[part 1 of 2: packages /CAN4/ISignalGroup to /CAN4/Cluster]
AUTOSAR XML (schema 4-3-0)
package /CAN4/ISignalGroup
  24 x i signal group:
    CAN4_SG_DKC1: i-signal=[CAN4_DKC_P_BLE_RSSI, CAN4_DKC_P_UID_BatVolt, CAN4_DKC_Re_VehData, CAN4_DKC_Remote_PW, CAN4_P_CommandToBCM, CAN4_P_CommandToPTG, CAN4_P_DKey_Area_LockUnlock, CAN4_P_DKey_Area_PS, CAN4_P_DKey_Area_PTG, CAN4_P_DKey_Welcome, CAN4_P_Dkey_Show_IVI, CAN4_P_KeyMiss, CAN4_P_KeyMode, CAN4_P_UID_LowPower], system-signal-group=CAN4_SG_DKC1
    CAN4_SG_DKC2: i-signal=[CAN4_EncryptionDATA_0_63, CAN4_EncryptionDATA_64_127, CAN4_Random_Number_X], system-signal-group=CAN4_SG_DKC2
    CAN4_SG_FD4_CE100_2: i-signal=[CAN4_FD4_CE100_2_CS, CAN4_FD4_CE100_2_RC, CAN4_FDC_VCU_ReqHWReset_Cmd], system-signal-group=CAN4_SG_FD4_CE100_2
    CAN4_SG_FD_DKC1: i-signal=[CAN4_Approach_Unlock_SW, CAN4_BrkPedalPos, CAN4_BrkPedalPos_Sta, CAN4_BrkSw_Sta, CAN4_BrkSw_V, CAN4_DSEAT_anti_set, CAN4_DSEAT_entryfun_set, CAN4_DSEAT_vent_req, CAN4_FDC_BCM_ATCtrl_Cmd, CAN4_FDC_BCM_LockAlarm_Cmd, CAN4_FDC_BCM_OutMode_Cmd, CAN4_FDC_THCM_ACTInitial_Cmd, CAN4_HeadLampSW, CAN4_Hood_Latch_SW, CAN4_IVI_ISA_OffsetSpd, CAN4_IVI_Located_STA, CAN4_IVI_PTG_Mode_SW, CAN4_IVI_PTG_Open_Height, CAN4_IVI_PTG_Sta_SW, CAN4_IVI_PTG_USSta_SW, CAN4_IVI_Time_Check, CAN4_IVI_Time_Day, CAN4_IVI_Time_Hour, CAN4_IVI_Time_Minute, CAN4_IVI_Time_Month, CAN4_IVI_Time_Second, CAN4_IVI_Time_Year, CAN4_L_Drv_CtrlCmd, CAN4_L_Pas_CtrlCmd, CAN4_L_RLD_CtrlCmd, CAN4_L_RRD_CtrlCmd, CAN4_MCPressure, CAN4_MCPressure_V, CAN4_OFF_AC_MODE, CAN4_PSEAT_vent_req, CAN4_PTG_Inner_SW2, CAN4_SenstivityPosition, CAN4_TurnSwTimeSet, CAN4_Walkaway_Lock_SW], system-signal-group=CAN4_SG_FD_DKC1
    CAN4_SG_FD_OTA1: i-signal=[CAN4_OTA_DL_Available, CAN4_OTA_DL_Speed, CAN4_OTA_InVehicle_FW, CAN4_OTA_Lock_Req, CAN4_OTA_MDA_Status, CAN4_OTA_Mode, CAN4_OTA_Network_Type, CAN4_OTA_Progress_Rate, CAN4_OTA_TBOXResetReq, CAN4_OTA_Up_Backcount, CAN4_OTA_Update_Available, CAN4_OTA_Updating_ECU], system-signal-group=CAN4_SG_FD_OTA1
    CAN4_SG_FD_THCM1: i-signal=[CAN4_BatteryMode, CAN4_CCU_ACLampSts, CAN4_CCU_ACMaxLampSts, CAN4_CCU_AutoLampSts, CAN4_CCU_AutoMidLampSts, CAN4_CCU_Dispaly_Request, CAN4_CCU_EcoSts, CAN4_CCU_FrtOnOffLampSts, CAN4_CCU_HEATMaxLampSts, CAN4_CCU_RrOnOffLampSts, CAN4_CCU_SyncLampSts, CAN4_CabinMode, CAN4_EDriveMode, CAN4_FD_AGS_Cmd, CAN4_FD_RecyAuto_Cmd, CAN4_Fr_Coolantflow, CAN4_Fr_Coolanttemp, CAN4_HPThermalRecoveryReq, CAN4_Rr_Coolantflow, CAN4_Rr_Coolanttemp, CAN4_sigAirIntenZon1St, CAN4_sigAirIntenZon3St, CAN4_sigAmbAirT, CAN4_sigCbnAirT, CAN4_sigCbnPTCPwrAct, CAN4_sigCbnSolarLeft, CAN4_sigCbnSolarRight, CAN4_sigClmtCmprPwrAct, CAN4_sigClntTHvBattOut, CAN4_sigDfrstSt, CAN4_sigHvacSt, CAN4_sigRecircSt, CAN4_sigSetTempZon1St, CAN4_sigSetTempZon2St, CAN4_sigSetTempZon3St, CAN4_sigWindDirZon1St, CAN4_sigWindDirZon3St], system-signal-group=CAN4_SG_FD_THCM1
    CAN4_SG_FD_THCM2: i-signal=[CAN4_ACSubMode, CAN4_APTC_ActFrRiPwr, CAN4_BatLoopActWtFlw, CAN4_CCU_CbnPreACWkSts, CAN4_CCU_CbnPreEstimdTi, CAN4_CCU_CbnPreSts, CAN4_CCU_HiVoltageReq, CAN4_CoolgFanActDuty, CAN4_DeiceModReq, CAN4_FD_Blower_Cmd, CAN4_FD_Comp_Cmd, CAN4_FD_EWP1_Cmd, CAN4_FD_EWP2_Cmd, CAN4_FD_EWP3_Cmd, CAN4_FD_EXV1_Cmd, CAN4_FD_EXV2_Cmd, CAN4_FD_FWV_Cmd, CAN4_FD_FrLeAPTCHeatPwr_Cmd, CAN4_FD_FrRiAPTCHeatPwr_Cmd, CAN4_FD_FrWPTCHeatPwr_Cmd, CAN4_FD_RrAPTCHeatPwr_Cmd, CAN4_FD_SOTXV_Cmd, CAN4_FD_SOV1_Cmd, CAN4_FD_SOV2_Cmd, CAN4_FD_SOV3_Cmd, CAN4_FD_TWV_Cmd], system-signal-group=CAN4_SG_FD_THCM2
    CAN4_SG_FD_VCU1: i-signal=[CAN4_AllDoorSW, CAN4_AmbLightBreath1, CAN4_AmbLightBreath2, CAN4_AmbLightBreath3, CAN4_AmbLightBrightness1, CAN4_AmbLightBrightness2, CAN4_AmbLightBrightness3, CAN4_AmbLightColor1, CAN4_AmbLightColor2, CAN4_AmbLightColor3, CAN4_AntiTheftSeatFold, CAN4_AntitheftSta, CAN4_BCM_Buzzer_Req, CAN4_BCM_DoorLock_Sta, CAN4_BrakeLamp, CAN4_CC_Crl_Sta, CAN4_CS_VCU1_CAN4, CAN4_CTDCtrl, CAN4_CTDLockSW, CAN4_CTDUnlockSW, CAN4_CrashDetd, CAN4_CtrlDrPwrStbA2, CAN4_CtrlFrBMSCCUCIR, CAN4_CtrlFrEDUINVERTER, CAN4_CtrlFrIRC1, CAN4_CtrlFrPwrStbA1P, CAN4_DKCAuthSta, CAN4_DKCTimeSN, CAN4_Dimmer, CAN4_DimmerEN, CAN4_DoorLockIND, CAN4_DrDoorSW, CAN4_Dr_SeatSta, CAN4_EquivAccPedalSWSta, CAN4_FD_DKC_VehData_Err, CAN4_FD_DKC_VehData_Sta, CAN4_FD_TBOX_DTCData_Err, CAN4_FD_TBOX_DTCData_Sta, CAN4_FD_TBOX_VehData_Err, CAN4_FD_TBOX_VehData_Sta, CAN4_Fr_ChargingDoorCtrl, CAN4_Fr_FogLamp, CAN4_Fr_Wiper_H, CAN4_Fr_Wiper_L, CAN4_HWResetSta, CAN4_H_Beam, CAN4_HazardSW, CAN4_HoodSW, CAN4_HornCtrl, CAN4_LBSD, CAN4_LDRL, CAN4_LTurnLP, CAN4_L_APM_WdwEnable, CAN4_L_Beam, CAN4_LampPwr, CAN4_LockSetting, CAN4_MSA_Crl_Sta, CAN4_MirrorCtrl, CAN4_MirrorDefog, CAN4_PosLamp, CAN4_PsDoorSW, CAN4_PwrSta, CAN4_RBSD, CAN4_RC_VCU1_CAN4, CAN4_RDRL, CAN4_RLDoorSW, CAN4_RRDoorSW, CAN4_RTurnLP, CAN4_ReBrakeLPReq, CAN4_ReverseLamp, CAN4_RoomLampH, CAN4_RoomLampL, CAN4_Rr_ChargingDoorCtrl, CAN4_Rr_Defog, CAN4_Rr_FogLamp, CAN4_Rr_Wiper, CAN4_ShiftGearPosn, CAN4_TailgateHDSW, CAN4_TailgateRemote, CAN4_Tailgate_SW, CAN4_TimeSNDKCFbk, CAN4_TrunkRel, CAN4_VehSpeed, CAN4_WasherCtrl, CAN4_WiperFixMode], system-signal-group=CAN4_SG_FD_VCU1
    CAN4_SG_GW_ZDR_PTG1: i-signal=[CAN4_PTG_Active_Sta, CAN4_PTG_AutoStaus, CAN4_PTG_Cinch_Current, CAN4_PTG_Exist, CAN4_PTG_Full_Lock, CAN4_PTG_HW_Ver, CAN4_PTG_Half_Lock, CAN4_PTG_Inner_SW_1, CAN4_PTG_Is_Set_Height, CAN4_PTG_Open_Ratio, CAN4_PTG_RDIL_Sta, CAN4_PTG_SW_Ver, CAN4_PTG_Strut_Current, CAN4_PTG_Sys_Sta, CAN4_PTG_Warning_Sta], system-signal-group=CAN4_SG_GW_ZDR_PTG1
    CAN4_SG_GW_ZoneDR1: i-signal=[CAN4_AllLockSta, CAN4_AutoLightSW, CAN4_BrakeLampFail, CAN4_CSW_DimSw, CAN4_CSW_FWasSw_Sta, CAN4_CSW_FWipSw_Sta, CAN4_CSW_HW_version, CAN4_CSW_PassSW_Sta, CAN4_CSW_RWasSW_Sta, CAN4_CSW_RWipIntSw_Sta, CAN4_CSW_SW_version, CAN4_CSW_TurnSw_Sta, CAN4_CSW_resp_error, CAN4_DrLockSta, CAN4_HornSW, CAN4_MIRROR_FOLD_SW, CAN4_PsLockSta, CAN4_RLLockSta, CAN4_RLS_Exist, CAN4_RLS_LIN_Resp_Err, CAN4_RLS_Lamp_Sta, CAN4_RLS_LightSnrErr, CAN4_RLS_RainSnrErr, CAN4_RLS_RainSnrWiperCmd, CAN4_RLTurnLampC, CAN4_RRLockSta, CAN4_RRTurnLampC, CAN4_RWiperAS, CAN4_RWiperProtection, CAN4_Wip_Speed, CAN4_WiperSWPos, CAN4_WiperZeroPosSW], system-signal-group=CAN4_SG_GW_ZoneDR1
    CAN4_SG_GW_ZoneDR2: i-signal=[CAN4_SWC_ACC_Sta, CAN4_SWC_A_HW_version, CAN4_SWC_A_Resp_Err, CAN4_SWC_A_SW_version, CAN4_SWC_CANCEL_Sta, CAN4_SWC_Distance_Sta, CAN4_SWC_Down_Sta, CAN4_SWC_Drivemode_Sta, CAN4_SWC_LKA_Sta, CAN4_SWC_Left_Sta, CAN4_SWC_RegenDown, CAN4_SWC_RegenUp, CAN4_SWC_Res_Up_Sta, CAN4_SWC_Right_Sta, CAN4_SWC_Set_down_Sta, CAN4_SWC_Trip_Sta, CAN4_SWC_Undefined_Sta, CAN4_SWC_Up_Sta, CAN4_SWC_VR_Sta, CAN4_SWC_mode_Sta, CAN4_SWC_resp_error], system-signal-group=CAN4_SG_GW_ZoneDR2
    CAN4_SG_GW_ZoneDR3: i-signal=[CAN4_FAPWL_01_LIN_Response_Error, CAN4_L_APM_IntellectClose, CAN4_L_Drv_Motor_Relay_Error, CAN4_L_Drv_Motor_Ripple_Error, CAN4_L_Drv_OverHeat_Protect, CAN4_L_Drv_Val_Wdw_Opened, CAN4_L_Drv_Wdw_Init, CAN4_L_Drv_Wdw_LocalSwitch, CAN4_L_Drv_Wdw_OD_Sts, CAN4_L_Drv_Wdw_Obs_InhibitSts, CAN4_L_Drv_Wdw_Pas_Switch, CAN4_L_Drv_Wdw_PositionSts, CAN4_L_Drv_Wdw_RLD_Switch, CAN4_L_Drv_Wdw_RRD_Switch, CAN4_L_Drv_Wdw_Running_Sts, CAN4_L_Pas_Motor_Relay_Error, CAN4_L_Pas_Motor_Ripple_Error, CAN4_L_Pas_OverHeat_Protect, CAN4_L_Pas_Val_Wdw_Opened, CAN4_L_Pas_Wdw_Init, CAN4_L_Pas_Wdw_LocalSwitch, CAN4_L_Pas_Wdw_OD_Sts, CAN4_L_Pas_Wdw_Obs_InhibitSts, CAN4_L_Pas_Wdw_PositionSts, CAN4_L_Pas_Wdw_Running_Sts, CAN4_L_Power_Status], system-signal-group=CAN4_SG_GW_ZoneDR3
    CAN4_SG_GW_ZoneDR4: i-signal=[CAN4_L_RLD_Motor_Relay_Error, CAN4_L_RLD_Motor_Ripple_Error, CAN4_L_RLD_OverHeat_Protect, CAN4_L_RLD_Val_Wdw_Opened, CAN4_L_RLD_Wdw_Init, CAN4_L_RLD_Wdw_LocalSwitch, CAN4_L_RLD_Wdw_OD_Sts, CAN4_L_RLD_Wdw_Obs_InhibitSts, CAN4_L_RLD_Wdw_PositionSts, CAN4_L_RLD_Wdw_Running_Sts, CAN4_L_RRD_Motor_Relay_Error, CAN4_L_RRD_Motor_Ripple_Error, CAN4_L_RRD_OverHeat_Protect, CAN4_L_RRD_Val_Wdw_Opened, CAN4_L_RRD_Wdw_Init, CAN4_L_RRD_Wdw_LocalSwitch, CAN4_L_RRD_Wdw_OD_Sts, CAN4_L_RRD_Wdw_Obs_InhibitSts, CAN4_L_RRD_Wdw_PositionSts, CAN4_L_RRD_Wdw_Running_Sts, CAN4_PTG_Inner_SW_2, CAN4_RAPWL_01_LIN_Response_Error], system-signal-group=CAN4_SG_GW_ZoneDR4
    CAN4_SG_GW_ZoneDR6: i-signal=[CAN4_FrntPTCBusLineHiV, CAN4_FrntPTCComFlt, CAN4_FrntPTCFltSt, CAN4_FrntPTCHVOverUFlt, CAN4_FrntPTCHVUnderUFlt, CAN4_FrntPTCHWVers, CAN4_FrntPTCLVOverUFlt, CAN4_FrntPTCLVUnderUFlt, CAN4_FrntPTCLeActHeatPwr, CAN4_FrntPTCLeBusLineC, CAN4_FrntPTCLeCoreOverTFlt, CAN4_FrntPTCLeCoreT, CAN4_FrntPTCLeCoreTSnsrFlt, CAN4_FrntPTCLeIGBTOverTFlt, CAN4_FrntPTCLeIGBTShoCircFlt, CAN4_FrntPTCLeIGBTT, CAN4_FrntPTCLeIGBTTSnsrFlt, CAN4_FrntPTCLeOpentCircFlt, CAN4_FrntPTCLeOverAFlt, CAN4_FrntPTCPCBOverTFlt, CAN4_FrntPTCPCBT, CAN4_FrntPTCPCBTSnsrFlt, CAN4_FrntPTCRearLeActHeatPwr, CAN4_FrntPTCRearLeBusLineC, CAN4_FrntPTCRearLeCoreOverTFlt, CAN4_FrntPTCRearLeCoreT, CAN4_FrntPTCRearLeCoreTSnsrFlt, CAN4_FrntPTCRearLeIGBTShoCFlt, CAN4_FrntPTCRearLeOpentCircFlt, CAN4_FrntPTCRearLeOverAFlt, CAN4_FrntPTCRearRiActHeatPwr, CAN4_FrntPTCRearRiBusLineC, CAN4_FrntPTCRearRiCoreOverTFlt, CAN4_FrntPTCRearRiCoreT, CAN4_FrntPTCRearRiCoreTSnsrFlt, CAN4_FrntPTCRearRiIGBTShoCFlt, CAN4_FrntPTCRearRiOpentCircFlt, CAN4_FrntPTCRearRiOverAFlt, CAN4_FrntPTCRiActHeatPwr, CAN4_FrntPTCRiBusLineC, CAN4_FrntPTCRiCoreOverTFlt, CAN4_FrntPTCRiCoreT, CAN4_FrntPTCRiCoreTSnsrFlt, CAN4_FrntPTCRiIGBTOverTFlt, CAN4_FrntPTCRiIGBTShoCircFlt, CAN4_FrntPTCRiIGBTT, CAN4_FrntPTCRiIGBTTSnsrFlt, CAN4_FrntPTCRiOpentCircFlt, CAN4_FrntPTCRiOverAFlt, CAN4_FrntPTCSWVers, CAN4_FrntPTCSts, CAN4_FrntPTCSupplierCod], system-signal-group=CAN4_SG_GW_ZoneDR6
    CAN4_SG_GW_ZoneFR1: i-signal=[CAN4_AGS_Actual_Position, CAN4_AGS_Actuator_Blocked, CAN4_AGS_Actuator_Fault, CAN4_AGS_Calibration_Active, CAN4_AGS_Calibration_Enabled, CAN4_AGS_Calibration_Indicated, CAN4_AGS_Electrical_Error, CAN4_AGS_LINResponse_Error, CAN4_AGS_Low_Voltage_Error, CAN4_AGS_Position_Request, CAN4_AGS_Sensor_Error, CAN4_AGS_Temperature_Error, CAN4_BDC_1_MoveEnable, CAN4_BDC_1_ReqMovePos, CAN4_CCV4_MoveEnable, CAN4_CCV4_ReqMovePos, CAN4_ChargeInletLockSta, CAN4_EWP1_Default_Operation_EWP_Rq, CAN4_EWP1_RPM_Target_EWP_Rq, CAN4_EWP2_Default_Operation_EWP_Rq, CAN4_EWP2_RPM_Target_EWP_Rq, CAN4_EWP3_Default_Operation_EWP_Rq, CAN4_EWP3_RPM_Target_EWP_Rq, CAN4_EXV2_Cmd_Init_Rq, CAN4_EXV2_Cmd_Move_Enbl, CAN4_EXV2_Cmd_Set_Rq, CAN4_EXV_Cmd_Init_Rq, CAN4_EXV_Cmd_Move_Enbl, CAN4_EXV_Cmd_Set_Rq, CAN4_FLTurnLampC, CAN4_FRTurnLampC, CAN4_FWiperAS, CAN4_FWiperProtection], system-signal-group=CAN4_SG_GW_ZoneFR1
    CAN4_SG_GW_ZoneFR2: i-signal=[CAN4_BMSPackVol_h6HSC6, CAN4_CCM_SpdCmd, CAN4_COMP_ComLost, CAN4_COMP_ConCur, CAN4_COMP_ConVolt, CAN4_COMP_CtrlCircFlt, CAN4_COMP_CurOverProtect, CAN4_COMP_CurVaild, CAN4_COMP_IPM_HWFLt, CAN4_COMP_IPM_TempOverFlt, CAN4_COMP_Init, CAN4_COMP_SpdVaild, CAN4_COMP_Sta, CAN4_COMP_StatorSpd, CAN4_COMP_VoltLessErr, CAN4_COMP_VoltOverErr, CAN4_COMP_VoltVaild, CAN4_CompProEN, CAN4_EAC_DrvVoltFalt, CAN4_EAC_MotCrt, CAN4_EAC_MotorLackFalt, CAN4_EAC_OvLoadFalt, CAN4_EAC_Temp, CAN4_EAC_TempSnsrFalt, CAN4_PTCActuCrntHSC6, CAN4_PTCActuPWMDutyHSC6, CAN4_PTCActuVolHSC6, CAN4_PTCChksmHSC6, CAN4_PTCFltLvlHSC6, CAN4_PTCHVLckStsHSC6, CAN4_PTCIGBTOverHeatHSC6, CAN4_PTCIGBTStsHSC6, CAN4_PTCIGBTTemHSC6, CAN4_PTCNTCStsHSC6, CAN4_PTCOtptTemHSC6, CAN4_PTCOverCrntHSC6, CAN4_PTCOverHeatHSC6, CAN4_PTCOverVolHSC6, CAN4_PTCPCBTemHSC6, CAN4_PTCRlngCtrHSC6, CAN4_PTCSecChksmHSC6, CAN4_PTCSecRlngCtrHSC6, CAN4_PTCStsHSC6, CAN4_PTCUnderVolHSC6], system-signal-group=CAN4_SG_GW_ZoneFR2
    CAN4_SG_XNMm_DKC: i-signal=[CAN4_NM_DKC_Active_WU, CAN4_NM_DKC_CSB, CAN4_NM_DKC_ERROR_State, CAN4_NM_DKC_Node_ID, CAN4_NM_DKC_PNI, CAN4_NM_DKC_Rpt_Msg_Req], system-signal-group=CAN4_SG_XNMm_DKC
    CAN4_SG_XNMm_FUSION: i-signal=[CAN4_NM_FUSION_Active_WU, CAN4_NM_FUSION_CSB, CAN4_NM_FUSION_ERROR_State, CAN4_NM_FUSION_Node_ID, CAN4_NM_FUSION_PNI, CAN4_NM_FUSION_Rpt_Msg_Req], system-signal-group=CAN4_SG_XNMm_FUSION
    CAN4_SG_XNMm_ZONE_DR: i-signal=[CAN4_NM_ZONE_DR_Active_WU, CAN4_NM_ZONE_DR_CSB, CAN4_NM_ZONE_DR_ERROR_State, CAN4_NM_ZONE_DR_Node_ID, CAN4_NM_ZONE_DR_PNI, CAN4_NM_ZONE_DR_Rpt_Msg_Req], system-signal-group=CAN4_SG_XNMm_ZONE_DR
    CAN4_SG_XNMm_ZONE_FR: i-signal=[CAN4_NM_ZONE_FR_Active_WU, CAN4_NM_ZONE_FR_CSB, CAN4_NM_ZONE_FR_ERROR_State, CAN4_NM_ZONE_FR_Node_ID, CAN4_NM_ZONE_FR_PNI, CAN4_NM_ZONE_FR_Rpt_Msg_Req], system-signal-group=CAN4_SG_XNMm_ZONE_FR
    CAN4_SG_Zone_Dr_SCP: i-signal=[CAN4_DrSCPSysErrLmp, CAN4_RegenMode, CAN4_Set_Spd, CAN4_Zone_Spd_Ctrl_Mode, CAN4_Zone_Spd_Ctrl_Sta], system-signal-group=CAN4_SG_Zone_Dr_SCP
    CAN4_SG_Zone_Dr_THCM: i-signal=[CAN4_APTC_Err, CAN4_Blower_Err, CAN4_Blower_FB, CAN4_SolarL, CAN4_SolarL_Err, CAN4_SolarR, CAN4_SolarR_Err, CAN4_T_Face_L, CAN4_T_Face_L_Err, CAN4_T_Face_R, CAN4_T_Face_R_Err, CAN4_T_Face_Rr, CAN4_T_Face_Rr_Err, CAN4_T_Foot_L, CAN4_T_Foot_L_Err, CAN4_T_Foot_R, CAN4_T_Foot_R_Err, CAN4_T_Foot_Rr, CAN4_T_Foot_Rr_Err, CAN4_Tevap, CAN4_Tevap_Err, CAN4_Tincar, CAN4_Tincar_Err, CAN4_ZDR_THCM_IntakeFail_Sta, CAN4_ZDR_THCM_LINACT1_Sta, CAN4_ZDR_THCM_LINACT2_Sta, CAN4_ZDR_THCM_LINACT3_Sta, CAN4_ZDR_THCM_LINACT4_Sta, CAN4_ZDR_THCM_LINACT5_Sta, CAN4_ZDR_THCM_ModeFail_Sta], system-signal-group=CAN4_SG_Zone_Dr_THCM
    CAN4_SG_Zone_Dr_VCU: i-signal=[CAN4_DrAPWLINErr, CAN4_DrAPWStaErr, CAN4_DrAuBoxPwrN1Curr, CAN4_DrAuBoxPwrN2Curr, CAN4_DrColumnSWFault, CAN4_DrCtrlBDVolt, CAN4_DrCtrlTemp, CAN4_DrEOBDFault, CAN4_DrIVIFault, CAN4_DrInfoErrSta, CAN4_DrInfoFault, CAN4_DrONA1ErrSta, CAN4_DrPMMLVOutPErrLmp, CAN4_DrPMMLimpHomeActReq, CAN4_DrPMMSysErrLmp, CAN4_DrPowerTemp1, CAN4_DrPowerTemp2, CAN4_DrPwrInformationSta, CAN4_DrPwrONA1Curr, CAN4_DrPwrONA2Curr, CAN4_DrPwrSta, CAN4_DrPwrStdbyACurr, CAN4_DrPwrWinErrSta, CAN4_DrPwrWindowECUFault, CAN4_DrStdAErrSta, CAN4_DrTHCMFault, CAN4_ZDR_SYS_APMRetryCnt_Sta, CAN4_ZDR_SYS_BSWSleepReq_Sta, CAN4_ZDR_SYS_CSWRetryCnt_Sta, CAN4_ZDR_VCU_HWReset_Sta, CAN4_ZDR_VCU_PwrSupply_Sta, CAN4_ZoneDrMalfunLevel], system-signal-group=CAN4_SG_Zone_Dr_VCU
    CAN4_SG_Zone_Fr_THCM: i-signal=[CAN4_AGS_Err, CAN4_Bat_In_Temp, CAN4_Bat_In_Temp_Err, CAN4_Bat_Out_Temp, CAN4_Bat_Out_Temp_Err, CAN4_COMP_Err, CAN4_EACProtectEnable, CAN4_EWP1_Err, CAN4_EWP2_Err, CAN4_EWP3_Err, CAN4_EXV1_Err, CAN4_EXV2_Err, CAN4_FWV_Err, CAN4_Fan_Err, CAN4_Motor_In_Temp, CAN4_Motor_In_Temp_Err, CAN4_Motor_Out_Temp, CAN4_Motor_Out_Temp_Err, CAN4_PT_High_P, CAN4_PT_High_P_Err, CAN4_PT_High_T, CAN4_PT_High_Tact, CAN4_PT_High_Tact_Err, CAN4_PT_Low_P1, CAN4_PT_Low_P1_Err, CAN4_PT_Low_P2, CAN4_PT_Low_P2_Err, CAN4_PT_Low_T1, CAN4_PT_Low_T1_Err, CAN4_PT_Low_T2, CAN4_PT_Low_T2_Err, CAN4_SOTXV_Err, CAN4_SOV1_Err, CAN4_SOV2_Err, CAN4_SOV3_Err, CAN4_TWV_Err, CAN4_Tamb, CAN4_Tamb_Err, CAN4_WPTC_Err], system-signal-group=CAN4_SG_Zone_Fr_THCM
package /CAN4/Cluster
  can cluster CAN4: baudrate=500, can-fd-baudrate=2000
    can physical channel CAN4: comm-connectors=ConnCAN4
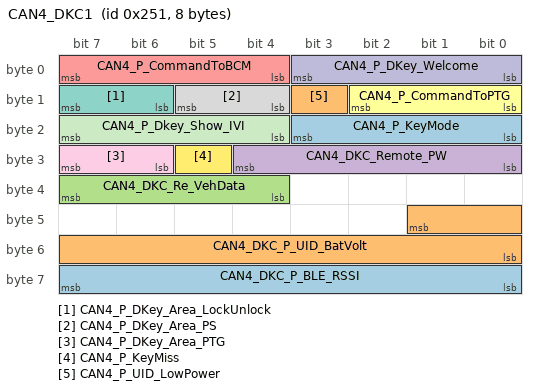
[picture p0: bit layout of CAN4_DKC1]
      frame CAN4_DKC1: id 0x251, frame-length=8, can-addressing-mode=STANDARD, can-fd-frame-support=true, can-frame-rx-behavior=CAN-FD, can-frame-tx-behavior=CAN-FD
        pdu CAN4_DKC1: length=8, minimum-delay=0.0, transmission-mode-true-timing={cyclic-timing=time-period=0.1, event-controlled-timing={number-of-repetitions=0, repetition-period=0.01}}, unused-bit-pattern=0
          mapping CAN4_SG_DKC1: i-signal-group=CAN4_SG_DKC1, start-position=0, transfer-property=TRIGGERED-ON-CHANGE
          signal CAN4_DKC_P_BLE_RSSI: start 63, 8 bit, big-endian, i-signal-type=PRIMITIVE, init-value=constant-reference=Init_CAN4_DKC_P_BLE_RSSI, base-type=uint8, implementation-data-type=uint8, transfer-property=PENDING
          signal CAN4_DKC_P_UID_BatVolt: start 41, 10 bit, big-endian, i-signal-type=PRIMITIVE, init-value=constant-reference=Init_CAN4_DKC_P_UID_BatVolt, base-type=uint16, implementation-data-type=uint16, transfer-property=PENDING
          signal CAN4_DKC_Re_VehData: start 39, 4 bit, big-endian, i-signal-type=PRIMITIVE, init-value=constant-reference=Init_CAN4_DKC_Re_VehData, base-type=uint8, implementation-data-type=uint8, transfer-property=TRIGGERED-ON-CHANGE
          signal CAN4_DKC_Remote_PW: start 28, 5 bit, big-endian, i-signal-type=PRIMITIVE, init-value=constant-reference=Init_CAN4_DKC_Remote_PW, base-type=uint8, implementation-data-type=uint8, transfer-property=PENDING
          signal CAN4_P_CommandToBCM: start 7, 4 bit, big-endian, i-signal-type=PRIMITIVE, init-value=constant-reference=Init_CAN4_P_CommandToBCM, base-type=uint8, implementation-data-type=uint8, transfer-property=PENDING
          signal CAN4_P_CommandToPTG: start 10, 3 bit, big-endian, i-signal-type=PRIMITIVE, init-value=constant-reference=Init_CAN4_P_CommandToPTG, base-type=uint8, implementation-data-type=uint8, transfer-property=PENDING
          signal CAN4_P_DKey_Area_LockUnlock: start 15, 2 bit, big-endian, i-signal-type=PRIMITIVE, init-value=constant-reference=Init_CAN4_P_DKey_Area_LockUnlock, base-type=uint8, implementation-data-type=uint8, transfer-property=PENDING
          signal CAN4_P_DKey_Area_PS: start 13, 2 bit, big-endian, i-signal-type=PRIMITIVE, init-value=constant-reference=Init_CAN4_P_DKey_Area_PS, base-type=uint8, implementation-data-type=uint8, transfer-property=PENDING
          signal CAN4_P_DKey_Area_PTG: start 31, 2 bit, big-endian, i-signal-type=PRIMITIVE, init-value=constant-reference=Init_CAN4_P_DKey_Area_PTG, base-type=uint8, implementation-data-type=uint8, transfer-property=PENDING
          signal CAN4_P_DKey_Welcome: start 3, 4 bit, big-endian, i-signal-type=PRIMITIVE, init-value=constant-reference=Init_CAN4_P_DKey_Welcome, base-type=uint8, implementation-data-type=uint8, transfer-property=PENDING
          signal CAN4_P_Dkey_Show_IVI: start 23, 4 bit, big-endian, i-signal-type=PRIMITIVE, init-value=constant-reference=Init_CAN4_P_Dkey_Show_IVI, base-type=uint8, implementation-data-type=uint8, transfer-property=PENDING
          signal CAN4_P_KeyMiss: start 29, 1 bit, big-endian, i-signal-type=PRIMITIVE, init-value=constant-reference=Init_CAN4_P_KeyMiss, base-type=uint8, implementation-data-type=uint8, transfer-property=PENDING
          signal CAN4_P_KeyMode: start 19, 4 bit, big-endian, i-signal-type=PRIMITIVE, init-value=constant-reference=Init_CAN4_P_KeyMode, base-type=uint8, implementation-data-type=uint8, transfer-property=TRIGGERED-ON-CHANGE
          signal CAN4_P_UID_LowPower: start 11, 1 bit, big-endian, i-signal-type=PRIMITIVE, init-value=constant-reference=Init_CAN4_P_UID_LowPower, base-type=uint8, implementation-data-type=uint8, transfer-property=TRIGGERED-ON-CHANGE
      frame CAN4_DKC2: id 0x252, frame-length=24, can-addressing-mode=STANDARD, can-fd-frame-support=true, can-frame-rx-behavior=CAN-FD, can-frame-tx-behavior=CAN-FD
        pdu CAN4_DKC2: length=24, minimum-delay=0.0, transmission-mode-true-timing={cyclic-timing=time-period=0.1, event-controlled-timing={number-of-repetitions=0, repetition-period=0.01}}, unused-bit-pattern=0
          mapping CAN4_SG_DKC2: i-signal-group=CAN4_SG_DKC2, start-position=0, transfer-property=TRIGGERED-ON-CHANGE
          signal CAN4_EncryptionDATA_0_63: start 135, 64 bit, big-endian, i-signal-type=PRIMITIVE, init-value=constant-reference=Init_CAN4_EncryptionDATA_0_63, base-type=uint64, implementation-data-type=uint64, transfer-property=TRIGGERED-ON-CHANGE
          signal CAN4_EncryptionDATA_64_127: start 71, 64 bit, big-endian, i-signal-type=PRIMITIVE, init-value=constant-reference=Init_CAN4_EncryptionDATA_64_127, base-type=uint64, implementation-data-type=uint64, transfer-property=TRIGGERED-ON-CHANGE
          signal CAN4_Random_Number_X: start 7, 64 bit, big-endian, i-signal-type=PRIMITIVE, init-value=constant-reference=Init_CAN4_Random_Number_X, base-type=uint64, implementation-data-type=uint64, transfer-property=TRIGGERED-ON-CHANGE
      frame CAN4_DiagFuncReqFT: id 0x7D0, frame-length=8, can-addressing-mode=STANDARD, can-fd-frame-support=true, can-frame-rx-behavior=CAN-FD, can-frame-tx-behavior=CAN-FD
        n pdu CAN4_DiagFuncReqFT: length=8
      frame CAN4_DiagPhysReqToAirPTC: id 0x6A5, frame-length=8, can-addressing-mode=STANDARD, can-fd-frame-support=true, can-frame-rx-behavior=CAN-FD, can-frame-tx-behavior=CAN-FD
        n pdu CAN4_DiagPhysReqToAirPTC: length=8
      frame CAN4_DiagPhysReqToCompressor: id 0x6C5, frame-length=8, can-addressing-mode=STANDARD, can-fd-frame-support=true, can-frame-rx-behavior=CAN-FD, can-frame-tx-behavior=CAN-FD
        n pdu CAN4_DiagPhysReqToCompressor: length=8
      frame CAN4_DiagPhysReqToDKC: id 0x685, frame-length=8, can-addressing-mode=STANDARD, can-fd-frame-support=true, can-frame-rx-behavior=CAN-FD, can-frame-tx-behavior=CAN-FD
        n pdu CAN4_DiagPhysReqToDKC: length=8
      frame CAN4_DiagPhysReqToDSEAT: id 0x694, frame-length=8, can-addressing-mode=STANDARD, can-fd-frame-support=true, can-frame-rx-behavior=CAN-FD, can-frame-tx-behavior=CAN-FD
        n pdu CAN4_DiagPhysReqToDSEAT: length=8
      frame CAN4_DiagPhysReqToPSEAT: id 0x6A4, frame-length=8, can-addressing-mode=STANDARD, can-fd-frame-support=true, can-frame-rx-behavior=CAN-FD, can-frame-tx-behavior=CAN-FD
        n pdu CAN4_DiagPhysReqToPSEAT: length=8
      frame CAN4_DiagPhysReqToPTG: id 0x6B4, frame-length=8, can-addressing-mode=STANDARD, can-fd-frame-support=true, can-frame-rx-behavior=CAN-FD, can-frame-tx-behavior=CAN-FD
        n pdu CAN4_DiagPhysReqToPTG: length=8
      frame CAN4_DiagPhysReqToZONE_DR: id 0x6C0, frame-length=64, can-addressing-mode=STANDARD, can-fd-frame-support=true, can-frame-rx-behavior=CAN-FD, can-frame-tx-behavior=CAN-FD
        n pdu CAN4_DiagPhysReqToZONE_DR: length=64
      frame CAN4_DiagPhysReqToZONE_FR: id 0x684, frame-length=64, can-addressing-mode=STANDARD, can-fd-frame-support=true, can-frame-rx-behavior=CAN-FD, can-frame-tx-behavior=CAN-FD
        n pdu CAN4_DiagPhysReqToZONE_FR: length=64
      frame CAN4_DiagRespFromAirPTC: id 0x625, frame-length=8, can-addressing-mode=STANDARD, can-fd-frame-support=true, can-frame-rx-behavior=CAN-FD, can-frame-tx-behavior=CAN-FD
        n pdu CAN4_DiagRespFromAirPTC: length=8
      frame CAN4_DiagRespFromCompressor: id 0x645, frame-length=8, can-addressing-mode=STANDARD, can-fd-frame-support=true, can-frame-rx-behavior=CAN-FD, can-frame-tx-behavior=CAN-FD
        n pdu CAN4_DiagRespFromCompressor: length=8
      frame CAN4_DiagRespFromDKC: id 0x605, frame-length=8, can-addressing-mode=STANDARD, can-fd-frame-support=true, can-frame-rx-behavior=CAN-FD, can-frame-tx-behavior=CAN-FD
        n pdu CAN4_DiagRespFromDKC: length=8
      frame CAN4_DiagRespFromDSEAT: id 0x614, frame-length=8, can-addressing-mode=STANDARD, can-fd-frame-support=true, can-frame-rx-behavior=CAN-FD, can-frame-tx-behavior=CAN-FD
        n pdu CAN4_DiagRespFromDSEAT: length=8
      frame CAN4_DiagRespFromPSEAT: id 0x624, frame-length=8, can-addressing-mode=STANDARD, can-fd-frame-support=true, can-frame-rx-behavior=CAN-FD, can-frame-tx-behavior=CAN-FD
        n pdu CAN4_DiagRespFromPSEAT: length=8
      frame CAN4_DiagRespFromPTG: id 0x634, frame-length=8, can-addressing-mode=STANDARD, can-fd-frame-support=true, can-frame-rx-behavior=CAN-FD, can-frame-tx-behavior=CAN-FD
        n pdu CAN4_DiagRespFromPTG: length=8
      frame CAN4_DiagRespFromZONE_DR: id 0x640, frame-length=64, can-addressing-mode=STANDARD, can-fd-frame-support=true, can-frame-rx-behavior=CAN-FD, can-frame-tx-behavior=CAN-FD
        n pdu CAN4_DiagRespFromZONE_DR: length=64
      frame CAN4_DiagRespFromZONE_FR: id 0x604, frame-length=64, can-addressing-mode=STANDARD, can-fd-frame-support=true, can-frame-rx-behavior=CAN-FD, can-frame-tx-behavior=CAN-FD
        n pdu CAN4_DiagRespFromZONE_FR: length=64
      frame CAN4_FD4_CE100_2: id 0x3A0, frame-length=32, can-addressing-mode=STANDARD, can-fd-frame-support=true, can-frame-rx-behavior=CAN-FD, can-frame-tx-behavior=CAN-FD
        pdu CAN4_FD4_CE100_2: length=32, minimum-delay=0.0, transmission-mode-true-timing={cyclic-timing=time-period=0.1, event-controlled-timing={number-of-repetitions=0, repetition-period=0}}, unused-bit-pattern=0
          mapping CAN4_SG_FD4_CE100_2: i-signal-group=CAN4_SG_FD4_CE100_2, start-position=0, transfer-property=TRIGGERED-ON-CHANGE
          signal CAN4_FD4_CE100_2_CS: start 7, 8 bit, big-endian, i-signal-type=PRIMITIVE, init-value=constant-reference=Init_CAN4_FD4_CE100_2_CS, base-type=uint8, implementation-data-type=uint8, transfer-property=TRIGGERED-ON-CHANGE
          signal CAN4_FD4_CE100_2_RC: start 11, 4 bit, big-endian, i-signal-type=PRIMITIVE, init-value=constant-reference=Init_CAN4_FD4_CE100_2_RC, base-type=uint8, implementation-data-type=uint8, transfer-property=TRIGGERED-ON-CHANGE
          signal CAN4_FDC_VCU_ReqHWReset_Cmd: start 20, 5 bit, big-endian, i-signal-type=PRIMITIVE, init-value=constant-reference=Init_CAN4_FDC_VCU_ReqHWReset_Cmd, base-type=uint8, implementation-data-type=uint8, transfer-property=TRIGGERED-ON-CHANGE
      frame CAN4_FD_DKC1: id 0x253, frame-length=32, can-addressing-mode=STANDARD, can-fd-frame-support=true, can-frame-rx-behavior=CAN-FD, can-frame-tx-behavior=CAN-FD
        pdu CAN4_FD_DKC1: length=32, minimum-delay=0.0, transmission-mode-true-timing={cyclic-timing=time-period=0.1, event-controlled-timing={number-of-repetitions=0, repetition-period=0.01}}, unused-bit-pattern=0
          mapping CAN4_SG_FD_DKC1: i-signal-group=CAN4_SG_FD_DKC1, start-position=0, transfer-property=TRIGGERED-ON-CHANGE
          signal CAN4_Approach_Unlock_SW: start 15, 1 bit, big-endian, i-signal-type=PRIMITIVE, init-value=constant-reference=Init_CAN4_Approach_Unlock_SW, base-type=uint8, implementation-data-type=uint8, transfer-property=TRIGGERED-ON-CHANGE
          signal CAN4_BrkPedalPos: start 135, 8 bit, big-endian, i-signal-type=PRIMITIVE, init-value=constant-reference=Init_CAN4_BrkPedalPos, base-type=uint8, implementation-data-type=uint8, transfer-property=PENDING
          signal CAN4_BrkPedalPos_Sta: start 108, 1 bit, big-endian, i-signal-type=PRIMITIVE, init-value=constant-reference=Init_CAN4_BrkPedalPos_Sta, base-type=uint8, implementation-data-type=uint8, transfer-property=TRIGGERED-ON-CHANGE
          signal CAN4_BrkSw_Sta: start 31, 1 bit, big-endian, i-signal-type=PRIMITIVE, init-value=constant-reference=Init_CAN4_BrkSw_Sta, base-type=uint8, implementation-data-type=uint8, transfer-property=TRIGGERED-ON-CHANGE
          signal CAN4_BrkSw_V: start 71, 1 bit, big-endian, i-signal-type=PRIMITIVE, init-value=constant-reference=Init_CAN4_BrkSw_V, base-type=uint8, implementation-data-type=uint8, transfer-property=TRIGGERED-ON-CHANGE
          signal CAN4_DSEAT_anti_set: start 39, 1 bit, big-endian, i-signal-type=PRIMITIVE, init-value=constant-reference=Init_CAN4_DSEAT_anti_set, base-type=uint8, implementation-data-type=uint8, transfer-property=PENDING
          signal CAN4_DSEAT_entryfun_set: start 47, 1 bit, big-endian, i-signal-type=PRIMITIVE, init-value=constant-reference=Init_CAN4_DSEAT_entryfun_set, base-type=uint8, implementation-data-type=uint8, transfer-property=PENDING
          signal CAN4_DSEAT_vent_req: start 95, 3 bit, big-endian, i-signal-type=PRIMITIVE, init-value=constant-reference=Init_CAN4_DSEAT_vent_req, base-type=uint8, implementation-data-type=uint8, transfer-property=PENDING
          signal CAN4_FDC_BCM_ATCtrl_Cmd: start 143, 2 bit, big-endian, i-signal-type=PRIMITIVE, init-value=constant-reference=Init_CAN4_FDC_BCM_ATCtrl_Cmd, base-type=uint8, implementation-data-type=uint8, transfer-property=TRIGGERED-ON-CHANGE
          signal CAN4_FDC_BCM_LockAlarm_Cmd: start 119, 2 bit, big-endian, i-signal-type=PRIMITIVE, init-value=constant-reference=Init_CAN4_FDC_BCM_LockAlarm_Cmd, base-type=uint8, implementation-data-type=uint8, transfer-property=TRIGGERED-ON-CHANGE
          signal CAN4_FDC_BCM_OutMode_Cmd: start 139, 4 bit, big-endian, i-signal-type=PRIMITIVE, init-value=constant-reference=Init_CAN4_FDC_BCM_OutMode_Cmd, base-type=uint8, implementation-data-type=uint8, transfer-property=TRIGGERED-ON-CHANGE
          signal CAN4_FDC_THCM_ACTInitial_Cmd: start 117, 1 bit, big-endian, i-signal-type=PRIMITIVE, init-value=constant-reference=Init_CAN4_FDC_THCM_ACTInitial_Cmd, base-type=uint8, implementation-data-type=uint8, transfer-property=TRIGGERED-ON-CHANGE
          signal CAN4_HeadLampSW: start 102, 2 bit, big-endian, i-signal-type=PRIMITIVE, init-value=constant-reference=Init_CAN4_HeadLampSW, base-type=uint8, implementation-data-type=uint8, transfer-property=TRIGGERED-ON-CHANGE
          signal CAN4_Hood_Latch_SW: start 79, 2 bit, big-endian, i-signal-type=PRIMITIVE, init-value=constant-reference=Init_CAN4_Hood_Latch_SW, base-type=uint8, implementation-data-type=uint8, transfer-property=PENDING
          signal CAN4_IVI_ISA_OffsetSpd: start 55, 4 bit, big-endian, i-signal-type=PRIMITIVE, init-value=constant-reference=Init_CAN4_IVI_ISA_OffsetSpd, base-type=uint8, implementation-data-type=uint8, transfer-property=PENDING
          signal CAN4_IVI_Located_STA: start 7, 2 bit, big-endian, i-signal-type=PRIMITIVE, init-value=constant-reference=Init_CAN4_IVI_Located_STA, base-type=uint8, implementation-data-type=uint8, transfer-property=PENDING
          signal CAN4_IVI_PTG_Mode_SW: start 46, 2 bit, big-endian, i-signal-type=PRIMITIVE, init-value=constant-reference=Init_CAN4_IVI_PTG_Mode_SW, base-type=uint8, implementation-data-type=uint8, transfer-property=TRIGGERED-ON-CHANGE
          signal CAN4_IVI_PTG_Open_Height: start 2, 3 bit, big-endian, i-signal-type=PRIMITIVE, init-value=constant-reference=Init_CAN4_IVI_PTG_Open_Height, base-type=uint8, implementation-data-type=uint8, transfer-property=TRIGGERED-ON-CHANGE
          signal CAN4_IVI_PTG_Sta_SW: start 41, 2 bit, big-endian, i-signal-type=PRIMITIVE, init-value=constant-reference=Init_CAN4_IVI_PTG_Sta_SW, base-type=uint8, implementation-data-type=uint8, transfer-property=TRIGGERED-ON-CHANGE
          signal CAN4_IVI_PTG_USSta_SW: start 3, 1 bit, big-endian, i-signal-type=PRIMITIVE, init-value=constant-reference=Init_CAN4_IVI_PTG_USSta_SW, base-type=uint8, implementation-data-type=uint8, transfer-property=PENDING
          signal CAN4_IVI_Time_Check: start 63, 8 bit, big-endian, i-signal-type=PRIMITIVE, init-value=constant-reference=Init_CAN4_IVI_Time_Check, base-type=uint8, implementation-data-type=uint8, transfer-property=PENDING
          signal CAN4_IVI_Time_Day: start 92, 5 bit, big-endian, i-signal-type=PRIMITIVE, init-value=constant-reference=Init_CAN4_IVI_Time_Day, base-type=uint8, implementation-data-type=uint8, transfer-property=PENDING
          signal CAN4_IVI_Time_Hour: start 100, 5 bit, big-endian, i-signal-type=PRIMITIVE, init-value=constant-reference=Init_CAN4_IVI_Time_Hour, base-type=uint8, implementation-data-type=uint8, transfer-property=PENDING
          signal CAN4_IVI_Time_Minute: start 77, 6 bit, big-endian, i-signal-type=PRIMITIVE, init-value=constant-reference=Init_CAN4_IVI_Time_Minute, base-type=uint8, implementation-data-type=uint8, transfer-property=PENDING
          signal CAN4_IVI_Time_Month: start 107, 4 bit, big-endian, i-signal-type=PRIMITIVE, init-value=constant-reference=Init_CAN4_IVI_Time_Month, base-type=uint8, implementation-data-type=uint8, transfer-property=PENDING
          signal CAN4_IVI_Time_Second: start 85, 6 bit, big-endian, i-signal-type=PRIMITIVE, init-value=constant-reference=Init_CAN4_IVI_Time_Second, base-type=uint8, implementation-data-type=uint8, transfer-property=PENDING
          signal CAN4_IVI_Time_Year: start 70, 7 bit, big-endian, i-signal-type=PRIMITIVE, init-value=constant-reference=Init_CAN4_IVI_Time_Year, base-type=uint8, implementation-data-type=uint8, transfer-property=PENDING
          signal CAN4_L_Drv_CtrlCmd: start 38, 7 bit, big-endian, i-signal-type=PRIMITIVE, init-value=constant-reference=Init_CAN4_L_Drv_CtrlCmd, base-type=uint8, implementation-data-type=uint8, transfer-property=TRIGGERED-ON-CHANGE
          signal CAN4_L_Pas_CtrlCmd: start 30, 7 bit, big-endian, i-signal-type=PRIMITIVE, init-value=constant-reference=Init_CAN4_L_Pas_CtrlCmd, base-type=uint8, implementation-data-type=uint8, transfer-property=TRIGGERED-ON-CHANGE
          signal CAN4_L_RLD_CtrlCmd: start 22, 7 bit, big-endian, i-signal-type=PRIMITIVE, init-value=constant-reference=Init_CAN4_L_RLD_CtrlCmd, base-type=uint8, implementation-data-type=uint8, transfer-property=TRIGGERED-ON-CHANGE
          signal CAN4_L_RRD_CtrlCmd: start 14, 7 bit, big-endian, i-signal-type=PRIMITIVE, init-value=constant-reference=Init_CAN4_L_RRD_CtrlCmd, base-type=uint8, implementation-data-type=uint8, transfer-property=TRIGGERED-ON-CHANGE
          signal CAN4_MCPressure: start 115, 12 bit, big-endian, i-signal-type=PRIMITIVE, init-value=constant-reference=Init_CAN4_MCPressure, base-type=uint16, implementation-data-type=uint16, transfer-property=PENDING
          signal CAN4_MCPressure_V: start 103, 1 bit, big-endian, i-signal-type=PRIMITIVE, init-value=constant-reference=Init_CAN4_MCPressure_V, base-type=uint8, implementation-data-type=uint8, transfer-property=TRIGGERED-ON-CHANGE
          signal CAN4_OFF_AC_MODE: start 111, 3 bit, big-endian, i-signal-type=PRIMITIVE, init-value=constant-reference=Init_CAN4_OFF_AC_MODE, base-type=uint8, implementation-data-type=uint8, transfer-property=TRIGGERED-ON-CHANGE
          signal CAN4_PSEAT_vent_req: start 44, 3 bit, big-endian, i-signal-type=PRIMITIVE, init-value=constant-reference=Init_CAN4_PSEAT_vent_req, base-type=uint8, implementation-data-type=uint8, transfer-property=PENDING
          signal CAN4_PTG_Inner_SW2: start 5, 2 bit, big-endian, i-signal-type=PRIMITIVE, init-value=constant-reference=Init_CAN4_PTG_Inner_SW2, base-type=uint8, implementation-data-type=uint8, transfer-property=PENDING
          signal CAN4_SenstivityPosition: start 51, 4 bit, big-endian, i-signal-type=PRIMITIVE, init-value=constant-reference=Init_CAN4_SenstivityPosition, base-type=uint8, implementation-data-type=uint8, transfer-property=PENDING
          signal CAN4_TurnSwTimeSet: start 87, 2 bit, big-endian, i-signal-type=PRIMITIVE, init-value=constant-reference=Init_CAN4_TurnSwTimeSet, base-type=uint8, implementation-data-type=uint8, transfer-property=TRIGGERED-ON-CHANGE
          signal CAN4_Walkaway_Lock_SW: start 23, 1 bit, big-endian, i-signal-type=PRIMITIVE, init-value=constant-reference=Init_CAN4_Walkaway_Lock_SW, base-type=uint8, implementation-data-type=uint8, transfer-property=TRIGGERED-ON-CHANGE
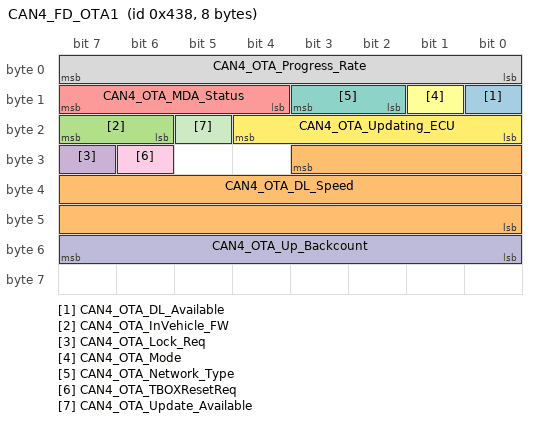
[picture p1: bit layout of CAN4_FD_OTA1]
      frame CAN4_FD_OTA1: id 0x438, frame-length=8, can-addressing-mode=STANDARD, can-fd-frame-support=true, can-frame-rx-behavior=CAN-FD, can-frame-tx-behavior=CAN-FD
        pdu CAN4_FD_OTA1: length=8, minimum-delay=0.0, transmission-mode-true-timing={cyclic-timing=time-period=0.2, event-controlled-timing={number-of-repetitions=0, repetition-period=0.02}}, unused-bit-pattern=0
          mapping CAN4_SG_FD_OTA1: i-signal-group=CAN4_SG_FD_OTA1, start-position=0, transfer-property=TRIGGERED-ON-CHANGE
          signal CAN4_OTA_DL_Available: start 8, 1 bit, big-endian, i-signal-type=PRIMITIVE, init-value=constant-reference=Init_CAN4_OTA_DL_Available, base-type=uint8, implementation-data-type=uint8, transfer-property=TRIGGERED-ON-CHANGE
          signal CAN4_OTA_DL_Speed: start 27, 20 bit, big-endian, i-signal-type=PRIMITIVE, init-value=constant-reference=Init_CAN4_OTA_DL_Speed, base-type=uint32, implementation-data-type=uint32, transfer-property=TRIGGERED-ON-CHANGE
          signal CAN4_OTA_InVehicle_FW: start 23, 2 bit, big-endian, i-signal-type=PRIMITIVE, init-value=constant-reference=Init_CAN4_OTA_InVehicle_FW, base-type=uint8, implementation-data-type=uint8, transfer-property=TRIGGERED-ON-CHANGE
          signal CAN4_OTA_Lock_Req: start 31, 1 bit, big-endian, i-signal-type=PRIMITIVE, init-value=constant-reference=Init_CAN4_OTA_Lock_Req, base-type=uint8, implementation-data-type=uint8, transfer-property=TRIGGERED-ON-CHANGE
          signal CAN4_OTA_MDA_Status: start 15, 4 bit, big-endian, i-signal-type=PRIMITIVE, init-value=constant-reference=Init_CAN4_OTA_MDA_Status, base-type=uint8, implementation-data-type=uint8, transfer-property=TRIGGERED-ON-CHANGE
          signal CAN4_OTA_Mode: start 9, 1 bit, big-endian, i-signal-type=PRIMITIVE, init-value=constant-reference=Init_CAN4_OTA_Mode, base-type=uint8, implementation-data-type=uint8, transfer-property=TRIGGERED-ON-CHANGE
          signal CAN4_OTA_Network_Type: start 11, 2 bit, big-endian, i-signal-type=PRIMITIVE, init-value=constant-reference=Init_CAN4_OTA_Network_Type, base-type=uint8, implementation-data-type=uint8, transfer-property=TRIGGERED-ON-CHANGE
          signal CAN4_OTA_Progress_Rate: start 7, 8 bit, big-endian, i-signal-type=PRIMITIVE, init-value=constant-reference=Init_CAN4_OTA_Progress_Rate, base-type=uint8, implementation-data-type=uint8, transfer-property=TRIGGERED-ON-CHANGE
          signal CAN4_OTA_TBOXResetReq: start 30, 1 bit, big-endian, i-signal-type=PRIMITIVE, init-value=constant-reference=Init_CAN4_OTA_TBOXResetReq, base-type=uint8, implementation-data-type=uint8, transfer-property=PENDING
          signal CAN4_OTA_Up_Backcount: start 55, 8 bit, big-endian, i-signal-type=PRIMITIVE, init-value=constant-reference=Init_CAN4_OTA_Up_Backcount, base-type=uint8, implementation-data-type=uint8, transfer-property=TRIGGERED-ON-CHANGE
          signal CAN4_OTA_Update_Available: start 21, 1 bit, big-endian, i-signal-type=PRIMITIVE, init-value=constant-reference=Init_CAN4_OTA_Update_Available, base-type=uint8, implementation-data-type=uint8, transfer-property=TRIGGERED-ON-CHANGE
          signal CAN4_OTA_Updating_ECU: start 20, 5 bit, big-endian, i-signal-type=PRIMITIVE, init-value=constant-reference=Init_CAN4_OTA_Updating_ECU, base-type=uint8, implementation-data-type=uint8, transfer-property=TRIGGERED-ON-CHANGE
      frame CAN4_FD_THCM1: id 0x182, frame-length=20, can-addressing-mode=STANDARD, can-fd-frame-support=true, can-frame-rx-behavior=CAN-FD, can-frame-tx-behavior=CAN-FD
        pdu CAN4_FD_THCM1: length=20, minimum-delay=0.0, transmission-mode-true-timing=cyclic-timing=time-period=0.1, unused-bit-pattern=0
          mapping CAN4_SG_FD_THCM1: i-signal-group=CAN4_SG_FD_THCM1, start-position=0, transfer-property=PENDING
          signal CAN4_BatteryMode: start 118, 3 bit, big-endian, i-signal-type=PRIMITIVE, init-value=constant-reference=Init_CAN4_BatteryMode, base-type=uint8, implementation-data-type=uint8, transfer-property=PENDING
          signal CAN4_CCU_ACLampSts: start 6, 1 bit, big-endian, i-signal-type=PRIMITIVE, init-value=constant-reference=Init_CAN4_CCU_ACLampSts, base-type=uint8, implementation-data-type=uint8, transfer-property=PENDING
          signal CAN4_CCU_ACMaxLampSts: start 1, 1 bit, big-endian, i-signal-type=PRIMITIVE, init-value=constant-reference=Init_CAN4_CCU_ACMaxLampSts, base-type=uint8, implementation-data-type=uint8, transfer-property=PENDING
          signal CAN4_CCU_AutoLampSts: start 2, 1 bit, big-endian, i-signal-type=PRIMITIVE, init-value=constant-reference=Init_CAN4_CCU_AutoLampSts, base-type=uint8, implementation-data-type=uint8, transfer-property=PENDING
          signal CAN4_CCU_AutoMidLampSts: start 3, 1 bit, big-endian, i-signal-type=PRIMITIVE, init-value=constant-reference=Init_CAN4_CCU_AutoMidLampSts, base-type=uint8, implementation-data-type=uint8, transfer-property=PENDING
          signal CAN4_CCU_Dispaly_Request: start 5, 1 bit, big-endian, i-signal-type=PRIMITIVE, init-value=constant-reference=Init_CAN4_CCU_Dispaly_Request, base-type=uint8, implementation-data-type=uint8, transfer-property=PENDING
          signal CAN4_CCU_EcoSts: start 4, 1 bit, big-endian, i-signal-type=PRIMITIVE, init-value=constant-reference=Init_CAN4_CCU_EcoSts, base-type=uint8, implementation-data-type=uint8, transfer-property=PENDING
          signal CAN4_CCU_FrtOnOffLampSts: start 19, 1 bit, big-endian, i-signal-type=PRIMITIVE, init-value=constant-reference=Init_CAN4_CCU_FrtOnOffLampSts, base-type=uint8, implementation-data-type=uint8, transfer-property=PENDING
          signal CAN4_CCU_HEATMaxLampSts: start 7, 1 bit, big-endian, i-signal-type=PRIMITIVE, init-value=constant-reference=Init_CAN4_CCU_HEATMaxLampSts, base-type=uint8, implementation-data-type=uint8, transfer-property=PENDING
          signal CAN4_CCU_RrOnOffLampSts: start 23, 1 bit, big-endian, i-signal-type=PRIMITIVE, init-value=constant-reference=Init_CAN4_CCU_RrOnOffLampSts, base-type=uint8, implementation-data-type=uint8, transfer-property=PENDING
          signal CAN4_CCU_SyncLampSts: start 39, 1 bit, big-endian, i-signal-type=PRIMITIVE, init-value=constant-reference=Init_CAN4_CCU_SyncLampSts, base-type=uint8, implementation-data-type=uint8, transfer-property=PENDING
          signal CAN4_CabinMode: start 115, 4 bit, big-endian, i-signal-type=PRIMITIVE, init-value=constant-reference=Init_CAN4_CabinMode, base-type=uint8, implementation-data-type=uint8, transfer-property=PENDING
          signal CAN4_EDriveMode: start 63, 2 bit, big-endian, i-signal-type=PRIMITIVE, init-value=constant-reference=Init_CAN4_EDriveMode, base-type=uint8, implementation-data-type=uint8, transfer-property=PENDING
          signal CAN4_FD_AGS_Cmd: start 143, 8 bit, big-endian, i-signal-type=PRIMITIVE, init-value=constant-reference=Init_CAN4_FD_AGS_Cmd, base-type=uint8, implementation-data-type=uint8, transfer-property=PENDING
          signal CAN4_FD_RecyAuto_Cmd: start 111, 3 bit, big-endian, i-signal-type=PRIMITIVE, init-value=constant-reference=Init_CAN4_FD_RecyAuto_Cmd, base-type=uint8, implementation-data-type=uint8, transfer-property=PENDING
          signal CAN4_Fr_Coolantflow: start 61, 6 bit, big-endian, i-signal-type=PRIMITIVE, init-value=constant-reference=Init_CAN4_Fr_Coolantflow, base-type=uint8, implementation-data-type=uint8, transfer-property=PENDING
          signal CAN4_Fr_Coolanttemp: start 0, 9 bit, big-endian, i-signal-type=PRIMITIVE, init-value=constant-reference=Init_CAN4_Fr_Coolanttemp, base-type=uint16, implementation-data-type=uint16, transfer-property=PENDING
          signal CAN4_HPThermalRecoveryReq: start 55, 2 bit, big-endian, i-signal-type=PRIMITIVE, init-value=constant-reference=Init_CAN4_HPThermalRecoveryReq, base-type=uint8, implementation-data-type=uint8, transfer-property=PENDING
          signal CAN4_Rr_Coolantflow: start 150, 6 bit, big-endian, i-signal-type=PRIMITIVE, init-value=constant-reference=Init_CAN4_Rr_Coolantflow, base-type=uint8, implementation-data-type=uint8, transfer-property=PENDING
          signal CAN4_Rr_Coolanttemp: start 144, 9 bit, big-endian, i-signal-type=PRIMITIVE, init-value=constant-reference=Init_CAN4_Rr_Coolanttemp, base-type=uint16, implementation-data-type=uint16, transfer-property=PENDING
          signal CAN4_sigAirIntenZon1St: start 31, 4 bit, big-endian, i-signal-type=PRIMITIVE, init-value=constant-reference=Init_CAN4_sigAirIntenZon1St, base-type=uint8, implementation-data-type=uint8, transfer-property=PENDING
          signal CAN4_sigAirIntenZon3St: start 27, 4 bit, big-endian, i-signal-type=PRIMITIVE, init-value=constant-reference=Init_CAN4_sigAirIntenZon3St, base-type=uint8, implementation-data-type=uint8, transfer-property=PENDING
          signal CAN4_sigAmbAirT: start 95, 8 bit, big-endian, i-signal-type=PRIMITIVE, init-value=constant-reference=Init_CAN4_sigAmbAirT, base-type=uint8, implementation-data-type=uint8, transfer-property=PENDING
          signal CAN4_sigCbnAirT: start 87, 8 bit, big-endian, i-signal-type=PRIMITIVE, init-value=constant-reference=Init_CAN4_sigCbnAirT, base-type=uint8, implementation-data-type=uint8, transfer-property=PENDING
          signal CAN4_sigCbnPTCPwrAct: start 79, 8 bit, big-endian, i-signal-type=PRIMITIVE, init-value=constant-reference=Init_CAN4_sigCbnPTCPwrAct, base-type=uint8, implementation-data-type=uint8, transfer-property=PENDING
          signal CAN4_sigCbnSolarLeft: start 127, 8 bit, big-endian, i-signal-type=PRIMITIVE, init-value=constant-reference=Init_CAN4_sigCbnSolarLeft, base-type=uint8, implementation-data-type=uint8, transfer-property=PENDING
          signal CAN4_sigCbnSolarRight: start 103, 8 bit, big-endian, i-signal-type=PRIMITIVE, init-value=constant-reference=Init_CAN4_sigCbnSolarRight, base-type=uint8, implementation-data-type=uint8, transfer-property=PENDING
          signal CAN4_sigClmtCmprPwrAct: start 71, 8 bit, big-endian, i-signal-type=PRIMITIVE, init-value=constant-reference=Init_CAN4_sigClmtCmprPwrAct, base-type=uint8, implementation-data-type=uint8, transfer-property=PENDING
          signal CAN4_sigClntTHvBattOut: start 135, 8 bit, big-endian, i-signal-type=PRIMITIVE, init-value=constant-reference=Init_CAN4_sigClntTHvBattOut, base-type=uint8, implementation-data-type=uint8, transfer-property=PENDING
          signal CAN4_sigDfrstSt: start 38, 1 bit, big-endian, i-signal-type=PRIMITIVE, init-value=constant-reference=Init_CAN4_sigDfrstSt, base-type=uint8, implementation-data-type=uint8, transfer-property=PENDING
          signal CAN4_sigHvacSt: start 46, 1 bit, big-endian, i-signal-type=PRIMITIVE, init-value=constant-reference=Init_CAN4_sigHvacSt, base-type=uint8, implementation-data-type=uint8, transfer-property=PENDING
          signal CAN4_sigRecircSt: start 47, 1 bit, big-endian, i-signal-type=PRIMITIVE, init-value=constant-reference=Init_CAN4_sigRecircSt, base-type=uint8, implementation-data-type=uint8, transfer-property=PENDING
          signal CAN4_sigSetTempZon1St: start 53, 6 bit, big-endian, i-signal-type=PRIMITIVE, init-value=constant-reference=Init_CAN4_sigSetTempZon1St, base-type=uint8, implementation-data-type=uint8, transfer-property=PENDING
          signal CAN4_sigSetTempZon2St: start 45, 6 bit, big-endian, i-signal-type=PRIMITIVE, init-value=constant-reference=Init_CAN4_sigSetTempZon2St, base-type=uint8, implementation-data-type=uint8, transfer-property=PENDING
          signal CAN4_sigSetTempZon3St: start 37, 6 bit, big-endian, i-signal-type=PRIMITIVE, init-value=constant-reference=Init_CAN4_sigSetTempZon3St, base-type=uint8, implementation-data-type=uint8, transfer-property=PENDING
          signal CAN4_sigWindDirZon1St: start 22, 3 bit, big-endian, i-signal-type=PRIMITIVE, init-value=constant-reference=Init_CAN4_sigWindDirZon1St, base-type=uint8, implementation-data-type=uint8, transfer-property=PENDING
          signal CAN4_sigWindDirZon3St: start 18, 3 bit, big-endian, i-signal-type=PRIMITIVE, init-value=constant-reference=Init_CAN4_sigWindDirZon3St, base-type=uint8, implementation-data-type=uint8, transfer-property=PENDING
      frame CAN4_FD_THCM2: id 0x186, frame-length=20, can-addressing-mode=STANDARD, can-fd-frame-support=true, can-frame-rx-behavior=CAN-FD, can-frame-tx-behavior=CAN-FD
        pdu CAN4_FD_THCM2: length=20, minimum-delay=0.0, transmission-mode-true-timing={cyclic-timing=time-period=0.1, event-controlled-timing={number-of-repetitions=0, repetition-period=0.01}}, unused-bit-pattern=0
          mapping CAN4_SG_FD_THCM2: i-signal-group=CAN4_SG_FD_THCM2, start-position=0, transfer-property=TRIGGERED-ON-CHANGE
          signal CAN4_ACSubMode: start 11, 3 bit, big-endian, i-signal-type=PRIMITIVE, init-value=constant-reference=Init_CAN4_ACSubMode, base-type=uint8, implementation-data-type=uint8, transfer-property=PENDING
          signal CAN4_APTC_ActFrRiPwr: start 143, 8 bit, big-endian, i-signal-type=PRIMITIVE, init-value=constant-reference=Init_CAN4_APTC_ActFrRiPwr, base-type=uint8, implementation-data-type=uint8, transfer-property=TRIGGERED-ON-CHANGE
          signal CAN4_BatLoopActWtFlw: start 151, 8 bit, big-endian, i-signal-type=PRIMITIVE, init-value=constant-reference=Init_CAN4_BatLoopActWtFlw, base-type=uint8, implementation-data-type=uint8, transfer-property=PENDING
          signal CAN4_CCU_CbnPreACWkSts: start 35, 2 bit, big-endian, i-signal-type=PRIMITIVE, init-value=constant-reference=Init_CAN4_CCU_CbnPreACWkSts, base-type=uint8, implementation-data-type=uint8, transfer-property=PENDING
          signal CAN4_CCU_CbnPreEstimdTi: start 55, 6 bit, big-endian, i-signal-type=PRIMITIVE, init-value=constant-reference=Init_CAN4_CCU_CbnPreEstimdTi, base-type=uint8, implementation-data-type=uint8, transfer-property=PENDING
          signal CAN4_CCU_CbnPreSts: start 39, 2 bit, big-endian, i-signal-type=PRIMITIVE, init-value=constant-reference=Init_CAN4_CCU_CbnPreSts, base-type=uint8, implementation-data-type=uint8, transfer-property=PENDING
          signal CAN4_CCU_HiVoltageReq: start 23, 1 bit, big-endian, i-signal-type=PRIMITIVE, init-value=constant-reference=Init_CAN4_CCU_HiVoltageReq, base-type=uint8, implementation-data-type=uint8, transfer-property=PENDING
          signal CAN4_CoolgFanActDuty: start 159, 8 bit, big-endian, i-signal-type=PRIMITIVE, init-value=constant-reference=Init_CAN4_CoolgFanActDuty, base-type=uint8, implementation-data-type=uint8, transfer-property=TRIGGERED-ON-CHANGE
          signal CAN4_DeiceModReq: start 37, 2 bit, big-endian, i-signal-type=PRIMITIVE, init-value=constant-reference=Init_CAN4_DeiceModReq, base-type=uint8, implementation-data-type=uint8, transfer-property=PENDING
          signal CAN4_FD_Blower_Cmd: start 7, 8 bit, big-endian, i-signal-type=PRIMITIVE, init-value=constant-reference=Init_CAN4_FD_Blower_Cmd, base-type=uint8, implementation-data-type=uint8, transfer-property=TRIGGERED-ON-CHANGE
          signal CAN4_FD_Comp_Cmd: start 22, 15 bit, big-endian, i-signal-type=PRIMITIVE, init-value=constant-reference=Init_CAN4_FD_Comp_Cmd, base-type=uint16, implementation-data-type=uint16, transfer-property=TRIGGERED-ON-CHANGE
          signal CAN4_FD_EWP1_Cmd: start 135, 8 bit, big-endian, i-signal-type=PRIMITIVE, init-value=constant-reference=Init_CAN4_FD_EWP1_Cmd, base-type=uint8, implementation-data-type=uint8, transfer-property=PENDING
          signal CAN4_FD_EWP2_Cmd: start 127, 8 bit, big-endian, i-signal-type=PRIMITIVE, init-value=constant-reference=Init_CAN4_FD_EWP2_Cmd, base-type=uint8, implementation-data-type=uint8, transfer-property=PENDING
          signal CAN4_FD_EWP3_Cmd: start 119, 8 bit, big-endian, i-signal-type=PRIMITIVE, init-value=constant-reference=Init_CAN4_FD_EWP3_Cmd, base-type=uint8, implementation-data-type=uint8, transfer-property=PENDING
          signal CAN4_FD_EXV1_Cmd: start 33, 10 bit, big-endian, i-signal-type=PRIMITIVE, init-value=constant-reference=Init_CAN4_FD_EXV1_Cmd, base-type=uint16, implementation-data-type=uint16, transfer-property=PENDING
          signal CAN4_FD_EXV2_Cmd: start 49, 10 bit, big-endian, i-signal-type=PRIMITIVE, init-value=constant-reference=Init_CAN4_FD_EXV2_Cmd, base-type=uint16, implementation-data-type=uint16, transfer-property=PENDING
          signal CAN4_FD_FWV_Cmd: start 8, 1 bit, big-endian, i-signal-type=PRIMITIVE, init-value=constant-reference=Init_CAN4_FD_FWV_Cmd, base-type=uint8, implementation-data-type=uint8, transfer-property=PENDING
          signal CAN4_FD_FrLeAPTCHeatPwr_Cmd: start 87, 8 bit, big-endian, i-signal-type=PRIMITIVE, init-value=constant-reference=Init_CAN4_FD_FrLeAPTCHeatPwr_Cmd, base-type=uint8, implementation-data-type=uint8, transfer-property=TRIGGERED-ON-CHANGE
          signal CAN4_FD_FrRiAPTCHeatPwr_Cmd: start 79, 8 bit, big-endian, i-signal-type=PRIMITIVE, init-value=constant-reference=Init_CAN4_FD_FrRiAPTCHeatPwr_Cmd, base-type=uint8, implementation-data-type=uint8, transfer-property=TRIGGERED-ON-CHANGE
          signal CAN4_FD_FrWPTCHeatPwr_Cmd: start 103, 16 bit, big-endian, i-signal-type=PRIMITIVE, init-value=constant-reference=Init_CAN4_FD_FrWPTCHeatPwr_Cmd, base-type=uint16, implementation-data-type=uint16, transfer-property=TRIGGERED-ON-CHANGE
          signal CAN4_FD_RrAPTCHeatPwr_Cmd: start 95, 8 bit, big-endian, i-signal-type=PRIMITIVE, init-value=constant-reference=Init_CAN4_FD_RrAPTCHeatPwr_Cmd, base-type=uint8, implementation-data-type=uint8, transfer-property=TRIGGERED-ON-CHANGE
          signal CAN4_FD_SOTXV_Cmd: start 12, 1 bit, big-endian, i-signal-type=PRIMITIVE, init-value=constant-reference=Init_CAN4_FD_SOTXV_Cmd, base-type=uint8, implementation-data-type=uint8, transfer-property=PENDING
          signal CAN4_FD_SOV1_Cmd: start 13, 1 bit, big-endian, i-signal-type=PRIMITIVE, init-value=constant-reference=Init_CAN4_FD_SOV1_Cmd, base-type=uint8, implementation-data-type=uint8, transfer-property=PENDING
          signal CAN4_FD_SOV2_Cmd: start 14, 1 bit, big-endian, i-signal-type=PRIMITIVE, init-value=constant-reference=Init_CAN4_FD_SOV2_Cmd, base-type=uint8, implementation-data-type=uint8, transfer-property=PENDING
          signal CAN4_FD_SOV3_Cmd: start 15, 1 bit, big-endian, i-signal-type=PRIMITIVE, init-value=constant-reference=Init_CAN4_FD_SOV3_Cmd, base-type=uint8, implementation-data-type=uint8, transfer-property=PENDING
          signal CAN4_FD_TWV_Cmd: start 71, 8 bit, big-endian, i-signal-type=PRIMITIVE, init-value=constant-reference=Init_CAN4_FD_TWV_Cmd, base-type=uint8, implementation-data-type=uint8, transfer-property=PENDING
      frame CAN4_FD_VCU1: id 0x116, frame-length=32, can-addressing-mode=STANDARD, can-fd-frame-support=true, can-frame-rx-behavior=CAN-FD, can-frame-tx-behavior=CAN-FD
        pdu CAN4_FD_VCU1: length=32, minimum-delay=0.0, transmission-mode-true-timing=event-controlled-timing={number-of-repetitions=0, repetition-period=0.01}, unused-bit-pattern=0
          mapping CAN4_SG_FD_VCU1: i-signal-group=CAN4_SG_FD_VCU1, start-position=0, transfer-property=TRIGGERED
          signal CAN4_AllDoorSW: start 155, 1 bit, big-endian, i-signal-type=PRIMITIVE, init-value=constant-reference=Init_CAN4_AllDoorSW, base-type=uint8, implementation-data-type=uint8, transfer-property=TRIGGERED
          signal CAN4_AmbLightBreath1: start 187, 1 bit, big-endian, i-signal-type=PRIMITIVE, init-value=constant-reference=Init_CAN4_AmbLightBreath1, base-type=uint8, implementation-data-type=uint8, transfer-property=TRIGGERED
          signal CAN4_AmbLightBreath2: start 189, 1 bit, big-endian, i-signal-type=PRIMITIVE, init-value=constant-reference=Init_CAN4_AmbLightBreath2, base-type=uint8, implementation-data-type=uint8, transfer-property=TRIGGERED
          signal CAN4_AmbLightBreath3: start 190, 1 bit, big-endian, i-signal-type=PRIMITIVE, init-value=constant-reference=Init_CAN4_AmbLightBreath3, base-type=uint8, implementation-data-type=uint8, transfer-property=TRIGGERED
          signal CAN4_AmbLightBrightness1: start 238, 7 bit, big-endian, i-signal-type=PRIMITIVE, init-value=constant-reference=Init_CAN4_AmbLightBrightness1, base-type=uint8, implementation-data-type=uint8, transfer-property=TRIGGERED
          signal CAN4_AmbLightBrightness2: start 230, 7 bit, big-endian, i-signal-type=PRIMITIVE, init-value=constant-reference=Init_CAN4_AmbLightBrightness2, base-type=uint8, implementation-data-type=uint8, transfer-property=TRIGGERED
          signal CAN4_AmbLightBrightness3: start 222, 7 bit, big-endian, i-signal-type=PRIMITIVE, init-value=constant-reference=Init_CAN4_AmbLightBrightness3, base-type=uint8, implementation-data-type=uint8, transfer-property=TRIGGERED
          signal CAN4_AmbLightColor1: start 213, 6 bit, big-endian, i-signal-type=PRIMITIVE, init-value=constant-reference=Init_CAN4_AmbLightColor1, base-type=uint8, implementation-data-type=uint8, transfer-property=TRIGGERED
          signal CAN4_AmbLightColor2: start 205, 6 bit, big-endian, i-signal-type=PRIMITIVE, init-value=constant-reference=Init_CAN4_AmbLightColor2, base-type=uint8, implementation-data-type=uint8, transfer-property=TRIGGERED
          signal CAN4_AmbLightColor3: start 197, 6 bit, big-endian, i-signal-type=PRIMITIVE, init-value=constant-reference=Init_CAN4_AmbLightColor3, base-type=uint8, implementation-data-type=uint8, transfer-property=TRIGGERED
          signal CAN4_AntiTheftSeatFold: start 115, 1 bit, big-endian, i-signal-type=PRIMITIVE, init-value=constant-reference=Init_CAN4_AntiTheftSeatFold, base-type=uint8, implementation-data-type=uint8, transfer-property=TRIGGERED
          signal CAN4_AntitheftSta: start 114, 2 bit, big-endian, i-signal-type=PRIMITIVE, init-value=constant-reference=Init_CAN4_AntitheftSta, base-type=uint8, implementation-data-type=uint8, transfer-property=TRIGGERED
          signal CAN4_BCM_Buzzer_Req: start 110, 1 bit, big-endian, i-signal-type=PRIMITIVE, init-value=constant-reference=Init_CAN4_BCM_Buzzer_Req, base-type=uint8, implementation-data-type=uint8, transfer-property=TRIGGERED
          signal CAN4_BCM_DoorLock_Sta: start 100, 1 bit, big-endian, i-signal-type=PRIMITIVE, init-value=constant-reference=Init_CAN4_BCM_DoorLock_Sta, base-type=uint8, implementation-data-type=uint8, transfer-property=TRIGGERED
          signal CAN4_BrakeLamp: start 121, 1 bit, big-endian, i-signal-type=PRIMITIVE, init-value=constant-reference=Init_CAN4_BrakeLamp, base-type=uint8, implementation-data-type=uint8, transfer-property=TRIGGERED
          signal CAN4_CC_Crl_Sta: start 18, 3 bit, big-endian, i-signal-type=PRIMITIVE, init-value=constant-reference=Init_CAN4_CC_Crl_Sta, base-type=uint8, implementation-data-type=uint8, transfer-property=TRIGGERED
          signal CAN4_CS_VCU1_CAN4: start 7, 8 bit, big-endian, i-signal-type=PRIMITIVE, init-value=constant-reference=Init_CAN4_CS_VCU1_CAN4, base-type=uint8, implementation-data-type=uint8, transfer-property=TRIGGERED
          signal CAN4_CTDCtrl: start 144, 2 bit, big-endian, i-signal-type=PRIMITIVE, init-value=constant-reference=Init_CAN4_CTDCtrl, base-type=uint8, implementation-data-type=uint8, transfer-property=TRIGGERED
          signal CAN4_CTDLockSW: start 149, 1 bit, big-endian, i-signal-type=PRIMITIVE, init-value=constant-reference=Init_CAN4_CTDLockSW, base-type=uint8, implementation-data-type=uint8, transfer-property=TRIGGERED
          signal CAN4_CTDUnlockSW: start 150, 1 bit, big-endian, i-signal-type=PRIMITIVE, init-value=constant-reference=Init_CAN4_CTDUnlockSW, base-type=uint8, implementation-data-type=uint8, transfer-property=TRIGGERED
          signal CAN4_CrashDetd: start 116, 1 bit, big-endian, i-signal-type=PRIMITIVE, init-value=constant-reference=Init_CAN4_CrashDetd, base-type=uint8, implementation-data-type=uint8, transfer-property=TRIGGERED
          signal CAN4_CtrlDrPwrStbA2: start 214, 1 bit, big-endian, i-signal-type=PRIMITIVE, init-value=constant-reference=Init_CAN4_CtrlDrPwrStbA2, base-type=uint8, implementation-data-type=uint8, transfer-property=TRIGGERED
          signal CAN4_CtrlFrBMSCCUCIR: start 239, 1 bit, big-endian, i-signal-type=PRIMITIVE, init-value=constant-reference=Init_CAN4_CtrlFrBMSCCUCIR, base-type=uint8, implementation-data-type=uint8, transfer-property=TRIGGERED
          signal CAN4_CtrlFrEDUINVERTER: start 231, 1 bit, big-endian, i-signal-type=PRIMITIVE, init-value=constant-reference=Init_CAN4_CtrlFrEDUINVERTER, base-type=uint8, implementation-data-type=uint8, transfer-property=TRIGGERED
          signal CAN4_CtrlFrIRC1: start 223, 1 bit, big-endian, i-signal-type=PRIMITIVE, init-value=constant-reference=Init_CAN4_CtrlFrIRC1, base-type=uint8, implementation-data-type=uint8, transfer-property=TRIGGERED
          signal CAN4_CtrlFrPwrStbA1P: start 215, 1 bit, big-endian, i-signal-type=PRIMITIVE, init-value=constant-reference=Init_CAN4_CtrlFrPwrStbA1P, base-type=uint8, implementation-data-type=uint8, transfer-property=TRIGGERED
          signal CAN4_DKCAuthSta: start 185, 2 bit, big-endian, i-signal-type=PRIMITIVE, init-value=constant-reference=Init_CAN4_DKCAuthSta, base-type=uint8, implementation-data-type=uint8, transfer-property=TRIGGERED
          signal CAN4_DKCTimeSN: start 39, 32 bit, big-endian, i-signal-type=PRIMITIVE, init-value=constant-reference=Init_CAN4_DKCTimeSN, base-type=uint32, implementation-data-type=uint32, transfer-property=TRIGGERED
          signal CAN4_Dimmer: start 108, 7 bit, big-endian, i-signal-type=PRIMITIVE, init-value=constant-reference=Init_CAN4_Dimmer, base-type=uint8, implementation-data-type=uint8, transfer-property=TRIGGERED
          signal CAN4_DimmerEN: start 99, 1 bit, big-endian, i-signal-type=PRIMITIVE, init-value=constant-reference=Init_CAN4_DimmerEN, base-type=uint8, implementation-data-type=uint8, transfer-property=TRIGGERED
          signal CAN4_DoorLockIND: start 156, 1 bit, big-endian, i-signal-type=PRIMITIVE, init-value=constant-reference=Init_CAN4_DoorLockIND, base-type=uint8, implementation-data-type=uint8, transfer-property=TRIGGERED
          signal CAN4_DrDoorSW: start 167, 1 bit, big-endian, i-signal-type=PRIMITIVE, init-value=constant-reference=Init_CAN4_DrDoorSW, base-type=uint8, implementation-data-type=uint8, transfer-property=TRIGGERED
          signal CAN4_Dr_SeatSta: start 23, 2 bit, big-endian, i-signal-type=PRIMITIVE, init-value=constant-reference=Init_CAN4_Dr_SeatSta, base-type=uint8, implementation-data-type=uint8, transfer-property=TRIGGERED
          signal CAN4_EquivAccPedalSWSta: start 102, 1 bit, big-endian, i-signal-type=PRIMITIVE, init-value=constant-reference=Init_CAN4_EquivAccPedalSWSta, base-type=uint8, implementation-data-type=uint8, transfer-property=TRIGGERED
          signal CAN4_FD_DKC_VehData_Err: start 170, 4 bit, big-endian, i-signal-type=PRIMITIVE, init-value=constant-reference=Init_CAN4_FD_DKC_VehData_Err, base-type=uint8, implementation-data-type=uint8, transfer-property=TRIGGERED
          signal CAN4_FD_DKC_VehData_Sta: start 174, 4 bit, big-endian, i-signal-type=PRIMITIVE, init-value=constant-reference=Init_CAN4_FD_DKC_VehData_Sta, base-type=uint8, implementation-data-type=uint8, transfer-property=TRIGGERED
          signal CAN4_FD_TBOX_DTCData_Err: start 178, 4 bit, big-endian, i-signal-type=PRIMITIVE, init-value=constant-reference=Init_CAN4_FD_TBOX_DTCData_Err, base-type=uint8, implementation-data-type=uint8, transfer-property=TRIGGERED
          signal CAN4_FD_TBOX_DTCData_Sta: start 182, 4 bit, big-endian, i-signal-type=PRIMITIVE, init-value=constant-reference=Init_CAN4_FD_TBOX_DTCData_Sta, base-type=uint8, implementation-data-type=uint8, transfer-property=TRIGGERED
          signal CAN4_FD_TBOX_VehData_Err: start 162, 4 bit, big-endian, i-signal-type=PRIMITIVE, init-value=constant-reference=Init_CAN4_FD_TBOX_VehData_Err, base-type=uint8, implementation-data-type=uint8, transfer-property=TRIGGERED
          signal CAN4_FD_TBOX_VehData_Sta: start 166, 4 bit, big-endian, i-signal-type=PRIMITIVE, init-value=constant-reference=Init_CAN4_FD_TBOX_VehData_Sta, base-type=uint8, implementation-data-type=uint8, transfer-property=TRIGGERED
          signal CAN4_Fr_ChargingDoorCtrl: start 146, 2 bit, big-endian, i-signal-type=PRIMITIVE, init-value=constant-reference=Init_CAN4_Fr_ChargingDoorCtrl, base-type=uint8, implementation-data-type=uint8, transfer-property=TRIGGERED
          signal CAN4_Fr_FogLamp: start 124, 1 bit, big-endian, i-signal-type=PRIMITIVE, init-value=constant-reference=Init_CAN4_Fr_FogLamp, base-type=uint8, implementation-data-type=uint8, transfer-property=TRIGGERED
          signal CAN4_Fr_Wiper_H: start 141, 1 bit, big-endian, i-signal-type=PRIMITIVE, init-value=constant-reference=Init_CAN4_Fr_Wiper_H, base-type=uint8, implementation-data-type=uint8, transfer-property=TRIGGERED
          signal CAN4_Fr_Wiper_L: start 142, 1 bit, big-endian, i-signal-type=PRIMITIVE, init-value=constant-reference=Init_CAN4_Fr_Wiper_L, base-type=uint8, implementation-data-type=uint8, transfer-property=TRIGGERED
          signal CAN4_HWResetSta: start 207, 2 bit, big-endian, i-signal-type=PRIMITIVE, init-value=constant-reference=Init_CAN4_HWResetSta, base-type=uint8, implementation-data-type=uint8, transfer-property=TRIGGERED
          signal CAN4_H_Beam: start 132, 1 bit, big-endian, i-signal-type=PRIMITIVE, init-value=constant-reference=Init_CAN4_H_Beam, base-type=uint8, implementation-data-type=uint8, transfer-property=TRIGGERED
          signal CAN4_HazardSW: start 126, 1 bit, big-endian, i-signal-type=PRIMITIVE, init-value=constant-reference=Init_CAN4_HazardSW, base-type=uint8, implementation-data-type=uint8, transfer-property=TRIGGERED
          signal CAN4_HoodSW: start 157, 1 bit, big-endian, i-signal-type=PRIMITIVE, init-value=constant-reference=Init_CAN4_HoodSW, base-type=uint8, implementation-data-type=uint8, transfer-property=TRIGGERED
          signal CAN4_HornCtrl: start 101, 1 bit, big-endian, i-signal-type=PRIMITIVE, init-value=constant-reference=Init_CAN4_HornCtrl, base-type=uint8, implementation-data-type=uint8, transfer-property=TRIGGERED
          signal CAN4_LBSD: start 122, 1 bit, big-endian, i-signal-type=PRIMITIVE, init-value=constant-reference=Init_CAN4_LBSD, base-type=uint8, implementation-data-type=uint8, transfer-property=TRIGGERED
          signal CAN4_LDRL: start 134, 1 bit, big-endian, i-signal-type=PRIMITIVE, init-value=constant-reference=Init_CAN4_LDRL, base-type=uint8, implementation-data-type=uint8, transfer-property=TRIGGERED
          signal CAN4_LTurnLP: start 127, 1 bit, big-endian, i-signal-type=PRIMITIVE, init-value=constant-reference=Init_CAN4_LTurnLP, base-type=uint8, implementation-data-type=uint8, transfer-property=TRIGGERED
          signal CAN4_L_APM_WdwEnable: start 117, 1 bit, big-endian, i-signal-type=PRIMITIVE, init-value=constant-reference=Init_CAN4_L_APM_WdwEnable, base-type=uint8, implementation-data-type=uint8, transfer-property=TRIGGERED
          signal CAN4_L_Beam: start 131, 1 bit, big-endian, i-signal-type=PRIMITIVE, init-value=constant-reference=Init_CAN4_L_Beam, base-type=uint8, implementation-data-type=uint8, transfer-property=TRIGGERED
          signal CAN4_LampPwr: start 188, 1 bit, big-endian, i-signal-type=PRIMITIVE, init-value=constant-reference=Init_CAN4_LampPwr, base-type=uint8, implementation-data-type=uint8, transfer-property=TRIGGERED
          signal CAN4_LockSetting: start 109, 1 bit, big-endian, i-signal-type=PRIMITIVE, init-value=constant-reference=Init_CAN4_LockSetting, base-type=uint8, implementation-data-type=uint8, transfer-property=TRIGGERED
          signal CAN4_MSA_Crl_Sta: start 21, 3 bit, big-endian, i-signal-type=PRIMITIVE, init-value=constant-reference=Init_CAN4_MSA_Crl_Sta, base-type=uint8, implementation-data-type=uint8, transfer-property=TRIGGERED
          signal CAN4_MirrorCtrl: start 140, 2 bit, big-endian, i-signal-type=PRIMITIVE, init-value=constant-reference=Init_CAN4_MirrorCtrl, base-type=uint8, implementation-data-type=uint8, transfer-property=TRIGGERED
          signal CAN4_MirrorDefog: start 151, 1 bit, big-endian, i-signal-type=PRIMITIVE, init-value=constant-reference=Init_CAN4_MirrorDefog, base-type=uint8, implementation-data-type=uint8, transfer-property=TRIGGERED
          signal CAN4_PosLamp: start 133, 1 bit, big-endian, i-signal-type=PRIMITIVE, init-value=constant-reference=Init_CAN4_PosLamp, base-type=uint8, implementation-data-type=uint8, transfer-property=TRIGGERED
          signal CAN4_PsDoorSW: start 152, 1 bit, big-endian, i-signal-type=PRIMITIVE, init-value=constant-reference=Init_CAN4_PsDoorSW, base-type=uint8, implementation-data-type=uint8, transfer-property=TRIGGERED
          signal CAN4_PwrSta: start 28, 3 bit, big-endian, i-signal-type=PRIMITIVE, init-value=constant-reference=Init_CAN4_PwrSta, base-type=uint8, implementation-data-type=uint8, transfer-property=TRIGGERED
          signal CAN4_RBSD: start 123, 1 bit, big-endian, i-signal-type=PRIMITIVE, init-value=constant-reference=Init_CAN4_RBSD, base-type=uint8, implementation-data-type=uint8, transfer-property=TRIGGERED
          signal CAN4_RC_VCU1_CAN4: start 11, 4 bit, big-endian, i-signal-type=PRIMITIVE, init-value=constant-reference=Init_CAN4_RC_VCU1_CAN4, base-type=uint8, implementation-data-type=uint8, transfer-property=TRIGGERED
          signal CAN4_RDRL: start 135, 1 bit, big-endian, i-signal-type=PRIMITIVE, init-value=constant-reference=Init_CAN4_RDRL, base-type=uint8, implementation-data-type=uint8, transfer-property=TRIGGERED
          signal CAN4_RLDoorSW: start 153, 1 bit, big-endian, i-signal-type=PRIMITIVE, init-value=constant-reference=Init_CAN4_RLDoorSW, base-type=uint8, implementation-data-type=uint8, transfer-property=TRIGGERED
          signal CAN4_RRDoorSW: start 154, 1 bit, big-endian, i-signal-type=PRIMITIVE, init-value=constant-reference=Init_CAN4_RRDoorSW, base-type=uint8, implementation-data-type=uint8, transfer-property=TRIGGERED
          signal CAN4_RTurnLP: start 112, 1 bit, big-endian, i-signal-type=PRIMITIVE, init-value=constant-reference=Init_CAN4_RTurnLP, base-type=uint8, implementation-data-type=uint8, transfer-property=TRIGGERED
          signal CAN4_ReBrakeLPReq: start 25, 1 bit, big-endian, i-signal-type=PRIMITIVE, init-value=constant-reference=Init_CAN4_ReBrakeLPReq, base-type=uint8, implementation-data-type=uint8, transfer-property=TRIGGERED
          signal CAN4_ReverseLamp: start 120, 1 bit, big-endian, i-signal-type=PRIMITIVE, init-value=constant-reference=Init_CAN4_ReverseLamp, base-type=uint8, implementation-data-type=uint8, transfer-property=TRIGGERED
          signal CAN4_RoomLampH: start 98, 1 bit, big-endian, i-signal-type=PRIMITIVE, init-value=constant-reference=Init_CAN4_RoomLampH, base-type=uint8, implementation-data-type=uint8, transfer-property=TRIGGERED
          signal CAN4_RoomLampL: start 97, 1 bit, big-endian, i-signal-type=PRIMITIVE, init-value=constant-reference=Init_CAN4_RoomLampL, base-type=uint8, implementation-data-type=uint8, transfer-property=TRIGGERED
          signal CAN4_Rr_ChargingDoorCtrl: start 148, 2 bit, big-endian, i-signal-type=PRIMITIVE, init-value=constant-reference=Init_CAN4_Rr_ChargingDoorCtrl, base-type=uint8, implementation-data-type=uint8, transfer-property=TRIGGERED
          signal CAN4_Rr_Defog: start 136, 1 bit, big-endian, i-signal-type=PRIMITIVE, init-value=constant-reference=Init_CAN4_Rr_Defog, base-type=uint8, implementation-data-type=uint8, transfer-property=TRIGGERED
          signal CAN4_Rr_FogLamp: start 125, 1 bit, big-endian, i-signal-type=PRIMITIVE, init-value=constant-reference=Init_CAN4_Rr_FogLamp, base-type=uint8, implementation-data-type=uint8, transfer-property=TRIGGERED
          signal CAN4_Rr_Wiper: start 143, 1 bit, big-endian, i-signal-type=PRIMITIVE, init-value=constant-reference=Init_CAN4_Rr_Wiper, base-type=uint8, implementation-data-type=uint8, transfer-property=TRIGGERED
          signal CAN4_ShiftGearPosn: start 31, 3 bit, big-endian, i-signal-type=PRIMITIVE, init-value=constant-reference=Init_CAN4_ShiftGearPosn, base-type=uint8, implementation-data-type=uint8, transfer-property=TRIGGERED
          signal CAN4_TailgateHDSW: start 138, 1 bit, big-endian, i-signal-type=PRIMITIVE, init-value=constant-reference=Init_CAN4_TailgateHDSW, base-type=uint8, implementation-data-type=uint8, transfer-property=TRIGGERED
          signal CAN4_TailgateRemote: start 96, 2 bit, big-endian, i-signal-type=PRIMITIVE, init-value=constant-reference=Init_CAN4_TailgateRemote, base-type=uint8, implementation-data-type=uint8, transfer-property=TRIGGERED
          signal CAN4_Tailgate_SW: start 158, 1 bit, big-endian, i-signal-type=PRIMITIVE, init-value=constant-reference=Init_CAN4_Tailgate_SW, base-type=uint8, implementation-data-type=uint8, transfer-property=TRIGGERED
          signal CAN4_TimeSNDKCFbk: start 71, 32 bit, big-endian, i-signal-type=PRIMITIVE, init-value=constant-reference=Init_CAN4_TimeSNDKCFbk, base-type=uint32, implementation-data-type=uint32, transfer-property=TRIGGERED
          signal CAN4_TrunkRel: start 137, 1 bit, big-endian, i-signal-type=PRIMITIVE, init-value=constant-reference=Init_CAN4_TrunkRel, base-type=uint8, implementation-data-type=uint8, transfer-property=TRIGGERED
          signal CAN4_VehSpeed: start 243, 12 bit, big-endian, i-signal-type=PRIMITIVE, init-value=constant-reference=Init_CAN4_VehSpeed, base-type=uint16, implementation-data-type=uint16, transfer-property=TRIGGERED
          signal CAN4_WasherCtrl: start 130, 2 bit, big-endian, i-signal-type=PRIMITIVE, init-value=constant-reference=Init_CAN4_WasherCtrl, base-type=uint8, implementation-data-type=uint8, transfer-property=TRIGGERED
          signal CAN4_WiperFixMode: start 128, 1 bit, big-endian, i-signal-type=PRIMITIVE, init-value=constant-reference=Init_CAN4_WiperFixMode, base-type=uint8, implementation-data-type=uint8, transfer-property=TRIGGERED
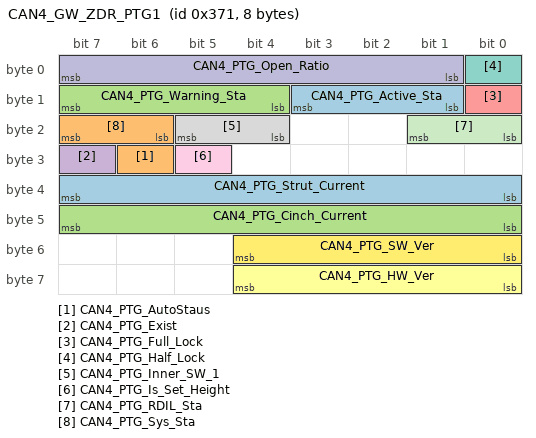
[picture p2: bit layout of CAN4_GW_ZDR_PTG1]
      frame CAN4_GW_ZDR_PTG1: id 0x371, frame-length=8, can-addressing-mode=STANDARD, can-fd-frame-support=true, can-frame-rx-behavior=CAN-FD, can-frame-tx-behavior=CAN-FD
        pdu CAN4_GW_ZDR_PTG1: length=8, minimum-delay=0.0, transmission-mode-true-timing=cyclic-timing=time-period=0.1, unused-bit-pattern=0
          mapping CAN4_SG_GW_ZDR_PTG1: i-signal-group=CAN4_SG_GW_ZDR_PTG1, start-position=0, transfer-property=PENDING
          signal CAN4_PTG_Active_Sta: start 11, 3 bit, big-endian, i-signal-type=PRIMITIVE, init-value=constant-reference=Init_CAN4_PTG_Active_Sta, base-type=uint8, implementation-data-type=uint8, transfer-property=PENDING
          signal CAN4_PTG_AutoStaus: start 30, 1 bit, big-endian, i-signal-type=PRIMITIVE, init-value=constant-reference=Init_CAN4_PTG_AutoStaus, base-type=uint8, implementation-data-type=uint8, transfer-property=PENDING
          signal CAN4_PTG_Cinch_Current: start 47, 8 bit, big-endian, i-signal-type=PRIMITIVE, init-value=constant-reference=Init_CAN4_PTG_Cinch_Current, base-type=uint8, implementation-data-type=uint8, transfer-property=PENDING
          signal CAN4_PTG_Exist: start 31, 1 bit, big-endian, i-signal-type=PRIMITIVE, init-value=constant-reference=Init_CAN4_PTG_Exist, base-type=uint8, implementation-data-type=uint8, transfer-property=PENDING
          signal CAN4_PTG_Full_Lock: start 8, 1 bit, big-endian, i-signal-type=PRIMITIVE, init-value=constant-reference=Init_CAN4_PTG_Full_Lock, base-type=uint8, implementation-data-type=uint8, transfer-property=PENDING
          signal CAN4_PTG_HW_Ver: start 60, 5 bit, big-endian, i-signal-type=PRIMITIVE, init-value=constant-reference=Init_CAN4_PTG_HW_Ver, base-type=uint8, implementation-data-type=uint8, transfer-property=PENDING
          signal CAN4_PTG_Half_Lock: start 0, 1 bit, big-endian, i-signal-type=PRIMITIVE, init-value=constant-reference=Init_CAN4_PTG_Half_Lock, base-type=uint8, implementation-data-type=uint8, transfer-property=PENDING
          signal CAN4_PTG_Inner_SW_1: start 21, 2 bit, big-endian, i-signal-type=PRIMITIVE, init-value=constant-reference=Init_CAN4_PTG_Inner_SW_1, base-type=uint8, implementation-data-type=uint8, transfer-property=PENDING
          signal CAN4_PTG_Is_Set_Height: start 29, 1 bit, big-endian, i-signal-type=PRIMITIVE, init-value=constant-reference=Init_CAN4_PTG_Is_Set_Height, base-type=uint8, implementation-data-type=uint8, transfer-property=PENDING
          signal CAN4_PTG_Open_Ratio: start 7, 7 bit, big-endian, i-signal-type=PRIMITIVE, init-value=constant-reference=Init_CAN4_PTG_Open_Ratio, base-type=uint8, implementation-data-type=uint8, transfer-property=PENDING
          signal CAN4_PTG_RDIL_Sta: start 17, 2 bit, big-endian, i-signal-type=PRIMITIVE, init-value=constant-reference=Init_CAN4_PTG_RDIL_Sta, base-type=uint8, implementation-data-type=uint8, transfer-property=PENDING
          signal CAN4_PTG_SW_Ver: start 52, 5 bit, big-endian, i-signal-type=PRIMITIVE, init-value=constant-reference=Init_CAN4_PTG_SW_Ver, base-type=uint8, implementation-data-type=uint8, transfer-property=PENDING
          signal CAN4_PTG_Strut_Current: start 39, 8 bit, big-endian, i-signal-type=PRIMITIVE, init-value=constant-reference=Init_CAN4_PTG_Strut_Current, base-type=uint8, implementation-data-type=uint8, transfer-property=PENDING
          signal CAN4_PTG_Sys_Sta: start 23, 2 bit, big-endian, i-signal-type=PRIMITIVE, init-value=constant-reference=Init_CAN4_PTG_Sys_Sta, base-type=uint8, implementation-data-type=uint8, transfer-property=PENDING
          signal CAN4_PTG_Warning_Sta: start 15, 4 bit, big-endian, i-signal-type=PRIMITIVE, init-value=constant-reference=Init_CAN4_PTG_Warning_Sta, base-type=uint8, implementation-data-type=uint8, transfer-property=PENDING
      frame CAN4_GW_ZoneDR1: id 0x226, frame-length=16, can-addressing-mode=STANDARD, can-fd-frame-support=true, can-frame-rx-behavior=CAN-FD, can-frame-tx-behavior=CAN-FD
        pdu CAN4_GW_ZoneDR1: length=16, minimum-delay=0.0, transmission-mode-true-timing={cyclic-timing=time-period=0.2, event-controlled-timing={number-of-repetitions=0, repetition-period=0.05}}, unused-bit-pattern=0
          mapping CAN4_SG_GW_ZoneDR1: i-signal-group=CAN4_SG_GW_ZoneDR1, start-position=0, transfer-property=TRIGGERED-ON-CHANGE
          signal CAN4_AllLockSta: start 60, 1 bit, big-endian, i-signal-type=PRIMITIVE, init-value=constant-reference=Init_CAN4_AllLockSta, base-type=uint8, implementation-data-type=uint8, transfer-property=TRIGGERED-ON-CHANGE
          signal CAN4_AutoLightSW: start 3, 1 bit, big-endian, i-signal-type=PRIMITIVE, init-value=constant-reference=Init_CAN4_AutoLightSW, base-type=uint8, implementation-data-type=uint8, transfer-property=TRIGGERED-ON-CHANGE
          signal CAN4_BrakeLampFail: start 53, 1 bit, big-endian, i-signal-type=PRIMITIVE, init-value=constant-reference=Init_CAN4_BrakeLampFail, base-type=uint8, implementation-data-type=uint8, transfer-property=TRIGGERED-ON-CHANGE
          signal CAN4_CSW_DimSw: start 52, 1 bit, big-endian, i-signal-type=PRIMITIVE, init-value=constant-reference=Init_CAN4_CSW_DimSw, base-type=uint8, implementation-data-type=uint8, transfer-property=TRIGGERED-ON-CHANGE
          signal CAN4_CSW_FWasSw_Sta: start 25, 2 bit, big-endian, i-signal-type=PRIMITIVE, init-value=constant-reference=Init_CAN4_CSW_FWasSw_Sta, base-type=uint8, implementation-data-type=uint8, transfer-property=TRIGGERED-ON-CHANGE
          signal CAN4_CSW_FWipSw_Sta: start 18, 3 bit, big-endian, i-signal-type=PRIMITIVE, init-value=constant-reference=Init_CAN4_CSW_FWipSw_Sta, base-type=uint8, implementation-data-type=uint8, transfer-property=TRIGGERED-ON-CHANGE
          signal CAN4_CSW_HW_version: start 71, 16 bit, big-endian, i-signal-type=PRIMITIVE, init-value=constant-reference=Init_CAN4_CSW_HW_version, base-type=uint16, implementation-data-type=uint16, transfer-property=PENDING
          signal CAN4_CSW_PassSW_Sta: start 54, 1 bit, big-endian, i-signal-type=PRIMITIVE, init-value=constant-reference=Init_CAN4_CSW_PassSW_Sta, base-type=uint8, implementation-data-type=uint8, transfer-property=TRIGGERED-ON-CHANGE
          signal CAN4_CSW_RWasSW_Sta: start 27, 2 bit, big-endian, i-signal-type=PRIMITIVE, init-value=constant-reference=Init_CAN4_CSW_RWasSW_Sta, base-type=uint8, implementation-data-type=uint8, transfer-property=TRIGGERED-ON-CHANGE
          signal CAN4_CSW_RWipIntSw_Sta: start 51, 2 bit, big-endian, i-signal-type=PRIMITIVE, init-value=constant-reference=Init_CAN4_CSW_RWipIntSw_Sta, base-type=uint8, implementation-data-type=uint8, transfer-property=TRIGGERED-ON-CHANGE
          signal CAN4_CSW_SW_version: start 87, 16 bit, big-endian, i-signal-type=PRIMITIVE, init-value=constant-reference=Init_CAN4_CSW_SW_version, base-type=uint16, implementation-data-type=uint16, transfer-property=PENDING
          signal CAN4_CSW_TurnSw_Sta: start 29, 2 bit, big-endian, i-signal-type=PRIMITIVE, init-value=constant-reference=Init_CAN4_CSW_TurnSw_Sta, base-type=uint8, implementation-data-type=uint8, transfer-property=TRIGGERED-ON-CHANGE
          signal CAN4_CSW_resp_error: start 2, 1 bit, big-endian, i-signal-type=PRIMITIVE, init-value=constant-reference=Init_CAN4_CSW_resp_error, base-type=uint8, implementation-data-type=uint8, transfer-property=TRIGGERED-ON-CHANGE
          signal CAN4_DrLockSta: start 56, 1 bit, big-endian, i-signal-type=PRIMITIVE, init-value=constant-reference=Init_CAN4_DrLockSta, base-type=uint8, implementation-data-type=uint8, transfer-property=TRIGGERED-ON-CHANGE
          signal CAN4_HornSW: start 30, 1 bit, big-endian, i-signal-type=PRIMITIVE, init-value=constant-reference=Init_CAN4_HornSW, base-type=uint8, implementation-data-type=uint8, transfer-property=TRIGGERED-ON-CHANGE
          signal CAN4_MIRROR_FOLD_SW: start 61, 1 bit, big-endian, i-signal-type=PRIMITIVE, init-value=constant-reference=Init_CAN4_MIRROR_FOLD_SW, base-type=uint8, implementation-data-type=uint8, transfer-property=TRIGGERED-ON-CHANGE
          signal CAN4_PsLockSta: start 57, 1 bit, big-endian, i-signal-type=PRIMITIVE, init-value=constant-reference=Init_CAN4_PsLockSta, base-type=uint8, implementation-data-type=uint8, transfer-property=TRIGGERED-ON-CHANGE
          signal CAN4_RLLockSta: start 58, 1 bit, big-endian, i-signal-type=PRIMITIVE, init-value=constant-reference=Init_CAN4_RLLockSta, base-type=uint8, implementation-data-type=uint8, transfer-property=TRIGGERED-ON-CHANGE
          signal CAN4_RLS_Exist: start 55, 1 bit, big-endian, i-signal-type=PRIMITIVE, init-value=constant-reference=Init_CAN4_RLS_Exist, base-type=uint8, implementation-data-type=uint8, transfer-property=TRIGGERED-ON-CHANGE
          signal CAN4_RLS_LIN_Resp_Err: start 7, 1 bit, big-endian, i-signal-type=PRIMITIVE, init-value=constant-reference=Init_CAN4_RLS_LIN_Resp_Err, base-type=uint8, implementation-data-type=uint8, transfer-property=TRIGGERED-ON-CHANGE
          signal CAN4_RLS_Lamp_Sta: start 23, 1 bit, big-endian, i-signal-type=PRIMITIVE, init-value=constant-reference=Init_CAN4_RLS_Lamp_Sta, base-type=uint8, implementation-data-type=uint8, transfer-property=TRIGGERED-ON-CHANGE
          signal CAN4_RLS_LightSnrErr: start 6, 1 bit, big-endian, i-signal-type=PRIMITIVE, init-value=constant-reference=Init_CAN4_RLS_LightSnrErr, base-type=uint8, implementation-data-type=uint8, transfer-property=TRIGGERED-ON-CHANGE
          signal CAN4_RLS_RainSnrErr: start 5, 1 bit, big-endian, i-signal-type=PRIMITIVE, init-value=constant-reference=Init_CAN4_RLS_RainSnrErr, base-type=uint8, implementation-data-type=uint8, transfer-property=TRIGGERED-ON-CHANGE
          signal CAN4_RLS_RainSnrWiperCmd: start 22, 3 bit, big-endian, i-signal-type=PRIMITIVE, init-value=constant-reference=Init_CAN4_RLS_RainSnrWiperCmd, base-type=uint8, implementation-data-type=uint8, transfer-property=TRIGGERED-ON-CHANGE
          signal CAN4_RLTurnLampC: start 47, 8 bit, big-endian, i-signal-type=PRIMITIVE, init-value=constant-reference=Init_CAN4_RLTurnLampC, base-type=uint8, implementation-data-type=uint8, transfer-property=TRIGGERED-ON-CHANGE
          signal CAN4_RRLockSta: start 59, 1 bit, big-endian, i-signal-type=PRIMITIVE, init-value=constant-reference=Init_CAN4_RRLockSta, base-type=uint8, implementation-data-type=uint8, transfer-property=TRIGGERED-ON-CHANGE
          signal CAN4_RRTurnLampC: start 39, 8 bit, big-endian, i-signal-type=PRIMITIVE, init-value=constant-reference=Init_CAN4_RRTurnLampC, base-type=uint8, implementation-data-type=uint8, transfer-property=TRIGGERED-ON-CHANGE
          signal CAN4_RWiperAS: start 62, 1 bit, big-endian, i-signal-type=PRIMITIVE, init-value=constant-reference=Init_CAN4_RWiperAS, base-type=uint8, implementation-data-type=uint8, transfer-property=TRIGGERED-ON-CHANGE
          signal CAN4_RWiperProtection: start 63, 1 bit, big-endian, i-signal-type=PRIMITIVE, init-value=constant-reference=Init_CAN4_RWiperProtection, base-type=uint8, implementation-data-type=uint8, transfer-property=TRIGGERED-ON-CHANGE
          signal CAN4_Wip_Speed: start 49, 2 bit, big-endian, i-signal-type=PRIMITIVE, init-value=constant-reference=Init_CAN4_Wip_Speed, base-type=uint8, implementation-data-type=uint8, transfer-property=TRIGGERED-ON-CHANGE
          signal CAN4_WiperSWPos: start 15, 8 bit, big-endian, i-signal-type=PRIMITIVE, init-value=constant-reference=Init_CAN4_WiperSWPos, base-type=uint8, implementation-data-type=uint8, transfer-property=TRIGGERED-ON-CHANGE
          signal CAN4_WiperZeroPosSW: start 4, 1 bit, big-endian, i-signal-type=PRIMITIVE, init-value=constant-reference=Init_CAN4_WiperZeroPosSW, base-type=uint8, implementation-data-type=uint8, transfer-property=TRIGGERED-ON-CHANGE
      frame CAN4_GW_ZoneDR2: id 0x33A, frame-length=8, can-addressing-mode=STANDARD, can-fd-frame-support=true, can-frame-rx-behavior=CAN-FD, can-frame-tx-behavior=CAN-FD
        pdu CAN4_GW_ZoneDR2: length=8, minimum-delay=0.0, transmission-mode-true-timing={cyclic-timing=time-period=0.2, event-controlled-timing={number-of-repetitions=0, repetition-period=0.01}}, unused-bit-pattern=0
          mapping CAN4_SG_GW_ZoneDR2: i-signal-group=CAN4_SG_GW_ZoneDR2, start-position=0, transfer-property=TRIGGERED-ON-CHANGE
          signal CAN4_SWC_ACC_Sta: start 36, 1 bit, big-endian, i-signal-type=PRIMITIVE, init-value=constant-reference=Init_CAN4_SWC_ACC_Sta, base-type=uint8, implementation-data-type=uint8, transfer-property=TRIGGERED-ON-CHANGE
          signal CAN4_SWC_A_HW_version: start 23, 16 bit, big-endian, i-signal-type=PRIMITIVE, init-value=constant-reference=Init_CAN4_SWC_A_HW_version, base-type=uint16, implementation-data-type=uint16, transfer-property=PENDING
          signal CAN4_SWC_A_Resp_Err: start 34, 1 bit, big-endian, i-signal-type=PRIMITIVE, init-value=constant-reference=Init_CAN4_SWC_A_Resp_Err, base-type=uint8, implementation-data-type=uint8, transfer-property=PENDING
          signal CAN4_SWC_A_SW_version: start 7, 16 bit, big-endian, i-signal-type=PRIMITIVE, init-value=constant-reference=Init_CAN4_SWC_A_SW_version, base-type=uint16, implementation-data-type=uint16, transfer-property=PENDING
          signal CAN4_SWC_CANCEL_Sta: start 37, 1 bit, big-endian, i-signal-type=PRIMITIVE, init-value=constant-reference=Init_CAN4_SWC_CANCEL_Sta, base-type=uint8, implementation-data-type=uint8, transfer-property=TRIGGERED-ON-CHANGE
          signal CAN4_SWC_Distance_Sta: start 32, 1 bit, big-endian, i-signal-type=PRIMITIVE, init-value=constant-reference=Init_CAN4_SWC_Distance_Sta, base-type=uint8, implementation-data-type=uint8, transfer-property=TRIGGERED-ON-CHANGE
          signal CAN4_SWC_Down_Sta: start 47, 1 bit, big-endian, i-signal-type=PRIMITIVE, init-value=constant-reference=Init_CAN4_SWC_Down_Sta, base-type=uint8, implementation-data-type=uint8, transfer-property=TRIGGERED-ON-CHANGE
          signal CAN4_SWC_Drivemode_Sta: start 39, 2 bit, big-endian, i-signal-type=PRIMITIVE, init-value=constant-reference=Init_CAN4_SWC_Drivemode_Sta, base-type=uint8, implementation-data-type=uint8, transfer-property=PENDING
          signal CAN4_SWC_LKA_Sta: start 61, 1 bit, big-endian, i-signal-type=PRIMITIVE, init-value=constant-reference=Init_CAN4_SWC_LKA_Sta, base-type=uint8, implementation-data-type=uint8, transfer-property=TRIGGERED-ON-CHANGE
          signal CAN4_SWC_Left_Sta: start 45, 1 bit, big-endian, i-signal-type=PRIMITIVE, init-value=constant-reference=Init_CAN4_SWC_Left_Sta, base-type=uint8, implementation-data-type=uint8, transfer-property=TRIGGERED-ON-CHANGE
          signal CAN4_SWC_RegenDown: start 53, 1 bit, big-endian, i-signal-type=PRIMITIVE, init-value=constant-reference=Init_CAN4_SWC_RegenDown, base-type=uint8, implementation-data-type=uint8, transfer-property=TRIGGERED-ON-CHANGE
          signal CAN4_SWC_RegenUp: start 46, 1 bit, big-endian, i-signal-type=PRIMITIVE, init-value=constant-reference=Init_CAN4_SWC_RegenUp, base-type=uint8, implementation-data-type=uint8, transfer-property=TRIGGERED-ON-CHANGE
          signal CAN4_SWC_Res_Up_Sta: start 54, 1 bit, big-endian, i-signal-type=PRIMITIVE, init-value=constant-reference=Init_CAN4_SWC_Res_Up_Sta, base-type=uint8, implementation-data-type=uint8, transfer-property=TRIGGERED-ON-CHANGE
          signal CAN4_SWC_Right_Sta: start 52, 1 bit, big-endian, i-signal-type=PRIMITIVE, init-value=constant-reference=Init_CAN4_SWC_Right_Sta, base-type=uint8, implementation-data-type=uint8, transfer-property=TRIGGERED-ON-CHANGE
          signal CAN4_SWC_Set_down_Sta: start 51, 1 bit, big-endian, i-signal-type=PRIMITIVE, init-value=constant-reference=Init_CAN4_SWC_Set_down_Sta, base-type=uint8, implementation-data-type=uint8, transfer-property=TRIGGERED-ON-CHANGE
          signal CAN4_SWC_Trip_Sta: start 50, 1 bit, big-endian, i-signal-type=PRIMITIVE, init-value=constant-reference=Init_CAN4_SWC_Trip_Sta, base-type=uint8, implementation-data-type=uint8, transfer-property=TRIGGERED-ON-CHANGE
          signal CAN4_SWC_Undefined_Sta: start 62, 1 bit, big-endian, i-signal-type=PRIMITIVE, init-value=constant-reference=Init_CAN4_SWC_Undefined_Sta, base-type=uint8, implementation-data-type=uint8, transfer-property=TRIGGERED-ON-CHANGE
          signal CAN4_SWC_Up_Sta: start 48, 1 bit, big-endian, i-signal-type=PRIMITIVE, init-value=constant-reference=Init_CAN4_SWC_Up_Sta, base-type=uint8, implementation-data-type=uint8, transfer-property=TRIGGERED-ON-CHANGE
          signal CAN4_SWC_VR_Sta: start 63, 1 bit, big-endian, i-signal-type=PRIMITIVE, init-value=constant-reference=Init_CAN4_SWC_VR_Sta, base-type=uint8, implementation-data-type=uint8, transfer-property=TRIGGERED-ON-CHANGE
          signal CAN4_SWC_mode_Sta: start 43, 1 bit, big-endian, i-signal-type=PRIMITIVE, init-value=constant-reference=Init_CAN4_SWC_mode_Sta, base-type=uint8, implementation-data-type=uint8, transfer-property=TRIGGERED-ON-CHANGE
          signal CAN4_SWC_resp_error: start 55, 1 bit, big-endian, i-signal-type=PRIMITIVE, init-value=constant-reference=Init_CAN4_SWC_resp_error, base-type=uint8, implementation-data-type=uint8, transfer-property=PENDING
      frame CAN4_GW_ZoneDR3: id 0x356, frame-length=8, can-addressing-mode=STANDARD, can-fd-frame-support=true, can-frame-rx-behavior=CAN-FD, can-frame-tx-behavior=CAN-FD
        pdu CAN4_GW_ZoneDR3: length=8, minimum-delay=0.0, transmission-mode-true-timing=cyclic-timing=time-period=0.1, unused-bit-pattern=0
          mapping CAN4_SG_GW_ZoneDR3: i-signal-group=CAN4_SG_GW_ZoneDR3, start-position=0, transfer-property=PENDING
          signal CAN4_FAPWL_01_LIN_Response_Error: start 45, 1 bit, big-endian, i-signal-type=PRIMITIVE, init-value=constant-reference=Init_CAN4_FAPWL_01_LIN_Response_Error, base-type=uint8, implementation-data-type=uint8, transfer-property=PENDING
          signal CAN4_L_APM_IntellectClose: start 7, 1 bit, big-endian, i-signal-type=PRIMITIVE, init-value=constant-reference=Init_CAN4_L_APM_IntellectClose, base-type=uint8, implementation-data-type=uint8, transfer-property=PENDING
          signal CAN4_L_Drv_Motor_Relay_Error: start 40, 1 bit, big-endian, i-signal-type=PRIMITIVE, init-value=constant-reference=Init_CAN4_L_Drv_Motor_Relay_Error, base-type=uint8, implementation-data-type=uint8, transfer-property=PENDING
          signal CAN4_L_Drv_Motor_Ripple_Error: start 55, 1 bit, big-endian, i-signal-type=PRIMITIVE, init-value=constant-reference=Init_CAN4_L_Drv_Motor_Ripple_Error, base-type=uint8, implementation-data-type=uint8, transfer-property=PENDING
          signal CAN4_L_Drv_OverHeat_Protect: start 41, 1 bit, big-endian, i-signal-type=PRIMITIVE, init-value=constant-reference=Init_CAN4_L_Drv_OverHeat_Protect, base-type=uint8, implementation-data-type=uint8, transfer-property=PENDING
          signal CAN4_L_Drv_Val_Wdw_Opened: start 54, 7 bit, big-endian, i-signal-type=PRIMITIVE, init-value=constant-reference=Init_CAN4_L_Drv_Val_Wdw_Opened, base-type=uint8, implementation-data-type=uint8, transfer-property=PENDING
          signal CAN4_L_Drv_Wdw_Init: start 42, 1 bit, big-endian, i-signal-type=PRIMITIVE, init-value=constant-reference=Init_CAN4_L_Drv_Wdw_Init, base-type=uint8, implementation-data-type=uint8, transfer-property=PENDING
          signal CAN4_L_Drv_Wdw_LocalSwitch: start 61, 3 bit, big-endian, i-signal-type=PRIMITIVE, init-value=constant-reference=Init_CAN4_L_Drv_Wdw_LocalSwitch, base-type=uint8, implementation-data-type=uint8, transfer-property=PENDING
          signal CAN4_L_Drv_Wdw_OD_Sts: start 43, 1 bit, big-endian, i-signal-type=PRIMITIVE, init-value=constant-reference=Init_CAN4_L_Drv_Wdw_OD_Sts, base-type=uint8, implementation-data-type=uint8, transfer-property=PENDING
          signal CAN4_L_Drv_Wdw_Obs_InhibitSts: start 44, 1 bit, big-endian, i-signal-type=PRIMITIVE, init-value=constant-reference=Init_CAN4_L_Drv_Wdw_Obs_InhibitSts, base-type=uint8, implementation-data-type=uint8, transfer-property=PENDING
          signal CAN4_L_Drv_Wdw_Pas_Switch: start 11, 3 bit, big-endian, i-signal-type=PRIMITIVE, init-value=constant-reference=Init_CAN4_L_Drv_Wdw_Pas_Switch, base-type=uint8, implementation-data-type=uint8, transfer-property=PENDING
          signal CAN4_L_Drv_Wdw_PositionSts: start 63, 2 bit, big-endian, i-signal-type=PRIMITIVE, init-value=constant-reference=Init_CAN4_L_Drv_Wdw_PositionSts, base-type=uint8, implementation-data-type=uint8, transfer-property=PENDING
          signal CAN4_L_Drv_Wdw_RLD_Switch: start 14, 3 bit, big-endian, i-signal-type=PRIMITIVE, init-value=constant-reference=Init_CAN4_L_Drv_Wdw_RLD_Switch, base-type=uint8, implementation-data-type=uint8, transfer-property=PENDING
          signal CAN4_L_Drv_Wdw_RRD_Switch: start 1, 3 bit, big-endian, i-signal-type=PRIMITIVE, init-value=constant-reference=Init_CAN4_L_Drv_Wdw_RRD_Switch, base-type=uint8, implementation-data-type=uint8, transfer-property=PENDING
          signal CAN4_L_Drv_Wdw_Running_Sts: start 58, 3 bit, big-endian, i-signal-type=PRIMITIVE, init-value=constant-reference=Init_CAN4_L_Drv_Wdw_Running_Sts, base-type=uint8, implementation-data-type=uint8, transfer-property=PENDING
          signal CAN4_L_Pas_Motor_Relay_Error: start 17, 1 bit, big-endian, i-signal-type=PRIMITIVE, init-value=constant-reference=Init_CAN4_L_Pas_Motor_Relay_Error, base-type=uint8, implementation-data-type=uint8, transfer-property=PENDING
          signal CAN4_L_Pas_Motor_Ripple_Error: start 16, 1 bit, big-endian, i-signal-type=PRIMITIVE, init-value=constant-reference=Init_CAN4_L_Pas_Motor_Ripple_Error, base-type=uint8, implementation-data-type=uint8, transfer-property=PENDING
          signal CAN4_L_Pas_OverHeat_Protect: start 18, 1 bit, big-endian, i-signal-type=PRIMITIVE, init-value=constant-reference=Init_CAN4_L_Pas_OverHeat_Protect, base-type=uint8, implementation-data-type=uint8, transfer-property=PENDING
          signal CAN4_L_Pas_Val_Wdw_Opened: start 31, 7 bit, big-endian, i-signal-type=PRIMITIVE, init-value=constant-reference=Init_CAN4_L_Pas_Val_Wdw_Opened, base-type=uint8, implementation-data-type=uint8, transfer-property=PENDING
          signal CAN4_L_Pas_Wdw_Init: start 19, 1 bit, big-endian, i-signal-type=PRIMITIVE, init-value=constant-reference=Init_CAN4_L_Pas_Wdw_Init, base-type=uint8, implementation-data-type=uint8, transfer-property=PENDING
          signal CAN4_L_Pas_Wdw_LocalSwitch: start 37, 3 bit, big-endian, i-signal-type=PRIMITIVE, init-value=constant-reference=Init_CAN4_L_Pas_Wdw_LocalSwitch, base-type=uint8, implementation-data-type=uint8, transfer-property=PENDING
          signal CAN4_L_Pas_Wdw_OD_Sts: start 20, 1 bit, big-endian, i-signal-type=PRIMITIVE, init-value=constant-reference=Init_CAN4_L_Pas_Wdw_OD_Sts, base-type=uint8, implementation-data-type=uint8, transfer-property=PENDING
          signal CAN4_L_Pas_Wdw_Obs_InhibitSts: start 21, 1 bit, big-endian, i-signal-type=PRIMITIVE, init-value=constant-reference=Init_CAN4_L_Pas_Wdw_Obs_InhibitSts, base-type=uint8, implementation-data-type=uint8, transfer-property=PENDING
          signal CAN4_L_Pas_Wdw_PositionSts: start 39, 2 bit, big-endian, i-signal-type=PRIMITIVE, init-value=constant-reference=Init_CAN4_L_Pas_Wdw_PositionSts, base-type=uint8, implementation-data-type=uint8, transfer-property=PENDING
          signal CAN4_L_Pas_Wdw_Running_Sts: start 34, 3 bit, big-endian, i-signal-type=PRIMITIVE, init-value=constant-reference=Init_CAN4_L_Pas_Wdw_Running_Sts, base-type=uint8, implementation-data-type=uint8, transfer-property=PENDING
          signal CAN4_L_Power_Status: start 47, 2 bit, big-endian, i-signal-type=PRIMITIVE, init-value=constant-reference=Init_CAN4_L_Power_Status, base-type=uint8, implementation-data-type=uint8, transfer-property=PENDING
      frame CAN4_GW_ZoneDR4: id 0x353, frame-length=8, can-addressing-mode=STANDARD, can-fd-frame-support=true, can-frame-rx-behavior=CAN-FD, can-frame-tx-behavior=CAN-FD
        pdu CAN4_GW_ZoneDR4: length=8, minimum-delay=0.0, transmission-mode-true-timing={cyclic-timing=time-period=0.1, event-controlled-timing={number-of-repetitions=0, repetition-period=0}}, unused-bit-pattern=0
          mapping CAN4_SG_GW_ZoneDR4: i-signal-group=CAN4_SG_GW_ZoneDR4, start-position=0, transfer-property=TRIGGERED-ON-CHANGE
          signal CAN4_L_RLD_Motor_Relay_Error: start 40, 1 bit, big-endian, i-signal-type=PRIMITIVE, init-value=constant-reference=Init_CAN4_L_RLD_Motor_Relay_Error, base-type=uint8, implementation-data-type=uint8, transfer-property=PENDING
          signal CAN4_L_RLD_Motor_Ripple_Error: start 55, 1 bit, big-endian, i-signal-type=PRIMITIVE, init-value=constant-reference=Init_CAN4_L_RLD_Motor_Ripple_Error, base-type=uint8, implementation-data-type=uint8, transfer-property=PENDING
          signal CAN4_L_RLD_OverHeat_Protect: start 41, 1 bit, big-endian, i-signal-type=PRIMITIVE, init-value=constant-reference=Init_CAN4_L_RLD_OverHeat_Protect, base-type=uint8, implementation-data-type=uint8, transfer-property=PENDING
          signal CAN4_L_RLD_Val_Wdw_Opened: start 54, 7 bit, big-endian, i-signal-type=PRIMITIVE, init-value=constant-reference=Init_CAN4_L_RLD_Val_Wdw_Opened, base-type=uint8, implementation-data-type=uint8, transfer-property=PENDING
          signal CAN4_L_RLD_Wdw_Init: start 42, 1 bit, big-endian, i-signal-type=PRIMITIVE, init-value=constant-reference=Init_CAN4_L_RLD_Wdw_Init, base-type=uint8, implementation-data-type=uint8, transfer-property=PENDING
          signal CAN4_L_RLD_Wdw_LocalSwitch: start 61, 3 bit, big-endian, i-signal-type=PRIMITIVE, init-value=constant-reference=Init_CAN4_L_RLD_Wdw_LocalSwitch, base-type=uint8, implementation-data-type=uint8, transfer-property=PENDING
          signal CAN4_L_RLD_Wdw_OD_Sts: start 43, 1 bit, big-endian, i-signal-type=PRIMITIVE, init-value=constant-reference=Init_CAN4_L_RLD_Wdw_OD_Sts, base-type=uint8, implementation-data-type=uint8, transfer-property=PENDING
          signal CAN4_L_RLD_Wdw_Obs_InhibitSts: start 44, 1 bit, big-endian, i-signal-type=PRIMITIVE, init-value=constant-reference=Init_CAN4_L_RLD_Wdw_Obs_InhibitSts, base-type=uint8, implementation-data-type=uint8, transfer-property=PENDING
          signal CAN4_L_RLD_Wdw_PositionSts: start 63, 2 bit, big-endian, i-signal-type=PRIMITIVE, init-value=constant-reference=Init_CAN4_L_RLD_Wdw_PositionSts, base-type=uint8, implementation-data-type=uint8, transfer-property=PENDING
          signal CAN4_L_RLD_Wdw_Running_Sts: start 58, 3 bit, big-endian, i-signal-type=PRIMITIVE, init-value=constant-reference=Init_CAN4_L_RLD_Wdw_Running_Sts, base-type=uint8, implementation-data-type=uint8, transfer-property=PENDING
          signal CAN4_L_RRD_Motor_Relay_Error: start 16, 1 bit, big-endian, i-signal-type=PRIMITIVE, init-value=constant-reference=Init_CAN4_L_RRD_Motor_Relay_Error, base-type=uint8, implementation-data-type=uint8, transfer-property=PENDING
          signal CAN4_L_RRD_Motor_Ripple_Error: start 31, 1 bit, big-endian, i-signal-type=PRIMITIVE, init-value=constant-reference=Init_CAN4_L_RRD_Motor_Ripple_Error, base-type=uint8, implementation-data-type=uint8, transfer-property=PENDING
          signal CAN4_L_RRD_OverHeat_Protect: start 17, 1 bit, big-endian, i-signal-type=PRIMITIVE, init-value=constant-reference=Init_CAN4_L_RRD_OverHeat_Protect, base-type=uint8, implementation-data-type=uint8, transfer-property=PENDING
          signal CAN4_L_RRD_Val_Wdw_Opened: start 30, 7 bit, big-endian, i-signal-type=PRIMITIVE, init-value=constant-reference=Init_CAN4_L_RRD_Val_Wdw_Opened, base-type=uint8, implementation-data-type=uint8, transfer-property=PENDING
          signal CAN4_L_RRD_Wdw_Init: start 18, 1 bit, big-endian, i-signal-type=PRIMITIVE, init-value=constant-reference=Init_CAN4_L_RRD_Wdw_Init, base-type=uint8, implementation-data-type=uint8, transfer-property=PENDING
          signal CAN4_L_RRD_Wdw_LocalSwitch: start 37, 3 bit, big-endian, i-signal-type=PRIMITIVE, init-value=constant-reference=Init_CAN4_L_RRD_Wdw_LocalSwitch, base-type=uint8, implementation-data-type=uint8, transfer-property=PENDING
          signal CAN4_L_RRD_Wdw_OD_Sts: start 19, 1 bit, big-endian, i-signal-type=PRIMITIVE, init-value=constant-reference=Init_CAN4_L_RRD_Wdw_OD_Sts, base-type=uint8, implementation-data-type=uint8, transfer-property=PENDING
          signal CAN4_L_RRD_Wdw_Obs_InhibitSts: start 20, 1 bit, big-endian, i-signal-type=PRIMITIVE, init-value=constant-reference=Init_CAN4_L_RRD_Wdw_Obs_InhibitSts, base-type=uint8, implementation-data-type=uint8, transfer-property=PENDING
          signal CAN4_L_RRD_Wdw_PositionSts: start 39, 2 bit, big-endian, i-signal-type=PRIMITIVE, init-value=constant-reference=Init_CAN4_L_RRD_Wdw_PositionSts, base-type=uint8, implementation-data-type=uint8, transfer-property=PENDING
          signal CAN4_L_RRD_Wdw_Running_Sts: start 34, 3 bit, big-endian, i-signal-type=PRIMITIVE, init-value=constant-reference=Init_CAN4_L_RRD_Wdw_Running_Sts, base-type=uint8, implementation-data-type=uint8, transfer-property=PENDING
          signal CAN4_PTG_Inner_SW_2: start 47, 2 bit, big-endian, i-signal-type=PRIMITIVE, init-value=constant-reference=Init_CAN4_PTG_Inner_SW_2, base-type=uint8, implementation-data-type=uint8, transfer-property=TRIGGERED-ON-CHANGE
          signal CAN4_RAPWL_01_LIN_Response_Error: start 45, 1 bit, big-endian, i-signal-type=PRIMITIVE, init-value=constant-reference=Init_CAN4_RAPWL_01_LIN_Response_Error, base-type=uint8, implementation-data-type=uint8, transfer-property=PENDING
      frame CAN4_GW_ZoneDR6: id 0x223, frame-length=24, can-addressing-mode=STANDARD, can-fd-frame-support=true, can-frame-rx-behavior=CAN-FD, can-frame-tx-behavior=CAN-FD
        pdu CAN4_GW_ZoneDR6: length=24, minimum-delay=0.0, transmission-mode-true-timing=cyclic-timing=time-period=0.1, unused-bit-pattern=0
          mapping CAN4_SG_GW_ZoneDR6: i-signal-group=CAN4_SG_GW_ZoneDR6, start-position=0, transfer-property=PENDING
          signal CAN4_FrntPTCBusLineHiV: start 177, 10 bit, big-endian, i-signal-type=PRIMITIVE, init-value=constant-reference=Init_CAN4_FrntPTCBusLineHiV, base-type=uint16, implementation-data-type=uint16, transfer-property=PENDING
          signal CAN4_FrntPTCComFlt: start 20, 1 bit, big-endian, i-signal-type=PRIMITIVE, init-value=constant-reference=Init_CAN4_FrntPTCComFlt, base-type=uint8, implementation-data-type=uint8, transfer-property=PENDING
          signal CAN4_FrntPTCFltSt: start 6, 2 bit, big-endian, i-signal-type=PRIMITIVE, init-value=constant-reference=Init_CAN4_FrntPTCFltSt, base-type=uint8, implementation-data-type=uint8, transfer-property=PENDING
          signal CAN4_FrntPTCHVOverUFlt: start 1, 1 bit, big-endian, i-signal-type=PRIMITIVE, init-value=constant-reference=Init_CAN4_FrntPTCHVOverUFlt, base-type=uint8, implementation-data-type=uint8, transfer-property=PENDING
          signal CAN4_FrntPTCHVUnderUFlt: start 2, 1 bit, big-endian, i-signal-type=PRIMITIVE, init-value=constant-reference=Init_CAN4_FrntPTCHVUnderUFlt, base-type=uint8, implementation-data-type=uint8, transfer-property=PENDING
          signal CAN4_FrntPTCHWVers: start 39, 8 bit, big-endian, i-signal-type=PRIMITIVE, init-value=constant-reference=Init_CAN4_FrntPTCHWVers, base-type=uint8, implementation-data-type=uint8, transfer-property=PENDING
          signal CAN4_FrntPTCLVOverUFlt: start 3, 1 bit, big-endian, i-signal-type=PRIMITIVE, init-value=constant-reference=Init_CAN4_FrntPTCLVOverUFlt, base-type=uint8, implementation-data-type=uint8, transfer-property=PENDING
          signal CAN4_FrntPTCLVUnderUFlt: start 4, 1 bit, big-endian, i-signal-type=PRIMITIVE, init-value=constant-reference=Init_CAN4_FrntPTCLVUnderUFlt, base-type=uint8, implementation-data-type=uint8, transfer-property=PENDING
          signal CAN4_FrntPTCLeActHeatPwr: start 87, 8 bit, big-endian, i-signal-type=PRIMITIVE, init-value=constant-reference=Init_CAN4_FrntPTCLeActHeatPwr, base-type=uint8, implementation-data-type=uint8, transfer-property=PENDING
          signal CAN4_FrntPTCLeBusLineC: start 167, 8 bit, big-endian, i-signal-type=PRIMITIVE, init-value=constant-reference=Init_CAN4_FrntPTCLeBusLineC, base-type=uint8, implementation-data-type=uint8, transfer-property=PENDING
          signal CAN4_FrntPTCLeCoreOverTFlt: start 12, 1 bit, big-endian, i-signal-type=PRIMITIVE, init-value=constant-reference=Init_CAN4_FrntPTCLeCoreOverTFlt, base-type=uint8, implementation-data-type=uint8, transfer-property=PENDING
          signal CAN4_FrntPTCLeCoreT: start 71, 8 bit, big-endian, i-signal-type=PRIMITIVE, init-value=constant-reference=Init_CAN4_FrntPTCLeCoreT, base-type=uint8, implementation-data-type=uint8, transfer-property=PENDING
          signal CAN4_FrntPTCLeCoreTSnsrFlt: start 14, 1 bit, big-endian, i-signal-type=PRIMITIVE, init-value=constant-reference=Init_CAN4_FrntPTCLeCoreTSnsrFlt, base-type=uint8, implementation-data-type=uint8, transfer-property=PENDING
          signal CAN4_FrntPTCLeIGBTOverTFlt: start 17, 1 bit, big-endian, i-signal-type=PRIMITIVE, init-value=constant-reference=Init_CAN4_FrntPTCLeIGBTOverTFlt, base-type=uint8, implementation-data-type=uint8, transfer-property=PENDING
          signal CAN4_FrntPTCLeIGBTShoCircFlt: start 10, 1 bit, big-endian, i-signal-type=PRIMITIVE, init-value=constant-reference=Init_CAN4_FrntPTCLeIGBTShoCircFlt, base-type=uint8, implementation-data-type=uint8, transfer-property=PENDING
          signal CAN4_FrntPTCLeIGBTT: start 103, 8 bit, big-endian, i-signal-type=PRIMITIVE, init-value=constant-reference=Init_CAN4_FrntPTCLeIGBTT, base-type=uint8, implementation-data-type=uint8, transfer-property=PENDING
          signal CAN4_FrntPTCLeIGBTTSnsrFlt: start 19, 1 bit, big-endian, i-signal-type=PRIMITIVE, init-value=constant-reference=Init_CAN4_FrntPTCLeIGBTTSnsrFlt, base-type=uint8, implementation-data-type=uint8, transfer-property=PENDING
          signal CAN4_FrntPTCLeOpentCircFlt: start 8, 1 bit, big-endian, i-signal-type=PRIMITIVE, init-value=constant-reference=Init_CAN4_FrntPTCLeOpentCircFlt, base-type=uint8, implementation-data-type=uint8, transfer-property=PENDING
          signal CAN4_FrntPTCLeOverAFlt: start 0, 1 bit, big-endian, i-signal-type=PRIMITIVE, init-value=constant-reference=Init_CAN4_FrntPTCLeOverAFlt, base-type=uint8, implementation-data-type=uint8, transfer-property=PENDING
          signal CAN4_FrntPTCPCBOverTFlt: start 21, 1 bit, big-endian, i-signal-type=PRIMITIVE, init-value=constant-reference=Init_CAN4_FrntPTCPCBOverTFlt, base-type=uint8, implementation-data-type=uint8, transfer-property=PENDING
          signal CAN4_FrntPTCPCBT: start 119, 8 bit, big-endian, i-signal-type=PRIMITIVE, init-value=constant-reference=Init_CAN4_FrntPTCPCBT, base-type=uint8, implementation-data-type=uint8, transfer-property=PENDING
          signal CAN4_FrntPTCPCBTSnsrFlt: start 22, 1 bit, big-endian, i-signal-type=PRIMITIVE, init-value=constant-reference=Init_CAN4_FrntPTCPCBTSnsrFlt, base-type=uint8, implementation-data-type=uint8, transfer-property=PENDING
          signal CAN4_FrntPTCRearLeActHeatPwr: start 135, 8 bit, big-endian, i-signal-type=PRIMITIVE, init-value=constant-reference=Init_CAN4_FrntPTCRearLeActHeatPwr, base-type=uint8, implementation-data-type=uint8, transfer-property=PENDING
          signal CAN4_FrntPTCRearLeBusLineC: start 63, 8 bit, big-endian, i-signal-type=PRIMITIVE, init-value=constant-reference=Init_CAN4_FrntPTCRearLeBusLineC, base-type=uint8, implementation-data-type=uint8, transfer-property=PENDING
          signal CAN4_FrntPTCRearLeCoreOverTFlt: start 40, 1 bit, big-endian, i-signal-type=PRIMITIVE, init-value=constant-reference=Init_CAN4_FrntPTCRearLeCoreOverTFlt, base-type=uint8, implementation-data-type=uint8, transfer-property=PENDING
          signal CAN4_FrntPTCRearLeCoreT: start 143, 8 bit, big-endian, i-signal-type=PRIMITIVE, init-value=constant-reference=Init_CAN4_FrntPTCRearLeCoreT, base-type=uint8, implementation-data-type=uint8, transfer-property=PENDING
          signal CAN4_FrntPTCRearLeCoreTSnsrFlt: start 54, 1 bit, big-endian, i-signal-type=PRIMITIVE, init-value=constant-reference=Init_CAN4_FrntPTCRearLeCoreTSnsrFlt, base-type=uint8, implementation-data-type=uint8, transfer-property=PENDING
          signal CAN4_FrntPTCRearLeIGBTShoCFlt: start 50, 1 bit, big-endian, i-signal-type=PRIMITIVE, init-value=constant-reference=Init_CAN4_FrntPTCRearLeIGBTShoCFlt, base-type=uint8, implementation-data-type=uint8, transfer-property=PENDING
          signal CAN4_FrntPTCRearLeOpentCircFlt: start 42, 1 bit, big-endian, i-signal-type=PRIMITIVE, init-value=constant-reference=Init_CAN4_FrntPTCRearLeOpentCircFlt, base-type=uint8, implementation-data-type=uint8, transfer-property=PENDING
          signal CAN4_FrntPTCRearLeOverAFlt: start 43, 1 bit, big-endian, i-signal-type=PRIMITIVE, init-value=constant-reference=Init_CAN4_FrntPTCRearLeOverAFlt, base-type=uint8, implementation-data-type=uint8, transfer-property=PENDING
          signal CAN4_FrntPTCRearRiActHeatPwr: start 151, 8 bit, big-endian, i-signal-type=PRIMITIVE, init-value=constant-reference=Init_CAN4_FrntPTCRearRiActHeatPwr, base-type=uint8, implementation-data-type=uint8, transfer-property=PENDING
          signal CAN4_FrntPTCRearRiBusLineC: start 127, 8 bit, big-endian, i-signal-type=PRIMITIVE, init-value=constant-reference=Init_CAN4_FrntPTCRearRiBusLineC, base-type=uint8, implementation-data-type=uint8, transfer-property=PENDING
          signal CAN4_FrntPTCRearRiCoreOverTFlt: start 41, 1 bit, big-endian, i-signal-type=PRIMITIVE, init-value=constant-reference=Init_CAN4_FrntPTCRearRiCoreOverTFlt, base-type=uint8, implementation-data-type=uint8, transfer-property=PENDING
          signal CAN4_FrntPTCRearRiCoreT: start 159, 8 bit, big-endian, i-signal-type=PRIMITIVE, init-value=constant-reference=Init_CAN4_FrntPTCRearRiCoreT, base-type=uint8, implementation-data-type=uint8, transfer-property=PENDING
          signal CAN4_FrntPTCRearRiCoreTSnsrFlt: start 55, 1 bit, big-endian, i-signal-type=PRIMITIVE, init-value=constant-reference=Init_CAN4_FrntPTCRearRiCoreTSnsrFlt, base-type=uint8, implementation-data-type=uint8, transfer-property=PENDING
          signal CAN4_FrntPTCRearRiIGBTShoCFlt: start 51, 1 bit, big-endian, i-signal-type=PRIMITIVE, init-value=constant-reference=Init_CAN4_FrntPTCRearRiIGBTShoCFlt, base-type=uint8, implementation-data-type=uint8, transfer-property=PENDING
          signal CAN4_FrntPTCRearRiOpentCircFlt: start 52, 1 bit, big-endian, i-signal-type=PRIMITIVE, init-value=constant-reference=Init_CAN4_FrntPTCRearRiOpentCircFlt, base-type=uint8, implementation-data-type=uint8, transfer-property=PENDING
          signal CAN4_FrntPTCRearRiOverAFlt: start 53, 1 bit, big-endian, i-signal-type=PRIMITIVE, init-value=constant-reference=Init_CAN4_FrntPTCRearRiOverAFlt, base-type=uint8, implementation-data-type=uint8, transfer-property=PENDING
          signal CAN4_FrntPTCRiActHeatPwr: start 95, 8 bit, big-endian, i-signal-type=PRIMITIVE, init-value=constant-reference=Init_CAN4_FrntPTCRiActHeatPwr, base-type=uint8, implementation-data-type=uint8, transfer-property=PENDING
          signal CAN4_FrntPTCRiBusLineC: start 175, 8 bit, big-endian, i-signal-type=PRIMITIVE, init-value=constant-reference=Init_CAN4_FrntPTCRiBusLineC, base-type=uint8, implementation-data-type=uint8, transfer-property=PENDING
          signal CAN4_FrntPTCRiCoreOverTFlt: start 11, 1 bit, big-endian, i-signal-type=PRIMITIVE, init-value=constant-reference=Init_CAN4_FrntPTCRiCoreOverTFlt, base-type=uint8, implementation-data-type=uint8, transfer-property=PENDING
          signal CAN4_FrntPTCRiCoreT: start 79, 8 bit, big-endian, i-signal-type=PRIMITIVE, init-value=constant-reference=Init_CAN4_FrntPTCRiCoreT, base-type=uint8, implementation-data-type=uint8, transfer-property=PENDING
          signal CAN4_FrntPTCRiCoreTSnsrFlt: start 13, 1 bit, big-endian, i-signal-type=PRIMITIVE, init-value=constant-reference=Init_CAN4_FrntPTCRiCoreTSnsrFlt, base-type=uint8, implementation-data-type=uint8, transfer-property=PENDING
          signal CAN4_FrntPTCRiIGBTOverTFlt: start 16, 1 bit, big-endian, i-signal-type=PRIMITIVE, init-value=constant-reference=Init_CAN4_FrntPTCRiIGBTOverTFlt, base-type=uint8, implementation-data-type=uint8, transfer-property=PENDING
          signal CAN4_FrntPTCRiIGBTShoCircFlt: start 9, 1 bit, big-endian, i-signal-type=PRIMITIVE, init-value=constant-reference=Init_CAN4_FrntPTCRiIGBTShoCircFlt, base-type=uint8, implementation-data-type=uint8, transfer-property=PENDING
          signal CAN4_FrntPTCRiIGBTT: start 111, 8 bit, big-endian, i-signal-type=PRIMITIVE, init-value=constant-reference=Init_CAN4_FrntPTCRiIGBTT, base-type=uint8, implementation-data-type=uint8, transfer-property=PENDING
          signal CAN4_FrntPTCRiIGBTTSnsrFlt: start 18, 1 bit, big-endian, i-signal-type=PRIMITIVE, init-value=constant-reference=Init_CAN4_FrntPTCRiIGBTTSnsrFlt, base-type=uint8, implementation-data-type=uint8, transfer-property=PENDING
          signal CAN4_FrntPTCRiOpentCircFlt: start 23, 1 bit, big-endian, i-signal-type=PRIMITIVE, init-value=constant-reference=Init_CAN4_FrntPTCRiOpentCircFlt, base-type=uint8, implementation-data-type=uint8, transfer-property=PENDING
          signal CAN4_FrntPTCRiOverAFlt: start 15, 1 bit, big-endian, i-signal-type=PRIMITIVE, init-value=constant-reference=Init_CAN4_FrntPTCRiOverAFlt, base-type=uint8, implementation-data-type=uint8, transfer-property=PENDING
          signal CAN4_FrntPTCSWVers: start 31, 8 bit, big-endian, i-signal-type=PRIMITIVE, init-value=constant-reference=Init_CAN4_FrntPTCSWVers, base-type=uint8, implementation-data-type=uint8, transfer-property=PENDING
          signal CAN4_FrntPTCSts: start 7, 1 bit, big-endian, i-signal-type=PRIMITIVE, init-value=constant-reference=Init_CAN4_FrntPTCSts, base-type=uint8, implementation-data-type=uint8, transfer-property=PENDING
          signal CAN4_FrntPTCSupplierCod: start 47, 4 bit, big-endian, i-signal-type=PRIMITIVE, init-value=constant-reference=Init_CAN4_FrntPTCSupplierCod, base-type=uint8, implementation-data-type=uint8, transfer-property=PENDING
      frame CAN4_GW_ZoneFR1: id 0x228, frame-length=20, can-addressing-mode=STANDARD, can-fd-frame-support=true, can-frame-rx-behavior=CAN-FD, can-frame-tx-behavior=CAN-FD
        pdu CAN4_GW_ZoneFR1: length=20, minimum-delay=0.0, transmission-mode-true-timing={cyclic-timing=time-period=0.2, event-controlled-timing={number-of-repetitions=0, repetition-period=0.05}}, unused-bit-pattern=0
          mapping CAN4_SG_GW_ZoneFR1: i-signal-group=CAN4_SG_GW_ZoneFR1, start-position=0, transfer-property=TRIGGERED-ON-CHANGE
          signal CAN4_AGS_Actual_Position: start 7, 8 bit, big-endian, i-signal-type=PRIMITIVE, init-value=constant-reference=Init_CAN4_AGS_Actual_Position, base-type=uint8, implementation-data-type=uint8, transfer-property=PENDING
          signal CAN4_AGS_Actuator_Blocked: start 8, 1 bit, big-endian, i-signal-type=PRIMITIVE, init-value=constant-reference=Init_CAN4_AGS_Actuator_Blocked, base-type=uint8, implementation-data-type=uint8, transfer-property=PENDING
          signal CAN4_AGS_Actuator_Fault: start 9, 1 bit, big-endian, i-signal-type=PRIMITIVE, init-value=constant-reference=Init_CAN4_AGS_Actuator_Fault, base-type=uint8, implementation-data-type=uint8, transfer-property=PENDING
          signal CAN4_AGS_Calibration_Active: start 10, 1 bit, big-endian, i-signal-type=PRIMITIVE, init-value=constant-reference=Init_CAN4_AGS_Calibration_Active, base-type=uint8, implementation-data-type=uint8, transfer-property=PENDING
          signal CAN4_AGS_Calibration_Enabled: start 22, 1 bit, big-endian, i-signal-type=PRIMITIVE, init-value=constant-reference=Init_CAN4_AGS_Calibration_Enabled, base-type=uint8, implementation-data-type=uint8, transfer-property=PENDING
          signal CAN4_AGS_Calibration_Indicated: start 11, 1 bit, big-endian, i-signal-type=PRIMITIVE, init-value=constant-reference=Init_CAN4_AGS_Calibration_Indicated, base-type=uint8, implementation-data-type=uint8, transfer-property=PENDING
          signal CAN4_AGS_Electrical_Error: start 12, 1 bit, big-endian, i-signal-type=PRIMITIVE, init-value=constant-reference=Init_CAN4_AGS_Electrical_Error, base-type=uint8, implementation-data-type=uint8, transfer-property=PENDING
          signal CAN4_AGS_LINResponse_Error: start 23, 1 bit, big-endian, i-signal-type=PRIMITIVE, init-value=constant-reference=Init_CAN4_AGS_LINResponse_Error, base-type=uint8, implementation-data-type=uint8, transfer-property=PENDING
          signal CAN4_AGS_Low_Voltage_Error: start 15, 1 bit, big-endian, i-signal-type=PRIMITIVE, init-value=constant-reference=Init_CAN4_AGS_Low_Voltage_Error, base-type=uint8, implementation-data-type=uint8, transfer-property=PENDING
          signal CAN4_AGS_Position_Request: start 31, 8 bit, big-endian, i-signal-type=PRIMITIVE, init-value=constant-reference=Init_CAN4_AGS_Position_Request, base-type=uint8, implementation-data-type=uint8, transfer-property=PENDING
          signal CAN4_AGS_Sensor_Error: start 13, 1 bit, big-endian, i-signal-type=PRIMITIVE, init-value=constant-reference=Init_CAN4_AGS_Sensor_Error, base-type=uint8, implementation-data-type=uint8, transfer-property=PENDING
          signal CAN4_AGS_Temperature_Error: start 14, 1 bit, big-endian, i-signal-type=PRIMITIVE, init-value=constant-reference=Init_CAN4_AGS_Temperature_Error, base-type=uint8, implementation-data-type=uint8, transfer-property=PENDING
          signal CAN4_BDC_1_MoveEnable: start 156, 1 bit, big-endian, i-signal-type=PRIMITIVE, init-value=constant-reference=Init_CAN4_BDC_1_MoveEnable, base-type=uint8, implementation-data-type=uint8, transfer-property=PENDING
          signal CAN4_BDC_1_ReqMovePos: start 127, 8 bit, big-endian, i-signal-type=PRIMITIVE, init-value=constant-reference=Init_CAN4_BDC_1_ReqMovePos, base-type=uint8, implementation-data-type=uint8, transfer-property=PENDING
          signal CAN4_CCV4_MoveEnable: start 152, 1 bit, big-endian, i-signal-type=PRIMITIVE, init-value=constant-reference=Init_CAN4_CCV4_MoveEnable, base-type=uint8, implementation-data-type=uint8, transfer-property=PENDING
          signal CAN4_CCV4_ReqMovePos: start 153, 1 bit, big-endian, i-signal-type=PRIMITIVE, init-value=constant-reference=Init_CAN4_CCV4_ReqMovePos, base-type=uint8, implementation-data-type=uint8, transfer-property=PENDING
          signal CAN4_ChargeInletLockSta: start 58, 1 bit, big-endian, i-signal-type=PRIMITIVE, init-value=constant-reference=Init_CAN4_ChargeInletLockSta, base-type=uint8, implementation-data-type=uint8, transfer-property=PENDING
          signal CAN4_EWP1_Default_Operation_EWP_Rq: start 154, 1 bit, big-endian, i-signal-type=PRIMITIVE, init-value=constant-reference=Init_CAN4_EWP1_Default_Operation_EWP_Rq, base-type=uint8, implementation-data-type=uint8, transfer-property=PENDING
          signal CAN4_EWP1_RPM_Target_EWP_Rq: start 143, 8 bit, big-endian, i-signal-type=PRIMITIVE, init-value=constant-reference=Init_CAN4_EWP1_RPM_Target_EWP_Rq, base-type=uint8, implementation-data-type=uint8, transfer-property=PENDING
          signal CAN4_EWP2_Default_Operation_EWP_Rq: start 157, 1 bit, big-endian, i-signal-type=PRIMITIVE, init-value=constant-reference=Init_CAN4_EWP2_Default_Operation_EWP_Rq, base-type=uint8, implementation-data-type=uint8, transfer-property=PENDING
          signal CAN4_EWP2_RPM_Target_EWP_Rq: start 119, 8 bit, big-endian, i-signal-type=PRIMITIVE, init-value=constant-reference=Init_CAN4_EWP2_RPM_Target_EWP_Rq, base-type=uint8, implementation-data-type=uint8, transfer-property=PENDING
          signal CAN4_EWP3_Default_Operation_EWP_Rq: start 155, 1 bit, big-endian, i-signal-type=PRIMITIVE, init-value=constant-reference=Init_CAN4_EWP3_Default_Operation_EWP_Rq, base-type=uint8, implementation-data-type=uint8, transfer-property=PENDING
          signal CAN4_EWP3_RPM_Target_EWP_Rq: start 135, 8 bit, big-endian, i-signal-type=PRIMITIVE, init-value=constant-reference=Init_CAN4_EWP3_RPM_Target_EWP_Rq, base-type=uint8, implementation-data-type=uint8, transfer-property=PENDING
          signal CAN4_EXV2_Cmd_Init_Rq: start 146, 3 bit, big-endian, i-signal-type=PRIMITIVE, init-value=constant-reference=Init_CAN4_EXV2_Cmd_Init_Rq, base-type=uint8, implementation-data-type=uint8, transfer-property=PENDING
          signal CAN4_EXV2_Cmd_Move_Enbl: start 159, 1 bit, big-endian, i-signal-type=PRIMITIVE, init-value=constant-reference=Init_CAN4_EXV2_Cmd_Move_Enbl, base-type=uint8, implementation-data-type=uint8, transfer-property=PENDING
          signal CAN4_EXV2_Cmd_Set_Rq: start 87, 16 bit, big-endian, i-signal-type=PRIMITIVE, init-value=constant-reference=Init_CAN4_EXV2_Cmd_Set_Rq, base-type=uint16, implementation-data-type=uint16, transfer-property=PENDING
          signal CAN4_EXV_Cmd_Init_Rq: start 149, 3 bit, big-endian, i-signal-type=PRIMITIVE, init-value=constant-reference=Init_CAN4_EXV_Cmd_Init_Rq, base-type=uint8, implementation-data-type=uint8, transfer-property=PENDING
          signal CAN4_EXV_Cmd_Move_Enbl: start 158, 1 bit, big-endian, i-signal-type=PRIMITIVE, init-value=constant-reference=Init_CAN4_EXV_Cmd_Move_Enbl, base-type=uint8, implementation-data-type=uint8, transfer-property=PENDING
          signal CAN4_EXV_Cmd_Set_Rq: start 103, 16 bit, big-endian, i-signal-type=PRIMITIVE, init-value=constant-reference=Init_CAN4_EXV_Cmd_Set_Rq, base-type=uint16, implementation-data-type=uint16, transfer-property=PENDING
          signal CAN4_FLTurnLampC: start 55, 8 bit, big-endian, i-signal-type=PRIMITIVE, init-value=constant-reference=Init_CAN4_FLTurnLampC, base-type=uint8, implementation-data-type=uint8, transfer-property=TRIGGERED-ON-CHANGE
          signal CAN4_FRTurnLampC: start 47, 8 bit, big-endian, i-signal-type=PRIMITIVE, init-value=constant-reference=Init_CAN4_FRTurnLampC, base-type=uint8, implementation-data-type=uint8, transfer-property=TRIGGERED-ON-CHANGE
          signal CAN4_FWiperAS: start 56, 1 bit, big-endian, i-signal-type=PRIMITIVE, init-value=constant-reference=Init_CAN4_FWiperAS, base-type=uint8, implementation-data-type=uint8, transfer-property=TRIGGERED-ON-CHANGE
          signal CAN4_FWiperProtection: start 57, 1 bit, big-endian, i-signal-type=PRIMITIVE, init-value=constant-reference=Init_CAN4_FWiperProtection, base-type=uint8, implementation-data-type=uint8, transfer-property=TRIGGERED-ON-CHANGE
      frame CAN4_GW_ZoneFR2: id 0x30A, frame-length=32, can-addressing-mode=STANDARD, can-fd-frame-support=true, can-frame-rx-behavior=CAN-FD, can-frame-tx-behavior=CAN-FD
        pdu CAN4_GW_ZoneFR2: length=32, minimum-delay=0.0, transmission-mode-true-timing=cyclic-timing=time-period=0.1, unused-bit-pattern=0
          mapping CAN4_SG_GW_ZoneFR2: i-signal-group=CAN4_SG_GW_ZoneFR2, start-position=0, transfer-property=PENDING
          signal CAN4_BMSPackVol_h6HSC6: start 211, 12 bit, big-endian, i-signal-type=PRIMITIVE, init-value=constant-reference=Init_CAN4_BMSPackVol_h6HSC6, base-type=uint16, implementation-data-type=uint16, transfer-property=PENDING
          signal CAN4_CCM_SpdCmd: start 22, 15 bit, big-endian, i-signal-type=PRIMITIVE, init-value=constant-reference=Init_CAN4_CCM_SpdCmd, base-type=uint16, implementation-data-type=uint16, transfer-property=PENDING
          signal CAN4_COMP_ComLost: start 58, 1 bit, big-endian, i-signal-type=PRIMITIVE, init-value=constant-reference=Init_CAN4_COMP_ComLost, base-type=uint8, implementation-data-type=uint8, transfer-property=PENDING
          signal CAN4_COMP_ConCur: start 103, 16 bit, big-endian, i-signal-type=PRIMITIVE, init-value=constant-reference=Init_CAN4_COMP_ConCur, base-type=uint16, implementation-data-type=uint16, transfer-property=PENDING
          signal CAN4_COMP_ConVolt: start 119, 16 bit, big-endian, i-signal-type=PRIMITIVE, init-value=constant-reference=Init_CAN4_COMP_ConVolt, base-type=uint16, implementation-data-type=uint16, transfer-property=PENDING
          signal CAN4_COMP_CtrlCircFlt: start 68, 1 bit, big-endian, i-signal-type=PRIMITIVE, init-value=constant-reference=Init_CAN4_COMP_CtrlCircFlt, base-type=uint8, implementation-data-type=uint8, transfer-property=PENDING
          signal CAN4_COMP_CurOverProtect: start 71, 1 bit, big-endian, i-signal-type=PRIMITIVE, init-value=constant-reference=Init_CAN4_COMP_CurOverProtect, base-type=uint8, implementation-data-type=uint8, transfer-property=PENDING
          signal CAN4_COMP_CurVaild: start 87, 1 bit, big-endian, i-signal-type=PRIMITIVE, init-value=constant-reference=Init_CAN4_COMP_CurVaild, base-type=uint8, implementation-data-type=uint8, transfer-property=PENDING
          signal CAN4_COMP_IPM_HWFLt: start 57, 1 bit, big-endian, i-signal-type=PRIMITIVE, init-value=constant-reference=Init_CAN4_COMP_IPM_HWFLt, base-type=uint8, implementation-data-type=uint8, transfer-property=PENDING
          signal CAN4_COMP_IPM_TempOverFlt: start 56, 1 bit, big-endian, i-signal-type=PRIMITIVE, init-value=constant-reference=Init_CAN4_COMP_IPM_TempOverFlt, base-type=uint8, implementation-data-type=uint8, transfer-property=PENDING
          signal CAN4_COMP_Init: start 65, 1 bit, big-endian, i-signal-type=PRIMITIVE, init-value=constant-reference=Init_CAN4_COMP_Init, base-type=uint8, implementation-data-type=uint8, transfer-property=PENDING
          signal CAN4_COMP_SpdVaild: start 64, 1 bit, big-endian, i-signal-type=PRIMITIVE, init-value=constant-reference=Init_CAN4_COMP_SpdVaild, base-type=uint8, implementation-data-type=uint8, transfer-property=PENDING
          signal CAN4_COMP_Sta: start 67, 2 bit, big-endian, i-signal-type=PRIMITIVE, init-value=constant-reference=Init_CAN4_COMP_Sta, base-type=uint8, implementation-data-type=uint8, transfer-property=PENDING
          signal CAN4_COMP_StatorSpd: start 85, 14 bit, big-endian, i-signal-type=PRIMITIVE, init-value=constant-reference=Init_CAN4_COMP_StatorSpd, base-type=uint16, implementation-data-type=uint16, transfer-property=PENDING
          signal CAN4_COMP_VoltLessErr: start 69, 1 bit, big-endian, i-signal-type=PRIMITIVE, init-value=constant-reference=Init_CAN4_COMP_VoltLessErr, base-type=uint8, implementation-data-type=uint8, transfer-property=PENDING
          signal CAN4_COMP_VoltOverErr: start 70, 1 bit, big-endian, i-signal-type=PRIMITIVE, init-value=constant-reference=Init_CAN4_COMP_VoltOverErr, base-type=uint8, implementation-data-type=uint8, transfer-property=PENDING
          signal CAN4_COMP_VoltVaild: start 86, 1 bit, big-endian, i-signal-type=PRIMITIVE, init-value=constant-reference=Init_CAN4_COMP_VoltVaild, base-type=uint8, implementation-data-type=uint8, transfer-property=PENDING
          signal CAN4_CompProEN: start 59, 1 bit, big-endian, i-signal-type=PRIMITIVE, init-value=constant-reference=Init_CAN4_CompProEN, base-type=uint8, implementation-data-type=uint8, transfer-property=PENDING
          signal CAN4_EAC_DrvVoltFalt: start 63, 1 bit, big-endian, i-signal-type=PRIMITIVE, init-value=constant-reference=Init_CAN4_EAC_DrvVoltFalt, base-type=uint8, implementation-data-type=uint8, transfer-property=PENDING
          signal CAN4_EAC_MotCrt: start 79, 8 bit, big-endian, i-signal-type=PRIMITIVE, init-value=constant-reference=Init_CAN4_EAC_MotCrt, base-type=uint8, implementation-data-type=uint8, transfer-property=PENDING
          signal CAN4_EAC_MotorLackFalt: start 62, 1 bit, big-endian, i-signal-type=PRIMITIVE, init-value=constant-reference=Init_CAN4_EAC_MotorLackFalt, base-type=uint8, implementation-data-type=uint8, transfer-property=PENDING
          signal CAN4_EAC_OvLoadFalt: start 61, 1 bit, big-endian, i-signal-type=PRIMITIVE, init-value=constant-reference=Init_CAN4_EAC_OvLoadFalt, base-type=uint8, implementation-data-type=uint8, transfer-property=PENDING
          signal CAN4_EAC_Temp: start 39, 8 bit, big-endian, i-signal-type=PRIMITIVE, init-value=constant-reference=Init_CAN4_EAC_Temp, base-type=uint8, implementation-data-type=uint8, transfer-property=PENDING
          signal CAN4_EAC_TempSnsrFalt: start 60, 1 bit, big-endian, i-signal-type=PRIMITIVE, init-value=constant-reference=Init_CAN4_EAC_TempSnsrFalt, base-type=uint8, implementation-data-type=uint8, transfer-property=PENDING
          signal CAN4_PTCActuCrntHSC6: start 161, 10 bit, big-endian, i-signal-type=PRIMITIVE, init-value=constant-reference=Init_CAN4_PTCActuCrntHSC6, base-type=uint16, implementation-data-type=uint16, transfer-property=PENDING
          signal CAN4_PTCActuPWMDutyHSC6: start 7, 8 bit, big-endian, i-signal-type=PRIMITIVE, init-value=constant-reference=Init_CAN4_PTCActuPWMDutyHSC6, base-type=uint8, implementation-data-type=uint8, transfer-property=PENDING
          signal CAN4_PTCActuVolHSC6: start 193, 10 bit, big-endian, i-signal-type=PRIMITIVE, init-value=constant-reference=Init_CAN4_PTCActuVolHSC6, base-type=uint16, implementation-data-type=uint16, transfer-property=PENDING
          signal CAN4_PTCChksmHSC6: start 183, 8 bit, big-endian, i-signal-type=PRIMITIVE, init-value=constant-reference=Init_CAN4_PTCChksmHSC6, base-type=uint8, implementation-data-type=uint8, transfer-property=PENDING
          signal CAN4_PTCFltLvlHSC6: start 199, 4 bit, big-endian, i-signal-type=PRIMITIVE, init-value=constant-reference=Init_CAN4_PTCFltLvlHSC6, base-type=uint8, implementation-data-type=uint8, transfer-property=PENDING
          signal CAN4_PTCHVLckStsHSC6: start 146, 1 bit, big-endian, i-signal-type=PRIMITIVE, init-value=constant-reference=Init_CAN4_PTCHVLckStsHSC6, base-type=uint8, implementation-data-type=uint8, transfer-property=PENDING
          signal CAN4_PTCIGBTOverHeatHSC6: start 145, 1 bit, big-endian, i-signal-type=PRIMITIVE, init-value=constant-reference=Init_CAN4_PTCIGBTOverHeatHSC6, base-type=uint8, implementation-data-type=uint8, transfer-property=PENDING
          signal CAN4_PTCIGBTStsHSC6: start 147, 1 bit, big-endian, i-signal-type=PRIMITIVE, init-value=constant-reference=Init_CAN4_PTCIGBTStsHSC6, base-type=uint8, implementation-data-type=uint8, transfer-property=PENDING
          signal CAN4_PTCIGBTTemHSC6: start 15, 9 bit, big-endian, i-signal-type=PRIMITIVE, init-value=constant-reference=Init_CAN4_PTCIGBTTemHSC6, base-type=uint16, implementation-data-type=uint16, transfer-property=PENDING
          signal CAN4_PTCNTCStsHSC6: start 47, 3 bit, big-endian, i-signal-type=PRIMITIVE, init-value=constant-reference=Init_CAN4_PTCNTCStsHSC6, base-type=uint8, implementation-data-type=uint8, transfer-property=PENDING
          signal CAN4_PTCOtptTemHSC6: start 128, 9 bit, big-endian, i-signal-type=PRIMITIVE, init-value=constant-reference=Init_CAN4_PTCOtptTemHSC6, base-type=uint16, implementation-data-type=uint16, transfer-property=PENDING
          signal CAN4_PTCOverCrntHSC6: start 130, 1 bit, big-endian, i-signal-type=PRIMITIVE, init-value=constant-reference=Init_CAN4_PTCOverCrntHSC6, base-type=uint8, implementation-data-type=uint8, transfer-property=PENDING
          signal CAN4_PTCOverHeatHSC6: start 129, 1 bit, big-endian, i-signal-type=PRIMITIVE, init-value=constant-reference=Init_CAN4_PTCOverHeatHSC6, base-type=uint8, implementation-data-type=uint8, transfer-property=PENDING
          signal CAN4_PTCOverVolHSC6: start 131, 1 bit, big-endian, i-signal-type=PRIMITIVE, init-value=constant-reference=Init_CAN4_PTCOverVolHSC6, base-type=uint8, implementation-data-type=uint8, transfer-property=PENDING
          signal CAN4_PTCPCBTemHSC6: start 144, 9 bit, big-endian, i-signal-type=PRIMITIVE, init-value=constant-reference=Init_CAN4_PTCPCBTemHSC6, base-type=uint16, implementation-data-type=uint16, transfer-property=PENDING
          signal CAN4_PTCRlngCtrHSC6: start 151, 4 bit, big-endian, i-signal-type=PRIMITIVE, init-value=constant-reference=Init_CAN4_PTCRlngCtrHSC6, base-type=uint8, implementation-data-type=uint8, transfer-property=PENDING
          signal CAN4_PTCSecChksmHSC6: start 191, 8 bit, big-endian, i-signal-type=PRIMITIVE, init-value=constant-reference=Init_CAN4_PTCSecChksmHSC6, base-type=uint8, implementation-data-type=uint8, transfer-property=PENDING
          signal CAN4_PTCSecRlngCtrHSC6: start 135, 4 bit, big-endian, i-signal-type=PRIMITIVE, init-value=constant-reference=Init_CAN4_PTCSecRlngCtrHSC6, base-type=uint8, implementation-data-type=uint8, transfer-property=PENDING
          signal CAN4_PTCStsHSC6: start 166, 2 bit, big-endian, i-signal-type=PRIMITIVE, init-value=constant-reference=Init_CAN4_PTCStsHSC6, base-type=uint8, implementation-data-type=uint8, transfer-property=PENDING
          signal CAN4_PTCUnderVolHSC6: start 167, 1 bit, big-endian, i-signal-type=PRIMITIVE, init-value=constant-reference=Init_CAN4_PTCUnderVolHSC6, base-type=uint8, implementation-data-type=uint8, transfer-property=PENDING
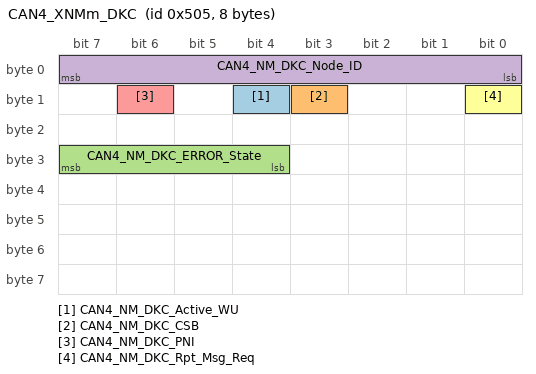
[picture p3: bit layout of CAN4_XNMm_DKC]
      frame CAN4_XNMm_DKC: id 0x505, frame-length=8, can-addressing-mode=STANDARD, can-fd-frame-support=false, can-frame-rx-behavior=CAN-20, can-frame-tx-behavior=CAN-20
        pdu CAN4_XNMm_DKC: length=8, minimum-delay=0.0, transmission-mode-true-timing=cyclic-timing=time-period=0.7, unused-bit-pattern=0
          mapping CAN4_SG_XNMm_DKC: i-signal-group=CAN4_SG_XNMm_DKC, start-position=0, transfer-property=PENDING
          signal CAN4_NM_DKC_Active_WU: start 12, 1 bit, big-endian, i-signal-type=PRIMITIVE, init-value=constant-reference=Init_CAN4_NM_DKC_Active_WU, base-type=uint8, implementation-data-type=uint8, transfer-property=PENDING
          signal CAN4_NM_DKC_CSB: start 11, 1 bit, big-endian, i-signal-type=PRIMITIVE, init-value=constant-reference=Init_CAN4_NM_DKC_CSB, base-type=uint8, implementation-data-type=uint8, transfer-property=PENDING
          signal CAN4_NM_DKC_ERROR_State: start 31, 4 bit, big-endian, i-signal-type=PRIMITIVE, init-value=constant-reference=Init_CAN4_NM_DKC_ERROR_State, base-type=uint8, implementation-data-type=uint8, transfer-property=PENDING
          signal CAN4_NM_DKC_Node_ID: start 7, 8 bit, big-endian, i-signal-type=PRIMITIVE, init-value=constant-reference=Init_CAN4_NM_DKC_Node_ID, base-type=uint8, implementation-data-type=uint8, transfer-property=PENDING
          signal CAN4_NM_DKC_PNI: start 14, 1 bit, big-endian, i-signal-type=PRIMITIVE, init-value=constant-reference=Init_CAN4_NM_DKC_PNI, base-type=uint8, implementation-data-type=uint8, transfer-property=PENDING
          signal CAN4_NM_DKC_Rpt_Msg_Req: start 8, 1 bit, big-endian, i-signal-type=PRIMITIVE, init-value=constant-reference=Init_CAN4_NM_DKC_Rpt_Msg_Req, base-type=uint8, implementation-data-type=uint8, transfer-property=PENDING
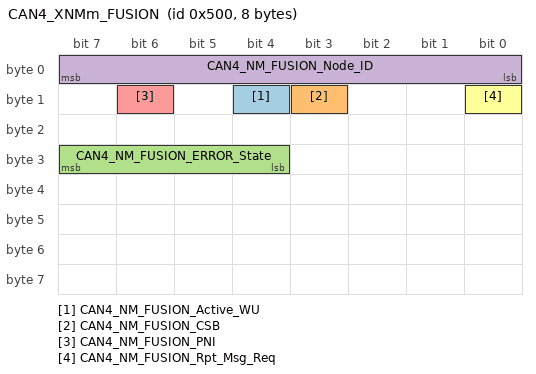
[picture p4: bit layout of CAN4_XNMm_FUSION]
      frame CAN4_XNMm_FUSION: id 0x500, frame-length=8, can-addressing-mode=STANDARD, can-fd-frame-support=false, can-frame-rx-behavior=CAN-20, can-frame-tx-behavior=CAN-20
        pdu CAN4_XNMm_FUSION: length=8, minimum-delay=0.0, transmission-mode-true-timing=cyclic-timing=time-period=0.7, unused-bit-pattern=0
          mapping CAN4_SG_XNMm_FUSION: i-signal-group=CAN4_SG_XNMm_FUSION, start-position=0, transfer-property=PENDING
          signal CAN4_NM_FUSION_Active_WU: start 12, 1 bit, big-endian, i-signal-type=PRIMITIVE, init-value=constant-reference=Init_CAN4_NM_FUSION_Active_WU, base-type=uint8, implementation-data-type=uint8, transfer-property=PENDING
          signal CAN4_NM_FUSION_CSB: start 11, 1 bit, big-endian, i-signal-type=PRIMITIVE, init-value=constant-reference=Init_CAN4_NM_FUSION_CSB, base-type=uint8, implementation-data-type=uint8, transfer-property=PENDING
          signal CAN4_NM_FUSION_ERROR_State: start 31, 4 bit, big-endian, i-signal-type=PRIMITIVE, init-value=constant-reference=Init_CAN4_NM_FUSION_ERROR_State, base-type=uint8, implementation-data-type=uint8, transfer-property=PENDING
          signal CAN4_NM_FUSION_Node_ID: start 7, 8 bit, big-endian, i-signal-type=PRIMITIVE, init-value=constant-reference=Init_CAN4_NM_FUSION_Node_ID, base-type=uint8, implementation-data-type=uint8, transfer-property=PENDING
          signal CAN4_NM_FUSION_PNI: start 14, 1 bit, big-endian, i-signal-type=PRIMITIVE, init-value=constant-reference=Init_CAN4_NM_FUSION_PNI, base-type=uint8, implementation-data-type=uint8, transfer-property=PENDING
          signal CAN4_NM_FUSION_Rpt_Msg_Req: start 8, 1 bit, big-endian, i-signal-type=PRIMITIVE, init-value=constant-reference=Init_CAN4_NM_FUSION_Rpt_Msg_Req, base-type=uint8, implementation-data-type=uint8, transfer-property=PENDING
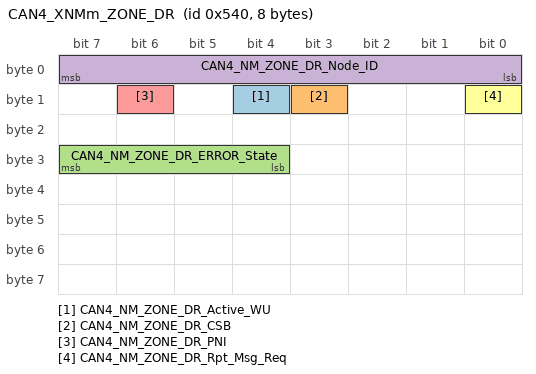
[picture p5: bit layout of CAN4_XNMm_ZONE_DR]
      frame CAN4_XNMm_ZONE_DR: id 0x540, frame-length=8, can-addressing-mode=STANDARD, can-fd-frame-support=false, can-frame-rx-behavior=CAN-20, can-frame-tx-behavior=CAN-20
        pdu CAN4_XNMm_ZONE_DR: length=8, minimum-delay=0.0, transmission-mode-true-timing=cyclic-timing=time-period=0.7, unused-bit-pattern=0
          mapping CAN4_SG_XNMm_ZONE_DR: i-signal-group=CAN4_SG_XNMm_ZONE_DR, start-position=0, transfer-property=PENDING
          signal CAN4_NM_ZONE_DR_Active_WU: start 12, 1 bit, big-endian, i-signal-type=PRIMITIVE, init-value=constant-reference=Init_CAN4_NM_ZONE_DR_Active_WU, base-type=uint8, implementation-data-type=uint8, transfer-property=PENDING
          signal CAN4_NM_ZONE_DR_CSB: start 11, 1 bit, big-endian, i-signal-type=PRIMITIVE, init-value=constant-reference=Init_CAN4_NM_ZONE_DR_CSB, base-type=uint8, implementation-data-type=uint8, transfer-property=PENDING
          signal CAN4_NM_ZONE_DR_ERROR_State: start 31, 4 bit, big-endian, i-signal-type=PRIMITIVE, init-value=constant-reference=Init_CAN4_NM_ZONE_DR_ERROR_State, base-type=uint8, implementation-data-type=uint8, transfer-property=PENDING
          signal CAN4_NM_ZONE_DR_Node_ID: start 7, 8 bit, big-endian, i-signal-type=PRIMITIVE, init-value=constant-reference=Init_CAN4_NM_ZONE_DR_Node_ID, base-type=uint8, implementation-data-type=uint8, transfer-property=PENDING
          signal CAN4_NM_ZONE_DR_PNI: start 14, 1 bit, big-endian, i-signal-type=PRIMITIVE, init-value=constant-reference=Init_CAN4_NM_ZONE_DR_PNI, base-type=uint8, implementation-data-type=uint8, transfer-property=PENDING
          signal CAN4_NM_ZONE_DR_Rpt_Msg_Req: start 8, 1 bit, big-endian, i-signal-type=PRIMITIVE, init-value=constant-reference=Init_CAN4_NM_ZONE_DR_Rpt_Msg_Req, base-type=uint8, implementation-data-type=uint8, transfer-property=PENDING
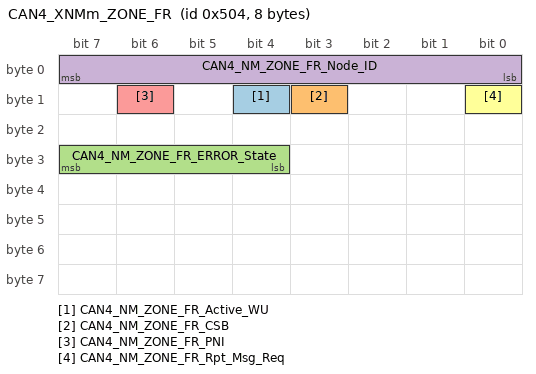
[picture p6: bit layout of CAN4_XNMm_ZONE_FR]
      frame CAN4_XNMm_ZONE_FR: id 0x504, frame-length=8, can-addressing-mode=STANDARD, can-fd-frame-support=false, can-frame-rx-behavior=CAN-20, can-frame-tx-behavior=CAN-20
        pdu CAN4_XNMm_ZONE_FR: length=8, minimum-delay=0.0, transmission-mode-true-timing=cyclic-timing=time-period=0.7, unused-bit-pattern=0
          mapping CAN4_SG_XNMm_ZONE_FR: i-signal-group=CAN4_SG_XNMm_ZONE_FR, start-position=0, transfer-property=PENDING
          signal CAN4_NM_ZONE_FR_Active_WU: start 12, 1 bit, big-endian, i-signal-type=PRIMITIVE, init-value=constant-reference=Init_CAN4_NM_ZONE_FR_Active_WU, base-type=uint8, implementation-data-type=uint8, transfer-property=PENDING
          signal CAN4_NM_ZONE_FR_CSB: start 11, 1 bit, big-endian, i-signal-type=PRIMITIVE, init-value=constant-reference=Init_CAN4_NM_ZONE_FR_CSB, base-type=uint8, implementation-data-type=uint8, transfer-property=PENDING
          signal CAN4_NM_ZONE_FR_ERROR_State: start 31, 4 bit, big-endian, i-signal-type=PRIMITIVE, init-value=constant-reference=Init_CAN4_NM_ZONE_FR_ERROR_State, base-type=uint8, implementation-data-type=uint8, transfer-property=PENDING
          signal CAN4_NM_ZONE_FR_Node_ID: start 7, 8 bit, big-endian, i-signal-type=PRIMITIVE, init-value=constant-reference=Init_CAN4_NM_ZONE_FR_Node_ID, base-type=uint8, implementation-data-type=uint8, transfer-property=PENDING
          signal CAN4_NM_ZONE_FR_PNI: start 14, 1 bit, big-endian, i-signal-type=PRIMITIVE, init-value=constant-reference=Init_CAN4_NM_ZONE_FR_PNI, base-type=uint8, implementation-data-type=uint8, transfer-property=PENDING
          signal CAN4_NM_ZONE_FR_Rpt_Msg_Req: start 8, 1 bit, big-endian, i-signal-type=PRIMITIVE, init-value=constant-reference=Init_CAN4_NM_ZONE_FR_Rpt_Msg_Req, base-type=uint8, implementation-data-type=uint8, transfer-property=PENDING
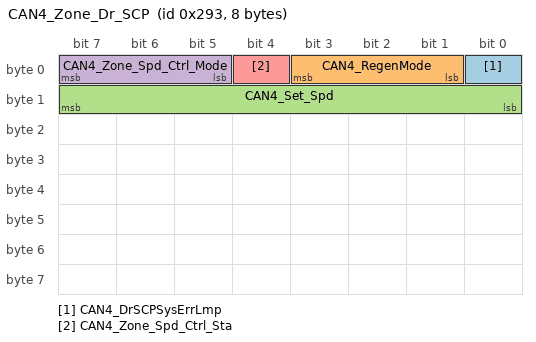
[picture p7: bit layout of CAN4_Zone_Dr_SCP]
      frame CAN4_Zone_Dr_SCP: id 0x293, frame-length=8, can-addressing-mode=STANDARD, can-fd-frame-support=true, can-frame-rx-behavior=CAN-FD, can-frame-tx-behavior=CAN-FD
        pdu CAN4_Zone_Dr_SCP: length=8, minimum-delay=0.0, transmission-mode-true-timing={cyclic-timing=time-period=0.1, event-controlled-timing={number-of-repetitions=0, repetition-period=0.01}}, unused-bit-pattern=0
          mapping CAN4_SG_Zone_Dr_SCP: i-signal-group=CAN4_SG_Zone_Dr_SCP, start-position=0, transfer-property=TRIGGERED-ON-CHANGE
          signal CAN4_DrSCPSysErrLmp: start 0, 1 bit, big-endian, i-signal-type=PRIMITIVE, init-value=constant-reference=Init_CAN4_DrSCPSysErrLmp, base-type=uint8, implementation-data-type=uint8, transfer-property=TRIGGERED-ON-CHANGE
          signal CAN4_RegenMode: start 3, 3 bit, big-endian, i-signal-type=PRIMITIVE, init-value=constant-reference=Init_CAN4_RegenMode, base-type=uint8, implementation-data-type=uint8, transfer-property=TRIGGERED-ON-CHANGE
          signal CAN4_Set_Spd: start 15, 8 bit, big-endian, i-signal-type=PRIMITIVE, init-value=constant-reference=Init_CAN4_Set_Spd, base-type=uint8, implementation-data-type=uint8, transfer-property=TRIGGERED-ON-CHANGE
          signal CAN4_Zone_Spd_Ctrl_Mode: start 7, 3 bit, big-endian, i-signal-type=PRIMITIVE, init-value=constant-reference=Init_CAN4_Zone_Spd_Ctrl_Mode, base-type=uint8, implementation-data-type=uint8, transfer-property=TRIGGERED-ON-CHANGE
          signal CAN4_Zone_Spd_Ctrl_Sta: start 4, 1 bit, big-endian, i-signal-type=PRIMITIVE, init-value=constant-reference=Init_CAN4_Zone_Spd_Ctrl_Sta, base-type=uint8, implementation-data-type=uint8, transfer-property=TRIGGERED-ON-CHANGE
      frame CAN4_Zone_Dr_THCM: id 0x225, frame-length=16, can-addressing-mode=STANDARD, can-fd-frame-support=true, can-frame-rx-behavior=CAN-FD, can-frame-tx-behavior=CAN-FD
        pdu CAN4_Zone_Dr_THCM: length=16, minimum-delay=0.0, transmission-mode-true-timing={cyclic-timing=time-period=0.1, event-controlled-timing={number-of-repetitions=0, repetition-period=0.01}}, unused-bit-pattern=0
          mapping CAN4_SG_Zone_Dr_THCM: i-signal-group=CAN4_SG_Zone_Dr_THCM, start-position=0, transfer-property=TRIGGERED-ON-CHANGE
          signal CAN4_APTC_Err: start 111, 2 bit, big-endian, i-signal-type=PRIMITIVE, init-value=constant-reference=Init_CAN4_APTC_Err, base-type=uint8, implementation-data-type=uint8, transfer-property=TRIGGERED-ON-CHANGE
          signal CAN4_Blower_Err: start 109, 2 bit, big-endian, i-signal-type=PRIMITIVE, init-value=constant-reference=Init_CAN4_Blower_Err, base-type=uint8, implementation-data-type=uint8, transfer-property=TRIGGERED-ON-CHANGE
          signal CAN4_Blower_FB: start 67, 4 bit, big-endian, i-signal-type=PRIMITIVE, init-value=constant-reference=Init_CAN4_Blower_FB, base-type=uint8, implementation-data-type=uint8, transfer-property=PENDING
          signal CAN4_SolarL: start 95, 8 bit, big-endian, i-signal-type=PRIMITIVE, init-value=constant-reference=Init_CAN4_SolarL, base-type=uint8, implementation-data-type=uint8, transfer-property=PENDING
          signal CAN4_SolarL_Err: start 121, 2 bit, big-endian, i-signal-type=PRIMITIVE, init-value=constant-reference=Init_CAN4_SolarL_Err, base-type=uint8, implementation-data-type=uint8, transfer-property=TRIGGERED-ON-CHANGE
          signal CAN4_SolarR: start 87, 8 bit, big-endian, i-signal-type=PRIMITIVE, init-value=constant-reference=Init_CAN4_SolarR, base-type=uint8, implementation-data-type=uint8, transfer-property=PENDING
          signal CAN4_SolarR_Err: start 123, 2 bit, big-endian, i-signal-type=PRIMITIVE, init-value=constant-reference=Init_CAN4_SolarR_Err, base-type=uint8, implementation-data-type=uint8, transfer-property=TRIGGERED-ON-CHANGE
          signal CAN4_T_Face_L: start 55, 8 bit, big-endian, i-signal-type=PRIMITIVE, init-value=constant-reference=Init_CAN4_T_Face_L, base-type=uint8, implementation-data-type=uint8, transfer-property=PENDING
          signal CAN4_T_Face_L_Err: start 113, 2 bit, big-endian, i-signal-type=PRIMITIVE, init-value=constant-reference=Init_CAN4_T_Face_L_Err, base-type=uint8, implementation-data-type=uint8, transfer-property=TRIGGERED-ON-CHANGE
          signal CAN4_T_Face_R: start 47, 8 bit, big-endian, i-signal-type=PRIMITIVE, init-value=constant-reference=Init_CAN4_T_Face_R, base-type=uint8, implementation-data-type=uint8, transfer-property=PENDING
          signal CAN4_T_Face_R_Err: start 117, 2 bit, big-endian, i-signal-type=PRIMITIVE, init-value=constant-reference=Init_CAN4_T_Face_R_Err, base-type=uint8, implementation-data-type=uint8, transfer-property=TRIGGERED-ON-CHANGE
          signal CAN4_T_Face_Rr: start 31, 8 bit, big-endian, i-signal-type=PRIMITIVE, init-value=constant-reference=Init_CAN4_T_Face_Rr, base-type=uint8, implementation-data-type=uint8, transfer-property=PENDING
          signal CAN4_T_Face_Rr_Err: start 105, 2 bit, big-endian, i-signal-type=PRIMITIVE, init-value=constant-reference=Init_CAN4_T_Face_Rr_Err, base-type=uint8, implementation-data-type=uint8, transfer-property=TRIGGERED-ON-CHANGE
          signal CAN4_T_Foot_L: start 39, 8 bit, big-endian, i-signal-type=PRIMITIVE, init-value=constant-reference=Init_CAN4_T_Foot_L, base-type=uint8, implementation-data-type=uint8, transfer-property=PENDING
          signal CAN4_T_Foot_L_Err: start 115, 2 bit, big-endian, i-signal-type=PRIMITIVE, init-value=constant-reference=Init_CAN4_T_Foot_L_Err, base-type=uint8, implementation-data-type=uint8, transfer-property=TRIGGERED-ON-CHANGE
          signal CAN4_T_Foot_R: start 15, 8 bit, big-endian, i-signal-type=PRIMITIVE, init-value=constant-reference=Init_CAN4_T_Foot_R, base-type=uint8, implementation-data-type=uint8, transfer-property=PENDING
          signal CAN4_T_Foot_R_Err: start 119, 2 bit, big-endian, i-signal-type=PRIMITIVE, init-value=constant-reference=Init_CAN4_T_Foot_R_Err, base-type=uint8, implementation-data-type=uint8, transfer-property=TRIGGERED-ON-CHANGE
          signal CAN4_T_Foot_Rr: start 23, 8 bit, big-endian, i-signal-type=PRIMITIVE, init-value=constant-reference=Init_CAN4_T_Foot_Rr, base-type=uint8, implementation-data-type=uint8, transfer-property=PENDING
          signal CAN4_T_Foot_Rr_Err: start 107, 2 bit, big-endian, i-signal-type=PRIMITIVE, init-value=constant-reference=Init_CAN4_T_Foot_Rr_Err, base-type=uint8, implementation-data-type=uint8, transfer-property=TRIGGERED-ON-CHANGE
          signal CAN4_Tevap: start 63, 8 bit, big-endian, i-signal-type=PRIMITIVE, init-value=constant-reference=Init_CAN4_Tevap, base-type=uint8, implementation-data-type=uint8, transfer-property=PENDING
          signal CAN4_Tevap_Err: start 125, 2 bit, big-endian, i-signal-type=PRIMITIVE, init-value=constant-reference=Init_CAN4_Tevap_Err, base-type=uint8, implementation-data-type=uint8, transfer-property=TRIGGERED-ON-CHANGE
          signal CAN4_Tincar: start 79, 8 bit, big-endian, i-signal-type=PRIMITIVE, init-value=constant-reference=Init_CAN4_Tincar, base-type=uint8, implementation-data-type=uint8, transfer-property=PENDING
          signal CAN4_Tincar_Err: start 127, 2 bit, big-endian, i-signal-type=PRIMITIVE, init-value=constant-reference=Init_CAN4_Tincar_Err, base-type=uint8, implementation-data-type=uint8, transfer-property=TRIGGERED-ON-CHANGE
          signal CAN4_ZDR_THCM_IntakeFail_Sta: start 7, 2 bit, big-endian, i-signal-type=PRIMITIVE, init-value=constant-reference=Init_CAN4_ZDR_THCM_IntakeFail_Sta, base-type=uint8, implementation-data-type=uint8, transfer-property=TRIGGERED-ON-CHANGE
          signal CAN4_ZDR_THCM_LINACT1_Sta: start 3, 2 bit, big-endian, i-signal-type=PRIMITIVE, init-value=constant-reference=Init_CAN4_ZDR_THCM_LINACT1_Sta, base-type=uint8, implementation-data-type=uint8, transfer-property=TRIGGERED-ON-CHANGE
          signal CAN4_ZDR_THCM_LINACT2_Sta: start 1, 2 bit, big-endian, i-signal-type=PRIMITIVE, init-value=constant-reference=Init_CAN4_ZDR_THCM_LINACT2_Sta, base-type=uint8, implementation-data-type=uint8, transfer-property=TRIGGERED-ON-CHANGE
          signal CAN4_ZDR_THCM_LINACT3_Sta: start 71, 2 bit, big-endian, i-signal-type=PRIMITIVE, init-value=constant-reference=Init_CAN4_ZDR_THCM_LINACT3_Sta, base-type=uint8, implementation-data-type=uint8, transfer-property=TRIGGERED-ON-CHANGE
          signal CAN4_ZDR_THCM_LINACT4_Sta: start 69, 2 bit, big-endian, i-signal-type=PRIMITIVE, init-value=constant-reference=Init_CAN4_ZDR_THCM_LINACT4_Sta, base-type=uint8, implementation-data-type=uint8, transfer-property=TRIGGERED-ON-CHANGE
          signal CAN4_ZDR_THCM_LINACT5_Sta: start 103, 2 bit, big-endian, i-signal-type=PRIMITIVE, init-value=constant-reference=Init_CAN4_ZDR_THCM_LINACT5_Sta, base-type=uint8, implementation-data-type=uint8, transfer-property=TRIGGERED-ON-CHANGE
          signal CAN4_ZDR_THCM_ModeFail_Sta: start 5, 2 bit, big-endian, i-signal-type=PRIMITIVE, init-value=constant-reference=Init_CAN4_ZDR_THCM_ModeFail_Sta, base-type=uint8, implementation-data-type=uint8, transfer-property=TRIGGERED-ON-CHANGE
      frame CAN4_Zone_Dr_VCU: id 0x1F1, frame-length=20, can-addressing-mode=STANDARD, can-fd-frame-support=true, can-frame-rx-behavior=CAN-FD, can-frame-tx-behavior=CAN-FD
        pdu CAN4_Zone_Dr_VCU: length=20, minimum-delay=0.0, transmission-mode-true-timing={cyclic-timing=time-period=0.02, event-controlled-timing={number-of-repetitions=0, repetition-period=0.005}}, unused-bit-pattern=0
          mapping CAN4_SG_Zone_Dr_VCU: i-signal-group=CAN4_SG_Zone_Dr_VCU, start-position=0, transfer-property=TRIGGERED-ON-CHANGE
          signal CAN4_DrAPWLINErr: start 6, 1 bit, big-endian, i-signal-type=PRIMITIVE, init-value=constant-reference=Init_CAN4_DrAPWLINErr, base-type=uint8, implementation-data-type=uint8, transfer-property=TRIGGERED-ON-CHANGE
          signal CAN4_DrAPWStaErr: start 7, 1 bit, big-endian, i-signal-type=PRIMITIVE, init-value=constant-reference=Init_CAN4_DrAPWStaErr, base-type=uint8, implementation-data-type=uint8, transfer-property=TRIGGERED-ON-CHANGE
          signal CAN4_DrAuBoxPwrN1Curr: start 47, 8 bit, big-endian, i-signal-type=PRIMITIVE, init-value=constant-reference=Init_CAN4_DrAuBoxPwrN1Curr, base-type=uint8, implementation-data-type=uint8, transfer-property=PENDING
          signal CAN4_DrAuBoxPwrN2Curr: start 39, 8 bit, big-endian, i-signal-type=PRIMITIVE, init-value=constant-reference=Init_CAN4_DrAuBoxPwrN2Curr, base-type=uint8, implementation-data-type=uint8, transfer-property=PENDING
          signal CAN4_DrColumnSWFault: start 17, 2 bit, big-endian, i-signal-type=PRIMITIVE, init-value=constant-reference=Init_CAN4_DrColumnSWFault, base-type=uint8, implementation-data-type=uint8, transfer-property=PENDING
          signal CAN4_DrCtrlBDVolt: start 75, 12 bit, big-endian, i-signal-type=PRIMITIVE, init-value=constant-reference=Init_CAN4_DrCtrlBDVolt, base-type=uint16, implementation-data-type=uint16, transfer-property=PENDING
          signal CAN4_DrCtrlTemp: start 95, 16 bit, big-endian, i-signal-type=PRIMITIVE, init-value=constant-reference=Init_CAN4_DrCtrlTemp, base-type=uint16, implementation-data-type=uint16, transfer-property=PENDING
          signal CAN4_DrEOBDFault: start 9, 2 bit, big-endian, i-signal-type=PRIMITIVE, init-value=constant-reference=Init_CAN4_DrEOBDFault, base-type=uint8, implementation-data-type=uint8, transfer-property=PENDING
          signal CAN4_DrIVIFault: start 11, 2 bit, big-endian, i-signal-type=PRIMITIVE, init-value=constant-reference=Init_CAN4_DrIVIFault, base-type=uint8, implementation-data-type=uint8, transfer-property=PENDING
          signal CAN4_DrInfoErrSta: start 12, 1 bit, big-endian, i-signal-type=PRIMITIVE, init-value=constant-reference=Init_CAN4_DrInfoErrSta, base-type=uint8, implementation-data-type=uint8, transfer-property=TRIGGERED-ON-CHANGE
          signal CAN4_DrInfoFault: start 23, 2 bit, big-endian, i-signal-type=PRIMITIVE, init-value=constant-reference=Init_CAN4_DrInfoFault, base-type=uint8, implementation-data-type=uint8, transfer-property=PENDING
          signal CAN4_DrONA1ErrSta: start 5, 1 bit, big-endian, i-signal-type=PRIMITIVE, init-value=constant-reference=Init_CAN4_DrONA1ErrSta, base-type=uint8, implementation-data-type=uint8, transfer-property=TRIGGERED-ON-CHANGE
          signal CAN4_DrPMMLVOutPErrLmp: start 14, 1 bit, big-endian, i-signal-type=PRIMITIVE, init-value=constant-reference=Init_CAN4_DrPMMLVOutPErrLmp, base-type=uint8, implementation-data-type=uint8, transfer-property=TRIGGERED-ON-CHANGE
          signal CAN4_DrPMMLimpHomeActReq: start 13, 1 bit, big-endian, i-signal-type=PRIMITIVE, init-value=constant-reference=Init_CAN4_DrPMMLimpHomeActReq, base-type=uint8, implementation-data-type=uint8, transfer-property=TRIGGERED-ON-CHANGE
          signal CAN4_DrPMMSysErrLmp: start 15, 1 bit, big-endian, i-signal-type=PRIMITIVE, init-value=constant-reference=Init_CAN4_DrPMMSysErrLmp, base-type=uint8, implementation-data-type=uint8, transfer-property=TRIGGERED-ON-CHANGE
          signal CAN4_DrPowerTemp1: start 111, 16 bit, big-endian, i-signal-type=PRIMITIVE, init-value=constant-reference=Init_CAN4_DrPowerTemp1, base-type=uint16, implementation-data-type=uint16, transfer-property=PENDING
          signal CAN4_DrPowerTemp2: start 127, 16 bit, big-endian, i-signal-type=PRIMITIVE, init-value=constant-reference=Init_CAN4_DrPowerTemp2, base-type=uint16, implementation-data-type=uint16, transfer-property=PENDING
          signal CAN4_DrPwrInformationSta: start 79, 1 bit, big-endian, i-signal-type=PRIMITIVE, init-value=constant-reference=Init_CAN4_DrPwrInformationSta, base-type=uint8, implementation-data-type=uint8, transfer-property=PENDING
          signal CAN4_DrPwrONA1Curr: start 71, 8 bit, big-endian, i-signal-type=PRIMITIVE, init-value=constant-reference=Init_CAN4_DrPwrONA1Curr, base-type=uint8, implementation-data-type=uint8, transfer-property=PENDING
          signal CAN4_DrPwrONA2Curr: start 63, 8 bit, big-endian, i-signal-type=PRIMITIVE, init-value=constant-reference=Init_CAN4_DrPwrONA2Curr, base-type=uint8, implementation-data-type=uint8, transfer-property=PENDING
          signal CAN4_DrPwrSta: start 78, 3 bit, big-endian, i-signal-type=PRIMITIVE, init-value=constant-reference=Init_CAN4_DrPwrSta, base-type=uint8, implementation-data-type=uint8, transfer-property=PENDING
          signal CAN4_DrPwrStdbyACurr: start 55, 8 bit, big-endian, i-signal-type=PRIMITIVE, init-value=constant-reference=Init_CAN4_DrPwrStdbyACurr, base-type=uint8, implementation-data-type=uint8, transfer-property=PENDING
          signal CAN4_DrPwrWinErrSta: start 3, 1 bit, big-endian, i-signal-type=PRIMITIVE, init-value=constant-reference=Init_CAN4_DrPwrWinErrSta, base-type=uint8, implementation-data-type=uint8, transfer-property=TRIGGERED-ON-CHANGE
          signal CAN4_DrPwrWindowECUFault: start 21, 2 bit, big-endian, i-signal-type=PRIMITIVE, init-value=constant-reference=Init_CAN4_DrPwrWindowECUFault, base-type=uint8, implementation-data-type=uint8, transfer-property=PENDING
          signal CAN4_DrStdAErrSta: start 4, 1 bit, big-endian, i-signal-type=PRIMITIVE, init-value=constant-reference=Init_CAN4_DrStdAErrSta, base-type=uint8, implementation-data-type=uint8, transfer-property=TRIGGERED-ON-CHANGE
          signal CAN4_DrTHCMFault: start 19, 2 bit, big-endian, i-signal-type=PRIMITIVE, init-value=constant-reference=Init_CAN4_DrTHCMFault, base-type=uint8, implementation-data-type=uint8, transfer-property=PENDING
          signal CAN4_ZDR_SYS_APMRetryCnt_Sta: start 31, 8 bit, big-endian, i-signal-type=PRIMITIVE, init-value=constant-reference=Init_CAN4_ZDR_SYS_APMRetryCnt_Sta, base-type=uint8, implementation-data-type=uint8, transfer-property=TRIGGERED-ON-CHANGE
          signal CAN4_ZDR_SYS_BSWSleepReq_Sta: start 150, 1 bit, big-endian, i-signal-type=PRIMITIVE, init-value=constant-reference=Init_CAN4_ZDR_SYS_BSWSleepReq_Sta, base-type=uint8, implementation-data-type=uint8, transfer-property=TRIGGERED-ON-CHANGE
          signal CAN4_ZDR_SYS_CSWRetryCnt_Sta: start 143, 8 bit, big-endian, i-signal-type=PRIMITIVE, init-value=constant-reference=Init_CAN4_ZDR_SYS_CSWRetryCnt_Sta, base-type=uint8, implementation-data-type=uint8, transfer-property=TRIGGERED-ON-CHANGE
          signal CAN4_ZDR_VCU_HWReset_Sta: start 148, 5 bit, big-endian, i-signal-type=PRIMITIVE, init-value=constant-reference=Init_CAN4_ZDR_VCU_HWReset_Sta, base-type=uint8, implementation-data-type=uint8, transfer-property=TRIGGERED-ON-CHANGE
          signal CAN4_ZDR_VCU_PwrSupply_Sta: start 149, 1 bit, big-endian, i-signal-type=PRIMITIVE, init-value=constant-reference=Init_CAN4_ZDR_VCU_PwrSupply_Sta, base-type=uint8, implementation-data-type=uint8, transfer-property=TRIGGERED-ON-CHANGE
          signal CAN4_ZoneDrMalfunLevel: start 2, 3 bit, big-endian, i-signal-type=PRIMITIVE, init-value=constant-reference=Init_CAN4_ZoneDrMalfunLevel, base-type=uint8, implementation-data-type=uint8, transfer-property=TRIGGERED-ON-CHANGE
      frame CAN4_Zone_Fr_THCM: id 0x22A, frame-length=24, can-addressing-mode=STANDARD, can-fd-frame-support=true, can-frame-rx-behavior=CAN-FD, can-frame-tx-behavior=CAN-FD
        pdu CAN4_Zone_Fr_THCM: length=24, minimum-delay=0.0, transmission-mode-true-timing={cyclic-timing=time-period=0.1, event-controlled-timing={number-of-repetitions=0, repetition-period=0.01}}, unused-bit-pattern=0
          mapping CAN4_SG_Zone_Fr_THCM: i-signal-group=CAN4_SG_Zone_Fr_THCM, start-position=0, transfer-property=TRIGGERED-ON-CHANGE
          signal CAN4_AGS_Err: start 159, 2 bit, big-endian, i-signal-type=PRIMITIVE, init-value=constant-reference=Init_CAN4_AGS_Err, base-type=uint8, implementation-data-type=uint8, transfer-property=TRIGGERED-ON-CHANGE
          signal CAN4_Bat_In_Temp: start 111, 8 bit, big-endian, i-signal-type=PRIMITIVE, init-value=constant-reference=Init_CAN4_Bat_In_Temp, base-type=uint8, implementation-data-type=uint8, transfer-property=PENDING
          signal CAN4_Bat_In_Temp_Err: start 187, 2 bit, big-endian, i-signal-type=PRIMITIVE, init-value=constant-reference=Init_CAN4_Bat_In_Temp_Err, base-type=uint8, implementation-data-type=uint8, transfer-property=TRIGGERED-ON-CHANGE
          signal CAN4_Bat_Out_Temp: start 103, 8 bit, big-endian, i-signal-type=PRIMITIVE, init-value=constant-reference=Init_CAN4_Bat_Out_Temp, base-type=uint8, implementation-data-type=uint8, transfer-property=PENDING
          signal CAN4_Bat_Out_Temp_Err: start 191, 2 bit, big-endian, i-signal-type=PRIMITIVE, init-value=constant-reference=Init_CAN4_Bat_Out_Temp_Err, base-type=uint8, implementation-data-type=uint8, transfer-property=TRIGGERED-ON-CHANGE
          signal CAN4_COMP_Err: start 165, 2 bit, big-endian, i-signal-type=PRIMITIVE, init-value=constant-reference=Init_CAN4_COMP_Err, base-type=uint8, implementation-data-type=uint8, transfer-property=TRIGGERED-ON-CHANGE
          signal CAN4_EACProtectEnable: start 15, 2 bit, big-endian, i-signal-type=PRIMITIVE, init-value=constant-reference=Init_CAN4_EACProtectEnable, base-type=uint8, implementation-data-type=uint8, transfer-property=TRIGGERED-ON-CHANGE
          signal CAN4_EWP1_Err: start 147, 2 bit, big-endian, i-signal-type=PRIMITIVE, init-value=constant-reference=Init_CAN4_EWP1_Err, base-type=uint8, implementation-data-type=uint8, transfer-property=TRIGGERED-ON-CHANGE
          signal CAN4_EWP2_Err: start 149, 2 bit, big-endian, i-signal-type=PRIMITIVE, init-value=constant-reference=Init_CAN4_EWP2_Err, base-type=uint8, implementation-data-type=uint8, transfer-property=TRIGGERED-ON-CHANGE
          signal CAN4_EWP3_Err: start 151, 2 bit, big-endian, i-signal-type=PRIMITIVE, init-value=constant-reference=Init_CAN4_EWP3_Err, base-type=uint8, implementation-data-type=uint8, transfer-property=TRIGGERED-ON-CHANGE
          signal CAN4_EXV1_Err: start 153, 2 bit, big-endian, i-signal-type=PRIMITIVE, init-value=constant-reference=Init_CAN4_EXV1_Err, base-type=uint8, implementation-data-type=uint8, transfer-property=TRIGGERED-ON-CHANGE
          signal CAN4_EXV2_Err: start 155, 2 bit, big-endian, i-signal-type=PRIMITIVE, init-value=constant-reference=Init_CAN4_EXV2_Err, base-type=uint8, implementation-data-type=uint8, transfer-property=TRIGGERED-ON-CHANGE
          signal CAN4_FWV_Err: start 139, 2 bit, big-endian, i-signal-type=PRIMITIVE, init-value=constant-reference=Init_CAN4_FWV_Err, base-type=uint8, implementation-data-type=uint8, transfer-property=TRIGGERED-ON-CHANGE
          signal CAN4_Fan_Err: start 157, 2 bit, big-endian, i-signal-type=PRIMITIVE, init-value=constant-reference=Init_CAN4_Fan_Err, base-type=uint8, implementation-data-type=uint8, transfer-property=TRIGGERED-ON-CHANGE
          signal CAN4_Motor_In_Temp: start 127, 8 bit, big-endian, i-signal-type=PRIMITIVE, init-value=constant-reference=Init_CAN4_Motor_In_Temp, base-type=uint8, implementation-data-type=uint8, transfer-property=PENDING
          signal CAN4_Motor_In_Temp_Err: start 189, 2 bit, big-endian, i-signal-type=PRIMITIVE, init-value=constant-reference=Init_CAN4_Motor_In_Temp_Err, base-type=uint8, implementation-data-type=uint8, transfer-property=TRIGGERED-ON-CHANGE
          signal CAN4_Motor_Out_Temp: start 119, 8 bit, big-endian, i-signal-type=PRIMITIVE, init-value=constant-reference=Init_CAN4_Motor_Out_Temp, base-type=uint8, implementation-data-type=uint8, transfer-property=PENDING
          signal CAN4_Motor_Out_Temp_Err: start 177, 2 bit, big-endian, i-signal-type=PRIMITIVE, init-value=constant-reference=Init_CAN4_Motor_Out_Temp_Err, base-type=uint8, implementation-data-type=uint8, transfer-property=TRIGGERED-ON-CHANGE
          signal CAN4_PT_High_P: start 19, 12 bit, big-endian, i-signal-type=PRIMITIVE, init-value=constant-reference=Init_CAN4_PT_High_P, base-type=uint16, implementation-data-type=uint16, transfer-property=PENDING
          signal CAN4_PT_High_P_Err: start 171, 2 bit, big-endian, i-signal-type=PRIMITIVE, init-value=constant-reference=Init_CAN4_PT_High_P_Err, base-type=uint8, implementation-data-type=uint8, transfer-property=TRIGGERED-ON-CHANGE
          signal CAN4_PT_High_T: start 39, 8 bit, big-endian, i-signal-type=PRIMITIVE, init-value=constant-reference=Init_CAN4_PT_High_T, base-type=uint8, implementation-data-type=uint8, transfer-property=PENDING
          signal CAN4_PT_High_Tact: start 7, 8 bit, big-endian, i-signal-type=PRIMITIVE, init-value=constant-reference=Init_CAN4_PT_High_Tact, base-type=uint8, implementation-data-type=uint8, transfer-property=PENDING
          signal CAN4_PT_High_Tact_Err: start 173, 2 bit, big-endian, i-signal-type=PRIMITIVE, init-value=constant-reference=Init_CAN4_PT_High_Tact_Err, base-type=uint8, implementation-data-type=uint8, transfer-property=TRIGGERED-ON-CHANGE
          signal CAN4_PT_Low_P1: start 67, 12 bit, big-endian, i-signal-type=PRIMITIVE, init-value=constant-reference=Init_CAN4_PT_Low_P1, base-type=uint16, implementation-data-type=uint16, transfer-property=PENDING
          signal CAN4_PT_Low_P1_Err: start 179, 2 bit, big-endian, i-signal-type=PRIMITIVE, init-value=constant-reference=Init_CAN4_PT_Low_P1_Err, base-type=uint8, implementation-data-type=uint8, transfer-property=TRIGGERED-ON-CHANGE
          signal CAN4_PT_Low_P2: start 43, 12 bit, big-endian, i-signal-type=PRIMITIVE, init-value=constant-reference=Init_CAN4_PT_Low_P2, base-type=uint16, implementation-data-type=uint16, transfer-property=PENDING
          signal CAN4_PT_Low_P2_Err: start 183, 2 bit, big-endian, i-signal-type=PRIMITIVE, init-value=constant-reference=Init_CAN4_PT_Low_P2_Err, base-type=uint8, implementation-data-type=uint8, transfer-property=TRIGGERED-ON-CHANGE
          signal CAN4_PT_Low_T1: start 87, 8 bit, big-endian, i-signal-type=PRIMITIVE, init-value=constant-reference=Init_CAN4_PT_Low_T1, base-type=uint8, implementation-data-type=uint8, transfer-property=PENDING
          signal CAN4_PT_Low_T1_Err: start 181, 2 bit, big-endian, i-signal-type=PRIMITIVE, init-value=constant-reference=Init_CAN4_PT_Low_T1_Err, base-type=uint8, implementation-data-type=uint8, transfer-property=TRIGGERED-ON-CHANGE
          signal CAN4_PT_Low_T2: start 63, 8 bit, big-endian, i-signal-type=PRIMITIVE, init-value=constant-reference=Init_CAN4_PT_Low_T2, base-type=uint8, implementation-data-type=uint8, transfer-property=PENDING
          signal CAN4_PT_Low_T2_Err: start 169, 2 bit, big-endian, i-signal-type=PRIMITIVE, init-value=constant-reference=Init_CAN4_PT_Low_T2_Err, base-type=uint8, implementation-data-type=uint8, transfer-property=TRIGGERED-ON-CHANGE
          signal CAN4_SOTXV_Err: start 167, 2 bit, big-endian, i-signal-type=PRIMITIVE, init-value=constant-reference=Init_CAN4_SOTXV_Err, base-type=uint8, implementation-data-type=uint8, transfer-property=TRIGGERED-ON-CHANGE
          signal CAN4_SOV1_Err: start 175, 2 bit, big-endian, i-signal-type=PRIMITIVE, init-value=constant-reference=Init_CAN4_SOV1_Err, base-type=uint8, implementation-data-type=uint8, transfer-property=TRIGGERED-ON-CHANGE
          signal CAN4_SOV2_Err: start 161, 2 bit, big-endian, i-signal-type=PRIMITIVE, init-value=constant-reference=Init_CAN4_SOV2_Err, base-type=uint8, implementation-data-type=uint8, transfer-property=TRIGGERED-ON-CHANGE
          signal CAN4_SOV3_Err: start 163, 2 bit, big-endian, i-signal-type=PRIMITIVE, init-value=constant-reference=Init_CAN4_SOV3_Err, base-type=uint8, implementation-data-type=uint8, transfer-property=TRIGGERED-ON-CHANGE
          signal CAN4_TWV_Err: start 137, 2 bit, big-endian, i-signal-type=PRIMITIVE, init-value=constant-reference=Init_CAN4_TWV_Err, base-type=uint8, implementation-data-type=uint8, transfer-property=TRIGGERED-ON-CHANGE
          signal CAN4_Tamb: start 95, 8 bit, big-endian, i-signal-type=PRIMITIVE, init-value=constant-reference=Init_CAN4_Tamb, base-type=uint8, implementation-data-type=uint8, transfer-property=PENDING
          signal CAN4_Tamb_Err: start 185, 2 bit, big-endian, i-signal-type=PRIMITIVE, init-value=constant-reference=Init_CAN4_Tamb_Err, base-type=uint8, implementation-data-type=uint8, transfer-property=TRIGGERED-ON-CHANGE
          signal CAN4_WPTC_Err: start 145, 2 bit, big-endian, i-signal-type=PRIMITIVE, init-value=constant-reference=Init_CAN4_WPTC_Err, base-type=uint8, implementation-data-type=uint8, transfer-property=TRIGGERED-ON-CHANGE
